VERSION "HNNBNNNYNNNNNNNNNNNNNNNNNNNNNNNNNNNNNNNNNN/4/%%%/4/'%**4NNN///"

NS_ :

BS_:

BU_: Airbag Allrad_Haldex BAP_Tester DCC_Gen3 EBKV_MQBW ESC_MQBW Gateway_Max Lenkhilfe_REPS

BO_ 2463978866 Gateway_81: 32 Gateway_Max
 SG_ LDW_02_alt : 0|1@1+ (1.0,0.0) [0.0|1] ""  Airbag
 SG_ TA_01_alt : 1|1@1+ (1.0,0.0) [0.0|1] ""  Airbag
 SG_ RDK_11_alt : 2|1@1+ (1.0,0.0) [0.0|1] ""  Airbag
 SG_ PLA_04_alt : 3|1@1+ (1.0,0.0) [0.0|1] ""  Airbag
 SG_ TPA_02_alt : 4|1@1+ (1.0,0.0) [0.0|1] ""  Airbag
 SG_ ARA_Status_01_alt : 5|1@1+ (1.0,0.0) [0.0|1] ""  Airbag
 SG_ WBA_05_alt : 6|1@1+ (1.0,0.0) [0.0|1] ""  Airbag
 SG_ KLR_01_alt : 7|1@1+ (1.0,0.0) [0.0|1] ""  Airbag
 SG_ Kamera_Status_alt : 8|1@1+ (1.0,0.0) [0.0|1] ""  Airbag
 SG_ RDK_02_alt : 10|1@1+ (1.0,0.0) [0.0|1] ""  Airbag
 SG_ PLA_06_alt : 11|1@1+ (1.0,0.0) [0.0|1] ""  Airbag
 SG_ LDW_Texte : 32|4@1+ (1.0,0.0) [0.0|15] ""  Airbag
 SG_ LDW_Lernmodus_seitenabhaengig : 36|4@1+ (1.0,0.0) [0.0|15] ""  Airbag
 SG_ LDW_Status_LED_gelb : 40|1@1+ (1.0,0.0) [0.0|1] ""  Airbag
 SG_ LDW_Status_LED_gruen : 41|1@1+ (1.0,0.0) [0.0|1] ""  Airbag
 SG_ TA_Status : 42|2@1+ (1.0,0.0) [0.0|3] ""  Airbag
 SG_ WBA_Status_AWU : 44|4@1+ (1.0,0.0) [0.0|15] ""  Airbag
 SG_ PLAIPA_PaCo_FunctionState : 48|5@1+ (1.0,0.0) [0.0|31] ""  Airbag
 SG_ PLAIPA_PaCo_MainState : 53|3@1+ (1.0,0.0) [0.0|7] ""  Airbag
 SG_ KLR_Touchauswertung : 56|4@1+ (1.0,0.0) [0.0|15] ""  Airbag
 SG_ TPA_Status : 60|4@1+ (1.0,0.0) [0.0|15] ""  Airbag
 SG_ ARA_Status : 64|4@1+ (1.0,0.0) [0.0|15] ""  Airbag
 SG_ TA_Texte_02 : 68|4@1+ (1.0,0.0) [0.0|15] ""  Airbag
 SG_ TA_Texte : 72|3@1+ (1.0,0.0) [0.0|7] ""  Airbag
 SG_ TA_Handsoff_LED : 75|2@1+ (1.0,0.0) [0.0|3] ""  Airbag
 SG_ TA_Fehler : 77|3@1+ (1.0,0.0) [0.0|7] ""  Airbag
 SG_ TA_aktiv_HMI : 80|2@1+ (1.0,0.0) [0.0|3] ""  Airbag
 SG_ TA_Spurwechsel : 82|3@1+ (1.0,0.0) [0.0|7] ""  Airbag
 SG_ VZE_Status_EDR : 85|3@1+ (1.0,0.0) [0.0|7] ""  Airbag
 SG_ TPMS_WarnLmpStP : 88|1@1+ (1.0,0.0) [0.0|1] ""  Airbag
 SG_ RDK_FMVSS138_Lampe : 101|1@1+ (1.0,0.0) [0.0|1] ""  Airbag
 SG_ LDW_Status_Anzeige : 102|3@1+ (1.0,0.0) [0.0|7] ""  Airbag
 SG_ TPMS_WarnLmpStMil : 105|1@1+ (1.0,0.0) [0.0|1] ""  Airbag
 SG_ RDK_FMVSS138_MIL : 106|1@1+ (1.0,0.0) [0.0|1] ""  Airbag
 SG_ RA_Status : 107|4@1+ (1.0,0.0) [0.0|15] ""  Airbag

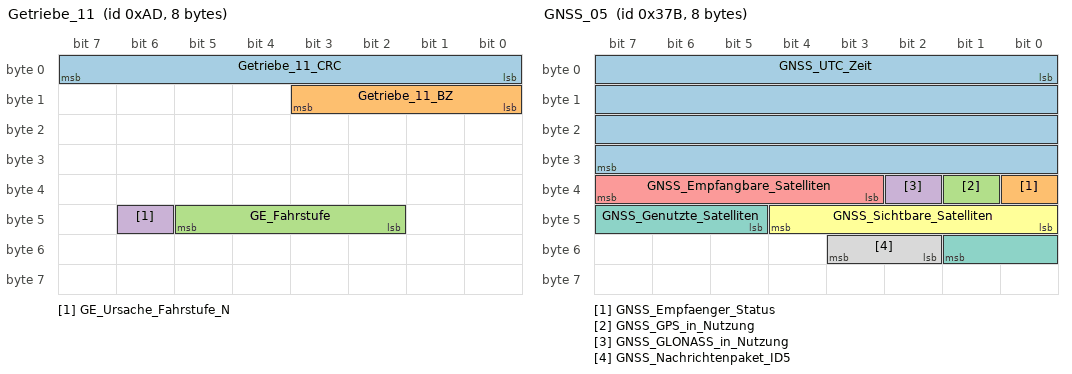
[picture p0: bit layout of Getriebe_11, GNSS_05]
BO_ 173 Getriebe_11: 8 Gateway_Max
 SG_ Getriebe_11_CRC : 0|8@1+ (1,0) [0|255] ""  Vector__XXX
 SG_ Getriebe_11_BZ : 8|4@1+ (1,0) [0|15] ""  Vector__XXX
 SG_ GE_Fahrstufe : 42|4@1+ (1.0,0.0) [0.0|15] ""  Airbag,EBKV_MQBW
 SG_ GE_Ursache_Fahrstufe_N : 46|1@1+ (1.0,0.0) [0.0|1] ""  Vector__XXX

BO_ 270 Getriebe_50: 48 Gateway_Max
 SG_ Getriebe_50_CRC : 0|8@1+ (1,0) [0|255] ""  ESC_MQBW
 SG_ Getriebe_50_BZ : 8|4@1+ (1,0) [0|15] ""  ESC_MQBW
 SG_ GE_MMom_Soll_02 : 12|10@1+ (1,-509) [-509|509] ""  Vector__XXX
 SG_ GE_MMom_Vorhalt_02 : 22|10@1+ (1,-509) [-509|509] ""  Vector__XXX
 SG_ GE_Uefkt : 32|10@1+ (0.1,0) [0.0|102.2] ""  EBKV_MQBW,ESC_MQBW
 SG_ GE2_Fahrstufe : 42|4@1+ (1.0,0.0) [0.0|15] ""  EBKV_MQBW,ESC_MQBW
 SG_ GE2_Ursache_Fahrstufe_N : 46|1@1+ (1.0,0.0) [0.0|1] ""  ESC_MQBW
 SG_ GE_Schaltablauf : 47|2@1+ (1.0,0.0) [0.0|3] ""  Allrad_Haldex,EBKV_MQBW,ESC_MQBW
 SG_ GE_Uefkt_unplausibel : 49|1@1+ (1.0,0.0) [0.0|1] ""  Vector__XXX
 SG_ GE_MMom_Status_02 : 50|3@1+ (1.0,0.0) [0.0|7] ""  Vector__XXX
 SG_ GE_Status_Kraftschluss : 53|3@1+ (1.0,0.0) [0.0|7] ""  ESC_MQBW
 SG_ GE_MMom_Status : 56|2@1+ (1.0,0.0) [0.0|3] ""  Vector__XXX
 SG_ GE_Freig_MMom_Vorhalt : 58|1@1+ (1.0,0.0) [0.0|1] ""  Vector__XXX
 SG_ GE_Verbot_Ausblendung : 59|1@1+ (1.0,0.0) [0.0|1] ""  Vector__XXX
 SG_ GE_Zielgang : 60|4@1+ (1.0,0.0) [0.0|15] ""  Allrad_Haldex,ESC_MQBW
 SG_ GE_Fahrstufenwunsch : 72|4@1+ (1.0,0.0) [0.0|15] ""  Vector__XXX
 SG_ GE_Drehzahlmesser_Daempfung : 76|1@1+ (1.0,0.0) [0.0|1] ""  Vector__XXX
 SG_ GE_Schubabschalt_Unt : 77|1@1+ (1.0,0.0) [0.0|1] ""  Vector__XXX
 SG_ GE_Freigabe_Synchro : 78|1@1+ (1.0,0.0) [0.0|1] ""  Vector__XXX
 SG_ GE_Synchro_Wunschdrehz : 79|9@1+ (25,0) [25|12750] "Unit_MinutInver"  Vector__XXX
 SG_ GE_Synchro_Zeit : 88|8@1+ (20,0) [0|5080] "Unit_MilliSecon"  Vector__XXX
 SG_ GE_Mom_Begr_Gradient : 96|8@1+ (10,0) [0|2540] "Unit_NewtoMeterPerSecon"  Vector__XXX
 SG_ GE_Anheb_Solldrehz_Leerlauf : 104|8@1+ (10,0) [0|2540] "Unit_MinutInver"  Vector__XXX
 SG_ GE_Aufnahmemoment : 112|10@1+ (1,-509) [-509|509] ""  Vector__XXX
 SG_ GE_Synchro_Status_02 : 122|4@1+ (1.0,0.0) [0.0|15] ""  Vector__XXX
 SG_ GE_StartStopp_Info : 140|2@1+ (1.0,0.0) [0.0|3] ""  Vector__XXX
 SG_ GE_Langfr_Schutzmom_02 : 142|9@1+ (1,0) [0|509] ""  Vector__XXX
 SG_ GE_Entkopplung_Status : 151|2@1+ (1.0,0.0) [0.0|3] ""  Vector__XXX
 SG_ GE_Verlustmoment : 160|8@1+ (1,0) [0|254] ""  ESC_MQBW
 SG_ GE_Anf_Zylabsch : 168|2@1+ (1.0,0.0) [0.0|3] ""  Vector__XXX
 SG_ GE_Grenzkriechmoment : 170|6@1+ (2,0) [0|122] ""  Vector__XXX
 SG_ GE_Eingangsdrehz : 176|14@1+ (1,0) [0|16381] "Unit_MinutInver"  Vector__XXX
 SG_ GE_Notlauf : 190|1@1+ (1.0,0.0) [0.0|1] ""  Vector__XXX
 SG_ GE_Freig_Langfr_Schutzmom : 191|1@1+ (1.0,0.0) [0.0|1] ""  Vector__XXX
 SG_ GE_HYB_Fehlerstatus : 204|2@1+ (1.0,0.0) [0.0|3] ""  Vector__XXX
 SG_ GE_HYB_DZ_Eingriff : 206|2@1+ (1.0,0.0) [0.0|3] ""  Vector__XXX
 SG_ GE_HYB_Freigabe_K0 : 208|1@1+ (1.0,0.0) [0.0|1] ""  Vector__XXX
 SG_ GE_HYB_MaxMomK0 : 209|2@1+ (1.0,0.0) [0.0|3] ""  Vector__XXX
 SG_ GE_HYB_Freig_VM_EM_Stop : 211|1@1+ (1.0,0.0) [0.0|1] ""  Vector__XXX
 SG_ GE_HYB_Wiederstart : 212|1@1+ (1.0,0.0) [0.0|1] ""  Vector__XXX
 SG_ GE_HYB_Filt_MomAufbau : 213|3@1+ (1.0,0.0) [0.0|7] ""  Vector__XXX
 SG_ GE_HYB_nK0 : 216|8@1+ (25,0) [0|6350] "Unit_MinutInver"  Vector__XXX
 SG_ GE_HYB_EM_KompMom : 224|7@1+ (2,0) [0|254] "Unit_NewtoMeter"  Vector__XXX
 SG_ GE_HYB_IstStatus_K0 : 231|2@1+ (1.0,0.0) [0.0|3] ""  ESC_MQBW
 SG_ GE_HYB_Wiederstartreserve : 233|7@1+ (2,0) [0|254] "Unit_NewtoMeter"  Vector__XXX
 SG_ GE_HYB_VM_Soll_Moment : 240|8@1+ (1.186,-50) [-50.000|250.058] "Unit_NewtoMeter"  Vector__XXX
 SG_ GE_HYB_Sportfaktor : 248|4@1+ (1.0,0.0) [0.0|15] ""  Vector__XXX
 SG_ GE_HYB_Freigabe_LL_Reg : 252|1@1+ (1.0,0.0) [0.0|1] ""  Vector__XXX
 SG_ GE_HYB_VM_akt_halten : 253|1@1+ (1.0,0.0) [0.0|1] ""  Vector__XXX
 SG_ GE_HYB_StartAnf : 254|1@1+ (1.0,0.0) [0.0|1] ""  Vector__XXX
 SG_ GE_HYB_VM_Startkontr : 255|1@1+ (1.0,0.0) [0.0|1] ""  Vector__XXX
 SG_ GE_Radmoment : 256|16@1+ (0.5,-16383) [-16383.0|16383.5] "Unit_NewtoMeter"  Vector__XXX
 SG_ GE_Abtriebsdrehzahl : 272|16@1+ (0.1,-3276.65) [-3276.65|3276.65] "Unit_MinutInver"  Vector__XXX
 SG_ GE_Eingangswellengradient : 288|16@1+ (0.25,-8191.5) [-8191.50|8191.75] "Unit_MeterInver"  Vector__XXX

BO_ 509 Getriebe_51: 32 Gateway_Max
 SG_ Getriebe_51_CRC : 0|8@1+ (1,0) [0|255] ""  ESC_MQBW
 SG_ Getriebe_51_BZ : 8|4@1+ (1,0) [0|15] ""  ESC_MQBW
 SG_ GE_OBD_AbsperrVent : 12|4@1+ (1.0,0.0) [0.0|15] ""  Vector__XXX
 SG_ GE_amax_moeglich : 16|9@1+ (0.024,-2.016) [-2.016|10.224] "Unit_MeterPerSeconSquar"  Vector__XXX
 SG_ GE_Charisma_FahrPr : 25|4@1+ (1.0,0.0) [0.0|15] ""  Vector__XXX
 SG_ GE_Charisma_Status : 29|2@1+ (1.0,0.0) [0.0|3] ""  Vector__XXX
 SG_ GE_Freigabe_Verfallsinfo_WFS : 31|1@1+ (1.0,0.0) [0.0|1] ""  Vector__XXX
 SG_ Freilauf_Charisma_FahrPr : 40|4@1+ (1.0,0.0) [0.0|15] ""  Vector__XXX
 SG_ Freilauf_Charisma_Status : 44|2@1+ (1.0,0.0) [0.0|3] ""  Vector__XXX
 SG_ GE_Freigabe_Info_WFS : 46|1@1+ (1.0,0.0) [0.0|1] ""  Vector__XXX
 SG_ GE_Sperr_Info_WFS : 47|1@1+ (1.0,0.0) [0.0|1] ""  Vector__XXX
 SG_ GE_Zustand_Kuppltemp : 48|2@1+ (1.0,0.0) [0.0|3] ""  Vector__XXX
 SG_ GE_Codierung_MSG : 50|1@1+ (1.0,0.0) [0.0|1] ""  Vector__XXX
 SG_ GE_LaunchControl : 51|1@1+ (1.0,0.0) [0.0|1] ""  Allrad_Haldex
 SG_ GE_Heizwunsch : 52|2@1+ (1.0,0.0) [0.0|3] ""  Vector__XXX
 SG_ GE_OBD_Status : 54|1@1+ (1.0,0.0) [0.0|1] ""  ESC_MQBW
 SG_ GE_LFR_Adaption : 55|1@1+ (1.0,0.0) [0.0|1] ""  Vector__XXX
 SG_ GE_Sumpftemperatur : 56|8@1+ (1,-58) [-58|196] "Unit_DegreCelsi"  Vector__XXX
 SG_ GE_Schleuderoeltemperatur : 64|8@1+ (1,-58) [-58|195] "Unit_DegreCelsi"  Vector__XXX
 SG_ GE_Weckleitung_aktiv : 72|1@1+ (1.0,0.0) [0.0|1] ""  Vector__XXX
 SG_ GE_Fahrprogramm : 76|4@1+ (1.0,0.0) [0.0|15] ""  Vector__XXX
 SG_ GE_TippZustand : 80|2@1+ (1.0,0.0) [0.0|3] ""  Vector__XXX
 SG_ GE_Freilauf_Status : 82|3@1+ (1.0,0.0) [0.0|7] ""  Allrad_Haldex,ESC_MQBW
 SG_ GE_Grundeinstellung : 85|1@1+ (1.0,0.0) [0.0|1] ""  Vector__XXX
 SG_ GE_Anschleppstart_Freigabe : 86|1@1+ (1.0,0.0) [0.0|1] ""  Vector__XXX
 SG_ GE_Strombedarf_erh : 87|1@1+ (1.0,0.0) [0.0|1] ""  Vector__XXX
 SG_ GE_Parken_WFS_Status : 88|2@1+ (1.0,0.0) [0.0|3] ""  Vector__XXX
 SG_ FSA_Fehlerstatus_Parksperre : 90|2@1+ (1.0,0.0) [0.0|3] ""  EBKV_MQBW
 SG_ GE_SpannungsAnf : 97|2@1+ (1.0,0.0) [0.0|3] ""  Vector__XXX
 SG_ GE_QBit_Sumpftemperatur : 99|1@1+ (1.0,0.0) [0.0|1] ""  Vector__XXX
 SG_ GE_Grundeinstell_Drehrichtung_EM : 100|1@1+ (1.0,0.0) [0.0|1] ""  Vector__XXX
 SG_ GE_Veto_Rollfaehigkeit : 101|1@1+ (1.0,0.0) [0.0|1] ""  Vector__XXX
 SG_ GE_Parken_beibehalten_HMS : 102|2@1+ (1.0,0.0) [0.0|3] ""  ESC_MQBW
 SG_ GE_Anforderung_HMS : 104|3@1+ (1.0,0.0) [0.0|7] ""  ESC_MQBW
 SG_ GE_Betaetigung_Hold : 107|1@1+ (1.0,0.0) [0.0|1] ""  Vector__XXX

BO_ 891 GNSS_05: 8 Gateway_Max
 SG_ GNSS_UTC_Zeit : 0|32@1+ (1,0) [1|4294967295] "Unit_Secon"  Airbag
 SG_ GNSS_Empfaenger_Status : 32|1@1+ (1.0,0.0) [0.0|1] ""  Vector__XXX
 SG_ GNSS_GPS_in_Nutzung : 33|1@1+ (1.0,0.0) [0.0|1] ""  Vector__XXX
 SG_ GNSS_GLONASS_in_Nutzung : 34|1@1+ (1.0,0.0) [0.0|1] ""  Vector__XXX
 SG_ GNSS_Empfangbare_Satelliten : 35|5@1+ (1,0) [1|30] "Unit_None"  Vector__XXX
 SG_ GNSS_Sichtbare_Satelliten : 40|5@1+ (1,0) [1|30] "Unit_None"  Vector__XXX
 SG_ GNSS_Genutzte_Satelliten : 45|5@1+ (1,0) [1|30] "Unit_None"  Vector__XXX
 SG_ GNSS_Nachrichtenpaket_ID5 : 50|2@1+ (1,0) [0|3] "Unit_Bit"  Vector__XXX

BO_ 771 HCA_03: 24 Gateway_Max
 SG_ HCA_QFK_AnfStat : 12|4@1+ (1.0,0.0) [0.0|15] ""  Lenkhilfe_REPS
 SG_ HCA_QFK_Spuerb : 16|8@1+ (0.4,0) [0.0|100.0] "Unit_PerCent"  Lenkhilfe_REPS
 SG_ HCA_QFK_KruemmSoll : 24|15@1+ (0.0000067,0) [0E-7|0.2195389] "Unit_MeterInver"  Lenkhilfe_REPS
 SG_ HCA_QFK_KruemmSoll_VZ : 39|1@1+ (1.0,0.0) [0.0|1] ""  Lenkhilfe_REPS
 SG_ HCA_QFK_Signal1 : 40|10@1+ (1,0) [0|1023] ""  Lenkhilfe_REPS
 SG_ HCA_QFK_Art1 : 50|3@1+ (1,0) [0|7] ""  Lenkhilfe_REPS
 SG_ HCA_QFK_Art2 : 53|3@1+ (1,0) [0|7] ""  Lenkhilfe_REPS
 SG_ HCA_QFK_Signal2 : 56|10@1+ (1,0) [0|1023] ""  Lenkhilfe_REPS
 SG_ HCA_03_Sendestatus : 66|1@1+ (1.0,0.0) [0.0|1] ""  Lenkhilfe_REPS
 SG_ HCA_QFK_KrSoll_VZ : 67|1@1+ (1.0,0.0) [0.0|1] ""  Lenkhilfe_REPS
 SG_ HCA_QFK_KrSoll : 128|16@1+ (0.0000067,0) [0E-7|0.4390778] "Unit_MeterInver"  Lenkhilfe_REPS
 SG_ SOK_HCA_03_Signatur : 144|48@1+ (1,0) [0|281474976710655] "Unit_None"  Vector__XXX

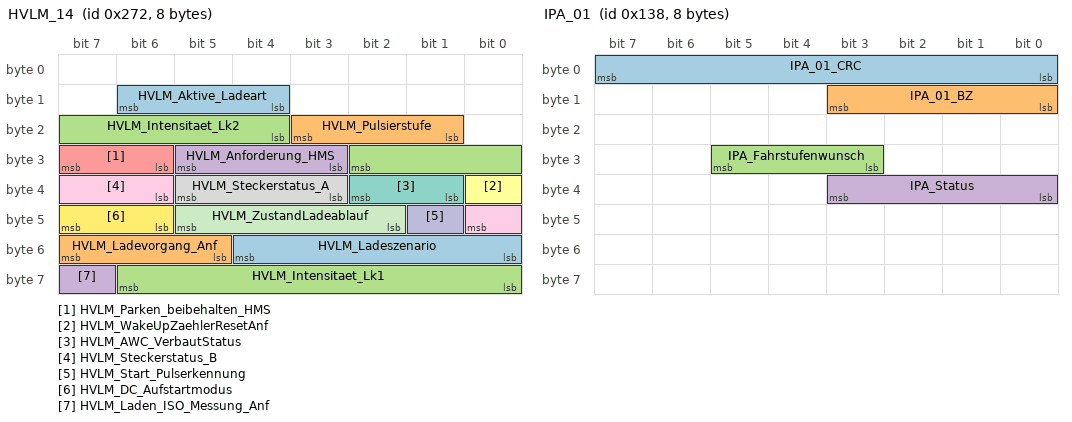
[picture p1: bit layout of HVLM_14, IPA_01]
BO_ 626 HVLM_14: 8 Gateway_Max
 SG_ HVLM_Aktive_Ladeart : 12|3@1+ (1.0,0.0) [0.0|7] ""  Vector__XXX
 SG_ HVLM_Pulsierstufe : 17|3@1+ (1.0,0.0) [0.0|7] ""  Vector__XXX
 SG_ HVLM_Intensitaet_Lk2 : 20|7@1+ (1,0) [0|100] "Unit_PerCent"  Vector__XXX
 SG_ HVLM_Anforderung_HMS : 27|3@1+ (1.0,0.0) [0.0|7] ""  ESC_MQBW
 SG_ HVLM_Parken_beibehalten_HMS : 30|2@1+ (1.0,0.0) [0.0|3] ""  ESC_MQBW
 SG_ HVLM_WakeUpZaehlerResetAnf : 32|1@1+ (1.0,0.0) [0.0|1] ""  Vector__XXX
 SG_ HVLM_AWC_VerbautStatus : 33|2@1+ (1.0,0.0) [0.0|3] ""  Vector__XXX
 SG_ HVLM_Steckerstatus_A : 35|3@1+ (1.0,0.0) [0.0|7] ""  Vector__XXX
 SG_ HVLM_Steckerstatus_B : 38|3@1+ (1.0,0.0) [0.0|7] ""  Vector__XXX
 SG_ HVLM_Start_Pulserkennung : 41|1@1+ (1.0,0.0) [0.0|1] ""  Vector__XXX
 SG_ HVLM_ZustandLadeablauf : 42|4@1+ (1.0,0.0) [0.0|15] ""  Vector__XXX
 SG_ HVLM_DC_Aufstartmodus : 46|2@1+ (1.0,0.0) [0.0|3] ""  Vector__XXX
 SG_ HVLM_Ladeszenario : 48|5@1+ (1.0,0.0) [0.0|31] ""  Vector__XXX
 SG_ HVLM_Ladevorgang_Anf : 53|3@1+ (1.0,0.0) [0.0|7] ""  Vector__XXX
 SG_ HVLM_Intensitaet_Lk1 : 56|7@1+ (1,0) [0|100] "Unit_PerCent"  Vector__XXX
 SG_ HVLM_Laden_ISO_Messung_Anf : 63|1@1+ (1.0,0.0) [0.0|1] ""  Vector__XXX

BO_ 2589283966 IMU_03: 8 Airbag
 SG_ IMU_StObd_StFail1 : 12|1@1+ (1.0,0.0) [0.0|1] ""  ESC_MQBW
 SG_ IMU_StObd_StFail2 : 13|1@1+ (1.0,0.0) [0.0|1] ""  ESC_MQBW
 SG_ IMU_StObd_StFail3 : 14|1@1+ (1.0,0.0) [0.0|1] ""  ESC_MQBW
 SG_ IMU_StObd_StFail4 : 15|1@1+ (1.0,0.0) [0.0|1] ""  ESC_MQBW
 SG_ IMU_StObd_StFail5 : 16|1@1+ (1.0,0.0) [0.0|1] ""  ESC_MQBW
 SG_ IMU_StObd_StFail6 : 17|1@1+ (1.0,0.0) [0.0|1] ""  ESC_MQBW
 SG_ IMU_StObd_StFail7 : 18|1@1+ (1.0,0.0) [0.0|1] ""  ESC_MQBW
 SG_ IMU_StObd_StFail8 : 19|1@1+ (1.0,0.0) [0.0|1] ""  ESC_MQBW
 SG_ IMU_StObd_StFail9 : 20|1@1+ (1.0,0.0) [0.0|1] ""  ESC_MQBW
 SG_ IMU_StObd_StFail10 : 21|1@1+ (1.0,0.0) [0.0|1] ""  ESC_MQBW
 SG_ IMU_StObd_StFail11 : 22|1@1+ (1.0,0.0) [0.0|1] ""  ESC_MQBW
 SG_ IMU_StObd_StChk1 : 23|1@1+ (1.0,0.0) [0.0|1] ""  ESC_MQBW
 SG_ IMU_StObd_StChk2 : 24|1@1+ (1.0,0.0) [0.0|1] ""  ESC_MQBW
 SG_ IMU_StObd_StChk3 : 25|1@1+ (1.0,0.0) [0.0|1] ""  ESC_MQBW
 SG_ IMU_StObd_StChk4 : 26|1@1+ (1.0,0.0) [0.0|1] ""  ESC_MQBW
 SG_ IMU_StObd_StChk5 : 27|1@1+ (1.0,0.0) [0.0|1] ""  ESC_MQBW
 SG_ IMU_StObd_StChk6 : 28|1@1+ (1.0,0.0) [0.0|1] ""  ESC_MQBW
 SG_ IMU_StObd_StChk7 : 29|1@1+ (1.0,0.0) [0.0|1] ""  ESC_MQBW
 SG_ IMU_StObd_StChk8 : 30|1@1+ (1.0,0.0) [0.0|1] ""  ESC_MQBW
 SG_ IMU_StObd_StChk9 : 31|1@1+ (1.0,0.0) [0.0|1] ""  ESC_MQBW
 SG_ IMU_StObd_StChk10 : 32|1@1+ (1.0,0.0) [0.0|1] ""  ESC_MQBW
 SG_ IMU_StObd_StChk11 : 33|1@1+ (1.0,0.0) [0.0|1] ""  ESC_MQBW

BO_ 182 IMU_05: 32 Airbag
 SG_ IMU_05_CRC : 0|8@1+ (1,0) [0|255] ""  ESC_MQBW,Gateway_Max
 SG_ IMU_05_BZ : 8|4@1+ (1,0) [0|15] ""  ESC_MQBW,Gateway_Max
 SG_ IMU_ALat_Qlfr : 12|4@1+ (1.0,0.0) [0.0|15] ""  ESC_MQBW,Gateway_Max
 SG_ IMU_ALat : 16|16@1+ (0.005,-163.84) [-163.835|163.825] "Unit_MeterPerSeconSquar"  ESC_MQBW,Gateway_Max
 SG_ IMU_ALgt : 32|16@1+ (0.005,-163.84) [-163.835|163.825] "Unit_MeterPerSeconSquar"  EBKV_MQBW,ESC_MQBW,Gateway_Max
 SG_ IMU_ALgt_Qlfr : 48|4@1+ (1.0,0.0) [0.0|15] ""  EBKV_MQBW,ESC_MQBW,Gateway_Max
 SG_ IMU_PitchRate_Qlfr : 52|4@1+ (1.0,0.0) [0.0|15] ""  Gateway_Max
 SG_ IMU_PitchRate : 56|16@1+ (0.01,-327.68) [-327.67|327.65] "Unit_DegreOfArcPerSecon"  DCC_Gen3,Gateway_Max
 SG_ IMU_AVert : 72|16@1+ (0.005,-163.84) [-163.835|163.825] "Unit_MeterPerSeconSquar"  DCC_Gen3,Gateway_Max
 SG_ IMU_AVert_Qlfr : 88|4@1+ (1.0,0.0) [0.0|15] ""  Gateway_Max
 SG_ IMU_YawRate_Qlfr : 92|4@1+ (1.0,0.0) [0.0|15] ""  ESC_MQBW,Gateway_Max
 SG_ IMU_YawRate : 96|16@1+ (0.01,-327.68) [-327.67|327.65] "Unit_DegreOfArcPerSecon"  ESC_MQBW,Gateway_Max
 SG_ IMU_RollRate : 112|16@1+ (0.01,-327.68) [-327.67|327.65] "Unit_DegreOfArcPerSecon"  DCC_Gen3,ESC_MQBW,Gateway_Max
 SG_ IMU_RollRate_Qlfr : 128|4@1+ (1.0,0.0) [0.0|15] ""  ESC_MQBW,Gateway_Max
 SG_ IMU_MeasurementTimeLow : 150|10@1+ (1,0) [0|999] "Unit_MilliSecon"  Gateway_Max
 SG_ IMU_MeasurementTimeHigh : 160|32@1+ (1,0) [0|4294967294] "Unit_Secon"  Gateway_Max
 SG_ SOK_IMU_05_Signatur : 192|64@1+ (1,0) [0|18446744073709551615] "Unit_None"  Gateway_Max

BO_ 312 IPA_01: 8 Gateway_Max
 SG_ IPA_01_CRC : 0|8@1+ (1,0) [0|255] ""  ESC_MQBW
 SG_ IPA_01_BZ : 8|4@1+ (1,0) [0|15] ""  ESC_MQBW
 SG_ IPA_Fahrstufenwunsch : 27|3@1+ (1.0,0.0) [0.0|7] ""  Vector__XXX
 SG_ IPA_Status : 32|4@1+ (1.0,0.0) [0.0|15] ""  ESC_MQBW

BO_ 2527679583 IPA_02: 8 Gateway_Max
 SG_ IPA_02_CRC : 0|8@1+ (1,0) [0|255] ""  Vector__XXX
 SG_ IPA_02_BZ : 8|4@1+ (1,0) [0|15] ""  Vector__XXX
 SG_ IPA_PL_Anzeige_links : 12|2@1+ (1.0,0.0) [0.0|3] ""  Vector__XXX
 SG_ IPA_PL_Anzeige_rechts : 14|2@1+ (1.0,0.0) [0.0|3] ""  Vector__XXX
 SG_ Parken_Seitenspiegel_Anf : 20|2@1+ (1.0,0.0) [0.0|3] ""  Vector__XXX
 SG_ Parken_ZV_Schliessen : 22|2@1+ (1.0,0.0) [0.0|3] ""  Vector__XXX
 SG_ Parken_aktives_System_02 : 24|5@1+ (1.0,0.0) [0.0|31] ""  ESC_MQBW
 SG_ Parken_ZR_Sondermodus_Anf : 29|2@1+ (1.0,0.0) [0.0|3] ""  Vector__XXX
 SG_ Parken_Schluesselsuche_Anf : 31|1@1+ (1.0,0.0) [0.0|1] ""  Vector__XXX
 SG_ Parken_FFB_LED_Anf : 32|2@1+ (1.0,0.0) [0.0|3] ""  Vector__XXX
 SG_ Parken_Wegfahrsperren_Anf : 34|2@1+ (1.0,0.0) [0.0|3] ""  Vector__XXX
 SG_ Parken_Aktivierungslicht_Anf : 36|1@1+ (1.0,0.0) [0.0|1] ""  Vector__XXX
 SG_ Parken_Fahrtrichtungslicht_Anf : 37|2@1+ (1.0,0.0) [0.0|3] ""  Vector__XXX
 SG_ Parken_Lichtnachlauf_Anf : 39|1@1+ (1.0,0.0) [0.0|1] ""  Vector__XXX
 SG_ IPA_Akustik_PL_gefunden : 45|1@1+ (1.0,0.0) [0.0|1] ""  Vector__XXX
 SG_ Parken_Blinker_li_Anf : 46|1@1+ (1.0,0.0) [0.0|1] ""  Vector__XXX
 SG_ Parken_Blinker_re_Anf : 47|1@1+ (1.0,0.0) [0.0|1] ""  Vector__XXX
 SG_ Parken_Fahrerhinweise_Anf : 51|1@1+ (1.0,0.0) [0.0|1] ""  Vector__XXX
 SG_ Parken_Bestaetigungsblinken_Anf : 52|2@1+ (1.0,0.0) [0.0|3] ""  Vector__XXX
 SG_ Parken_Fahrbereitschaftlicht_Anf : 54|1@1+ (1.0,0.0) [0.0|1] ""  Vector__XXX
 SG_ Parken_Lichtsteuerung_Anf : 55|1@1+ (1.0,0.0) [0.0|1] ""  Vector__XXX
 SG_ IPA_Anf_Meldungen : 56|8@1+ (1.0,0.0) [0.0|255] ""  Vector__XXX

BO_ 1811 ISO_ABS_Req: 8 Gateway_Max
 SG_ ISO_ABS_Req_Data : 0|64@1+ (1.0,0.0) [0.0|18446744073709551615] ""  ESC_MQBW

BO_ 1917 ISO_ABS_Resp: 8 ESC_MQBW
 SG_ ISO_ABS_Resp_Data : 0|64@1+ (1.0,0.0) [0.0|18446744073709551615] ""  Gateway_Max

BO_ 1813 ISO_Airbag_01_Req: 8 Gateway_Max
 SG_ ISO_Airbag_01_Req_Data : 0|64@1+ (1.0,0.0) [0.0|18446744073709551615] ""  Airbag

BO_ 1919 ISO_Airbag_01_Resp: 8 Airbag
 SG_ ISO_Airbag_01_Resp_Data : 0|64@1+ (1.0,0.0) [0.0|18446744073709551615] ""  Gateway_Max

BO_ 1807 ISO_Allrad_Req: 8 Gateway_Max
 SG_ ISO_Allrad_Req_Data : 0|64@1+ (1.0,0.0) [0.0|18446744073709551615] ""  Allrad_Haldex

BO_ 1913 ISO_Allrad_Resp: 8 Allrad_Haldex
 SG_ ISO_Allrad_Resp_Data : 0|64@1+ (1.0,0.0) [0.0|18446744073709551615] ""  Gateway_Max

BO_ 1906 ISO_Daempfer_Req: 8 Gateway_Max
 SG_ ISO_Daempfer_Req_Data : 0|64@1+ (1.0,0.0) [0.0|18446744073709551615] ""  DCC_Gen3

BO_ 2012 ISO_Daempfer_Resp: 8 DCC_Gen3
 SG_ ISO_Daempfer_Resp_Data : 0|64@1+ (1.0,0.0) [0.0|18446744073709551615] ""  Gateway_Max

BO_ 1851 ISO_EBKV_Req: 8 Gateway_Max
 SG_ ISO_EBKV_Req_Data : 0|64@1+ (1.0,0.0) [0.0|18446744073709551615] ""  EBKV_MQBW

BO_ 1957 ISO_EBKV_Resp: 8 EBKV_MQBW
 SG_ ISO_EBKV_Resp_Data : 0|64@1+ (1.0,0.0) [0.0|18446744073709551615] ""  Gateway_Max

BO_ 1792 ISO_Funktionaler_Req_All: 8 Gateway_Max
 SG_ ISO_ALL_01_Req_Data : 0|64@1+ (1.0,0.0) [0.0|18446744073709551615] ""  Airbag,Allrad_Haldex,DCC_Gen3,EBKV_MQBW,ESC_MQBW,Lenkhilfe_REPS

BO_ 1810 ISO_Lenkhilfe_Req: 8 Gateway_Max
 SG_ ISO_Lenkhilfe_Req_Data : 0|64@1+ (1.0,0.0) [0.0|18446744073709551615] ""  Lenkhilfe_REPS

BO_ 1916 ISO_Lenkhilfe_Resp: 8 Lenkhilfe_REPS
 SG_ ISO_Lenkhilfe_Resp_Data : 0|64@1+ (1.0,0.0) [0.0|18446744073709551615] ""  Gateway_Max

BO_ 1822 ISO_Quersperre_Req: 8 Gateway_Max
 SG_ ISO_Quersperre_Req_Data : 0|64@1+ (1.0,0.0) [0.0|18446744073709551615] ""  Vector__XXX

BO_ 1928 ISO_Quersperre_Resp: 8 Vector__XXX
 SG_ ISO_Quersperre_Resp_Data : 0|64@1+ (1.0,0.0) [0.0|18446744073709551615] ""  Gateway_Max

BO_ 2621440019 ISOx_ABS_Req_FD: 64 Gateway_Max
 SG_ ISOx_ABS_Req_FD_Data : 0|512@1+ (1.0,0.0) [0.0|13407807929942597099574024998205846127479365820592393377723561443721764030073546976801874298166903427690031858186486050853753882811946569946433649006084095] ""  ESC_MQBW

BO_ 2621571091 ISOx_ABS_Resp_FD: 64 ESC_MQBW
 SG_ ISOx_ABS_Resp_FD_Data : 0|512@1+ (1.0,0.0) [0.0|13407807929942597099574024998205846127479365820592393377723561443721764030073546976801874298166903427690031858186486050853753882811946569946433649006084095] ""  Gateway_Max

BO_ 2621440021 ISOx_Airbag_01_Req_FD: 64 Gateway_Max
 SG_ ISOx_Airbag_01_Req_FD_Data : 0|512@1+ (1.0,0.0) [0.0|13407807929942597099574024998205846127479365820592393377723561443721764030073546976801874298166903427690031858186486050853753882811946569946433649006084095] ""  Airbag

BO_ 2621571093 ISOx_Airbag_01_Resp_FD: 64 Airbag
 SG_ ISOx_Airbag_01_Resp_FD_Data : 0|512@1+ (1.0,0.0) [0.0|13407807929942597099574024998205846127479365820592393377723561443721764030073546976801874298166903427690031858186486050853753882811946569946433649006084095] ""  Gateway_Max

BO_ 2621440015 ISOx_Allrad_Req_FD: 64 Gateway_Max
 SG_ ISOx_Allrad_Req_FD_Data : 0|512@1+ (1.0,0.0) [0.0|13407807929942597099574024998205846127479365820592393377723561443721764030073546976801874298166903427690031858186486050853753882811946569946433649006084095] ""  Allrad_Haldex

BO_ 2621571087 ISOx_Allrad_Resp_FD: 64 Allrad_Haldex
 SG_ ISOx_Allrad_Resp_FD_Data : 0|512@1+ (1.0,0.0) [0.0|13407807929942597099574024998205846127479365820592393377723561443721764030073546976801874298166903427690031858186486050853753882811946569946433649006084095] ""  Gateway_Max

BO_ 2621440114 ISOx_Daempfer_Req_FD: 64 Gateway_Max
 SG_ ISOx_Daempfer_Req_FD_Data : 0|512@1+ (1.0,0.0) [0.0|13407807929942597099574024998205846127479365820592393377723561443721764030073546976801874298166903427690031858186486050853753882811946569946433649006084095] ""  DCC_Gen3

BO_ 2621571186 ISOx_Daempfer_Resp_FD: 64 DCC_Gen3
 SG_ ISOx_Daempfer_Resp_FD_Data : 0|512@1+ (1.0,0.0) [0.0|13407807929942597099574024998205846127479365820592393377723561443721764030073546976801874298166903427690031858186486050853753882811946569946433649006084095] ""  Gateway_Max

BO_ 2621440059 ISOx_EBKV_Req_FD: 64 Gateway_Max
 SG_ ISOx_EBKV_Req_FD_Data : 0|512@1+ (1.0,0.0) [0.0|13407807929942597099574024998205846127479365820592393377723561443721764030073546976801874298166903427690031858186486050853753882811946569946433649006084095] ""  EBKV_MQBW

BO_ 2621571131 ISOx_EBKV_Resp_FD: 64 EBKV_MQBW
 SG_ ISOx_EBKV_Resp_FD_Data : 0|512@1+ (1.0,0.0) [0.0|13407807929942597099574024998205846127479365820592393377723561443721764030073546976801874298166903427690031858186486050853753882811946569946433649006084095] ""  Gateway_Max

BO_ 2621505536 ISOx_Funkt_Req_All_FD: 64 Gateway_Max
 SG_ ISOx_Funkt_Req_All_FD_Data : 0|512@1+ (1.0,0.0) [0.0|13407807929942597099574024998205846127479365820592393377723561443721764030073546976801874298166903427690031858186486050853753882811946569946433649006084095] ""  Airbag,Allrad_Haldex,DCC_Gen3,EBKV_MQBW,ESC_MQBW,Lenkhilfe_REPS

BO_ 2621440018 ISOx_Lenkhilfe_Req_FD: 64 Gateway_Max
 SG_ ISOx_Lenkhilfe_Req_FD_Data : 0|512@1+ (1.0,0.0) [0.0|13407807929942597099574024998205846127479365820592393377723561443721764030073546976801874298166903427690031858186486050853753882811946569946433649006084095] ""  Lenkhilfe_REPS

BO_ 2621571090 ISOx_Lenkhilfe_Resp_FD: 64 Lenkhilfe_REPS
 SG_ ISOx_Lenkhilfe_Resp_FD_Data : 0|512@1+ (1.0,0.0) [0.0|13407807929942597099574024998205846127479365820592393377723561443721764030073546976801874298166903427690031858186486050853753882811946569946433649006084095] ""  Gateway_Max

BO_ 2621440030 ISOx_Quersperre_Req_FD: 64 Gateway_Max
 SG_ ISOx_Quersperre_Req_FD_Data : 0|512@1+ (1.0,0.0) [0.0|13407807929942597099574024998205846127479365820592393377723561443721764030073546976801874298166903427690031858186486050853753882811946569946433649006084095] ""  Vector__XXX

BO_ 2621571102 ISOx_Quersperre_Resp_FD: 64 Vector__XXX
 SG_ ISOx_Quersperre_Resp_FD_Data : 0|512@1+ (1.0,0.0) [0.0|13407807929942597099574024998205846127479365820592393377723561443721764030073546976801874298166903427690031858186486050853753882811946569946433649006084095] ""  Gateway_Max

BO_ 2549874892 ISOx_TSplit_L_Req: 8 Gateway_Max
 SG_ ISOx_TSplit_L_Req_Data : 0|64@1+ (1.0,0.0) [0.0|18446744073709551615] ""  Vector__XXX

BO_ 2621440204 ISOx_TSplit_L_Req_FD: 64 Gateway_Max
 SG_ ISOx_TSplit_L_Req_FD_Data : 0|512@1+ (1.0,0.0) [0.0|13407807929942597099574024998205846127479365820592393377723561443721764030073546976801874298166903427690031858186486050853753882811946569946433649006084095] ""  Vector__XXX

BO_ 2550005964 ISOx_TSplit_L_Resp: 8 Vector__XXX
 SG_ ISOx_TSplit_L_Resp_Data : 0|64@1+ (1.0,0.0) [0.0|18446744073709551615] ""  Gateway_Max

BO_ 2621571276 ISOx_TSplit_L_Resp_FD: 64 Vector__XXX
 SG_ ISOx_TSplit_L_Resp_FD_Data : 0|512@1+ (1.0,0.0) [0.0|13407807929942597099574024998205846127479365820592393377723561443721764030073546976801874298166903427690031858186486050853753882811946569946433649006084095] ""  Gateway_Max

BO_ 2549874893 ISOx_TSplit_R_Req: 8 Gateway_Max
 SG_ ISOx_TSplit_R_Req_Data : 0|64@1+ (1.0,0.0) [0.0|18446744073709551615] ""  Vector__XXX

BO_ 2621440205 ISOx_TSplit_R_Req_FD: 64 Gateway_Max
 SG_ ISOx_TSplit_R_Req_FD_Data : 0|512@1+ (1.0,0.0) [0.0|13407807929942597099574024998205846127479365820592393377723561443721764030073546976801874298166903427690031858186486050853753882811946569946433649006084095] ""  Vector__XXX

BO_ 2550005965 ISOx_TSplit_R_Resp: 8 Vector__XXX
 SG_ ISOx_TSplit_R_Resp_Data : 0|64@1+ (1.0,0.0) [0.0|18446744073709551615] ""  Gateway_Max

BO_ 2621571277 ISOx_TSplit_R_Resp_FD: 64 Vector__XXX
 SG_ ISOx_TSplit_R_Resp_FD_Data : 0|512@1+ (1.0,0.0) [0.0|13407807929942597099574024998205846127479365820592393377723561443721764030073546976801874298166903427690031858186486050853753882811946569946433649006084095] ""  Gateway_Max

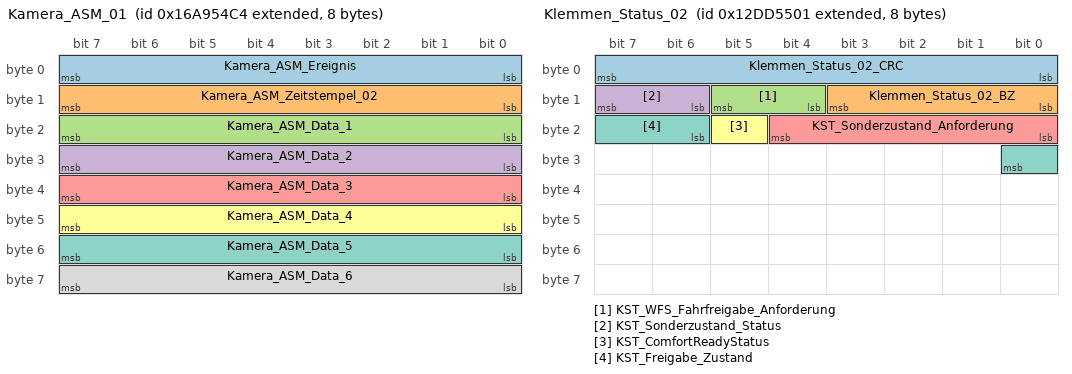
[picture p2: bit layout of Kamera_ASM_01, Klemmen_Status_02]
BO_ 2527679684 Kamera_ASM_01: 8 Gateway_Max
 SG_ Kamera_ASM_Ereignis : 0|8@1+ (1,0) [1|254] ""  Airbag
 SG_ Kamera_ASM_Zeitstempel_02 : 8|8@1+ (0.04,0) [0.00|10.16] "Unit_Secon"  Airbag
 SG_ Kamera_ASM_Data_1 : 16|8@1+ (1,0) [0|255] ""  Airbag
 SG_ Kamera_ASM_Data_2 : 24|8@1+ (1,0) [0|255] ""  Airbag
 SG_ Kamera_ASM_Data_3 : 32|8@1+ (1,0) [0|255] ""  Airbag
 SG_ Kamera_ASM_Data_4 : 40|8@1+ (1,0) [0|255] ""  Airbag
 SG_ Kamera_ASM_Data_5 : 48|8@1+ (1,0) [0|255] ""  Airbag
 SG_ Kamera_ASM_Data_6 : 56|8@1+ (1,0) [0|255] ""  Airbag

BO_ 960 Klemmen_Status_01: 4 Gateway_Max
 SG_ Klemmen_Status_01_CRC : 0|8@1+ (1,0) [0|255] ""  Airbag,EBKV_MQBW,ESC_MQBW
 SG_ Klemmen_Status_01_BZ : 8|4@1+ (1,0) [0|15] ""  Airbag,EBKV_MQBW,ESC_MQBW
 SG_ RSt_Fahrerhinweise : 12|4@1+ (1.0,0.0) [0.0|15] ""  Vector__XXX
 SG_ ZAS_Kl_S : 16|1@1+ (1.0,0.0) [0.0|1] ""  Airbag
 SG_ ZAS_Kl_15 : 17|1@1+ (1.0,0.0) [0.0|1] ""  Airbag,DCC_Gen3,EBKV_MQBW,ESC_MQBW,Lenkhilfe_REPS
 SG_ ZAS_Kl_X : 18|1@1+ (1.0,0.0) [0.0|1] ""  Vector__XXX
 SG_ ZAS_Kl_50_Startanforderung : 19|1@1+ (1.0,0.0) [0.0|1] ""  Vector__XXX
 SG_ BCM_Remotestart_Betrieb : 20|1@1+ (1.0,0.0) [0.0|1] ""  Vector__XXX
 SG_ ZAS_Kl_Infotainment : 21|1@1+ (1.0,0.0) [0.0|1] ""  Vector__XXX
 SG_ BCM_Remotestart_KL15_Anf : 22|1@1+ (1.0,0.0) [0.0|1] ""  Vector__XXX
 SG_ BCM_Remotestart_MO_Start : 23|1@1+ (1.0,0.0) [0.0|1] ""  Vector__XXX
 SG_ KST_Warn_P1_ZST_def : 24|1@1+ (1.0,0.0) [0.0|1] ""  Vector__XXX
 SG_ KST_Warn_P2_ZST_def : 25|1@1+ (1.0,0.0) [0.0|1] ""  Vector__XXX
 SG_ KST_Fahrerhinweis_1 : 26|1@1+ (1.0,0.0) [0.0|1] ""  Vector__XXX
 SG_ KST_Fahrerhinweis_2 : 27|1@1+ (1.0,0.0) [0.0|1] ""  Vector__XXX
 SG_ BCM_Ausparken_Betrieb : 28|1@1+ (1.0,0.0) [0.0|1] ""  Vector__XXX
 SG_ KST_Fahrerhinweis_4 : 29|1@1+ (1.0,0.0) [0.0|1] ""  Vector__XXX
 SG_ KST_Fahrerhinweis_5 : 30|1@1+ (1.0,0.0) [0.0|1] ""  Vector__XXX
 SG_ KST_Fahrerhinweis_6 : 31|1@1+ (1.0,0.0) [0.0|1] ""  Vector__XXX

BO_ 2463978753 Klemmen_Status_02: 8 Gateway_Max
 SG_ Klemmen_Status_02_CRC : 0|8@1+ (1,0) [0|255] ""  Vector__XXX
 SG_ Klemmen_Status_02_BZ : 8|4@1+ (1,0) [0|15] ""  Vector__XXX
 SG_ KST_WFS_Fahrfreigabe_Anforderung : 12|2@1+ (1.0,0.0) [0.0|3] ""  Vector__XXX
 SG_ KST_Sonderzustand_Status : 14|2@1+ (1.0,0.0) [0.0|3] ""  Airbag,EBKV_MQBW,ESC_MQBW
 SG_ KST_Sonderzustand_Anforderung : 16|5@1+ (1.0,0.0) [0.0|31] ""  Airbag,EBKV_MQBW,ESC_MQBW
 SG_ KST_ComfortReadyStatus : 21|1@1+ (1.0,0.0) [0.0|1] ""  Vector__XXX
 SG_ KST_Freigabe_Zustand : 22|3@1+ (1.0,0.0) [0.0|7] ""  Vector__XXX

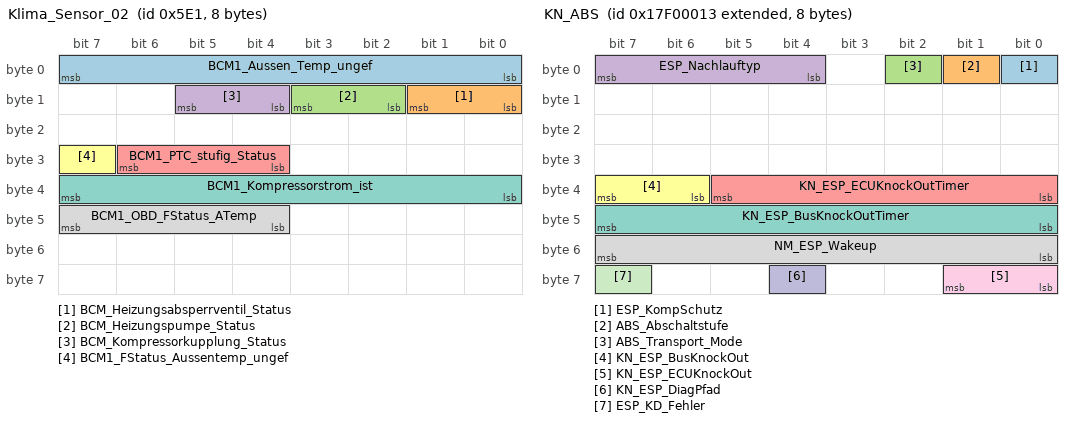
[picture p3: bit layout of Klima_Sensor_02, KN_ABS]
BO_ 1505 Klima_Sensor_02: 8 Gateway_Max
 SG_ BCM1_Aussen_Temp_ungef : 0|8@1+ (0.5,-50) [-50.0|76.0] "Unit_DegreCelsi"  Airbag,ESC_MQBW
 SG_ BCM_Heizungsabsperrventil_Status : 8|2@1+ (1.0,0.0) [0.0|3] ""  Vector__XXX
 SG_ BCM_Heizungspumpe_Status : 10|2@1+ (1.0,0.0) [0.0|3] ""  Vector__XXX
 SG_ BCM_Kompressorkupplung_Status : 12|2@1+ (1.0,0.0) [0.0|3] ""  Vector__XXX
 SG_ BCM1_PTC_stufig_Status : 28|3@1+ (1.0,0.0) [0.0|7] ""  Vector__XXX
 SG_ BCM1_FStatus_Aussentemp_ungef : 31|1@1+ (1.0,0.0) [0.0|1] ""  Airbag
 SG_ BCM1_Kompressorstrom_ist : 32|8@1+ (4,0) [0|1000] "Unit_MilliAmper"  Vector__XXX
 SG_ BCM1_OBD_FStatus_ATemp : 44|4@1+ (1.0,0.0) [0.0|15] ""  ESC_MQBW

BO_ 2549088275 KN_ABS: 8 ESC_MQBW
 SG_ ESP_KompSchutz : 0|1@1+ (1.0,0.0) [0.0|1] ""  Vector__XXX
 SG_ ABS_Abschaltstufe : 1|1@1+ (1.0,0.0) [0.0|1] ""  Vector__XXX
 SG_ ABS_Transport_Mode : 2|1@1+ (1.0,0.0) [0.0|1] ""  Vector__XXX
 SG_ ESP_Nachlauftyp : 4|4@1+ (1.0,0.0) [0.0|15] ""  Gateway_Max
 SG_ KN_ESP_ECUKnockOutTimer : 32|6@1+ (1,0) [0|62] "Unit_Minut"  Vector__XXX
 SG_ KN_ESP_BusKnockOut : 38|2@1+ (1.0,0.0) [0.0|3] ""  Vector__XXX
 SG_ KN_ESP_BusKnockOutTimer : 40|8@1+ (1,0) [0|254] ""  Vector__XXX
 SG_ NM_ESP_Wakeup : 48|8@1+ (1.0,0.0) [0.0|255] ""  Vector__XXX
 SG_ KN_ESP_ECUKnockOut : 56|2@1+ (1.0,0.0) [0.0|3] ""  Vector__XXX
 SG_ KN_ESP_DiagPfad : 60|1@1+ (1.0,0.0) [0.0|1] ""  Gateway_Max
 SG_ ESP_KD_Fehler : 63|1@1+ (1.0,0.0) [0.0|1] ""  Gateway_Max

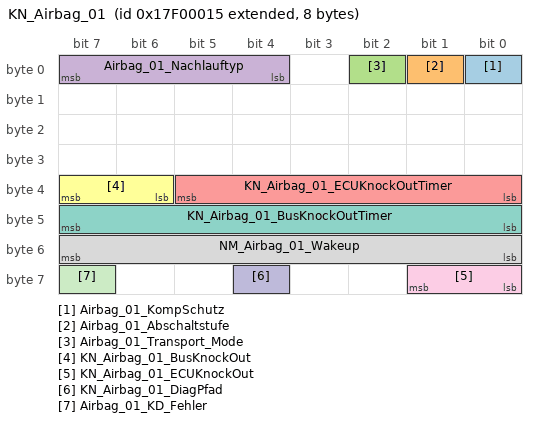
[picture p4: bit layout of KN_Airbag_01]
BO_ 2549088277 KN_Airbag_01: 8 Airbag
 SG_ Airbag_01_KompSchutz : 0|1@1+ (1.0,0.0) [0.0|1] ""  Vector__XXX
 SG_ Airbag_01_Abschaltstufe : 1|1@1+ (1.0,0.0) [0.0|1] ""  Vector__XXX
 SG_ Airbag_01_Transport_Mode : 2|1@1+ (1.0,0.0) [0.0|1] ""  Vector__XXX
 SG_ Airbag_01_Nachlauftyp : 4|4@1+ (1.0,0.0) [0.0|15] ""  Gateway_Max
 SG_ KN_Airbag_01_ECUKnockOutTimer : 32|6@1+ (1,0) [0|62] ""  Vector__XXX
 SG_ KN_Airbag_01_BusKnockOut : 38|2@1+ (1.0,0.0) [0.0|3] ""  Vector__XXX
 SG_ KN_Airbag_01_BusKnockOutTimer : 40|8@1+ (1,0) [0|254] ""  Vector__XXX
 SG_ NM_Airbag_01_Wakeup : 48|8@1+ (1.0,0.0) [0.0|255] ""  Vector__XXX
 SG_ KN_Airbag_01_ECUKnockOut : 56|2@1+ (1.0,0.0) [0.0|3] ""  Vector__XXX
 SG_ KN_Airbag_01_DiagPfad : 60|1@1+ (1.0,0.0) [0.0|1] ""  Gateway_Max
 SG_ Airbag_01_KD_Fehler : 63|1@1+ (1.0,0.0) [0.0|1] ""  Gateway_Max

CM_ BO_ 891 "Nachricht 5:
Empfängerstatus und UTC.";
CM_ BO_ 2527679583 "ehemals ZFAS_01";
CM_ BO_ 2621505536 "VWAG Diagnose funktionaler Request auf CANFD";
CM_ BO_ 960 "MQB";
CM_ BO_ 1505 "ab MQB 7.3";

CM_ SG_ 2463978866 ARA_Status "Status of ARA Controller";
CM_ SG_ 2463978866 ARA_Status_01_alt "Veraltet-Bit für ARA_Status_01";
CM_ SG_ 2463978866 KLR_01_alt "Veraltet-Bit für KLR_01";
CM_ SG_ 2463978866 KLR_Touchauswertung "Touchauswertung der KLR-Elektronik";
CM_ SG_ 2463978866 LDW_Lernmodus_seitenabhaengig "Signal dient zur Ansteuerung von Funktionsanzeigen im Mitteldisplay des Kombiinstruments für die Seitenabhänige Liniendetektion (neue Funktion ab D4)";
CM_ SG_ 2463978866 LDW_Status_Anzeige "Signal dient zur Ansteuerung von Funktionsanzeigen im Mitteldisplay des Kombiinstruments.";
CM_ SG_ 2463978866 LDW_Status_LED_gruen " ";
CM_ SG_ 2463978866 LDW_Texte "Bei Anzeige eines Fehlertextes im Kombi ertönt ein akustisches Signal";
CM_ SG_ 2463978866 PLA_04_alt "Veraltet-Bit für PLA_04";
CM_ SG_ 2463978866 PLA_06_alt "Veraltet-Bit für PLA_06";
CM_ SG_ 2463978866 PLAIPA_PaCo_FunctionState "Signalisierung des Funktionszustandes von PLA/IPA

0 ResumePossible: Wiederaufnahme des aktiven Parkvorgangs ist seitens PLA/IPA möglich
1 Park_In_SearchMode: PLA/IPA befindet sich in der Lückensuchfahrt
2 Park_In_SlotFound: PLA/IPA hat mindestens ein";
CM_ SG_ 2463978866 PLAIPA_PaCo_MainState "Hauptzustand der Kundenfunktion PLA/IPA.

0 Init: PLAIPA befindet sich in der Initialisierung
1 InOperation_NoError: PLAIPA befindet sich im Betrieb ohne Fehler
7 Fehler: PLAIPA befindet sich im Fehlerzustand";
CM_ SG_ 2463978866 RA_Status "Signalwerte:
0: Nicht_freigeschaltet - Reversing Assist signalisiert, dass die Funktion nicht freigeschaltet ist.
1: Init - Dient der initialisierung der Funktion.
2: Nicht_verfuegbar - Reversing Assist signalisiert, dass die Funktion nicht verfügbar i";
CM_ SG_ 2463978866 RDK_02_alt "Veraltet-Bit für RDK_02";
CM_ SG_ 2463978866 RDK_11_alt "Veraltet-Bit für RDK_11";
CM_ SG_ 2463978866 RDK_FMVSS138_Lampe "Ansteuerung der RDK-Lampe im Kombi bei Druckwarnung";
CM_ SG_ 2463978866 RDK_FMVSS138_MIL "Ansteuerung der RDK-Lampe im Kombi bei Systemstörung.
RDK-Lampe muss für 65 Sekunden blinken und anschliessend dauerhaft leuchten bis RDK dieses Bit wieder auf '0' setzt (Wiedergutprüfung).
Hinweis:  Im AU48x blinken für 60 Sekunden";
CM_ SG_ 2463978866 TA_01_alt "Veraltet-Bit für TA_01";
CM_ SG_ 2463978866 TA_aktiv_HMI "Signalwert an Anzeigegerät welche Funktion aktiv";
CM_ SG_ 2463978866 TA_Fehler "Fehler im Modus Travel Assist";
CM_ SG_ 2463978866 TA_Handsoff_LED "Anfordern der Anzeige des LAHO-Icon in weiß und rot unabhängig von der Textmeldung";
CM_ SG_ 2463978866 TA_Spurwechsel "Anzeige für die Durchführung eines Spurwechsels im Kombi";
CM_ SG_ 2463978866 TA_Status "Anzeige TravelAssist-Statusleuchte im Kombi";
CM_ SG_ 2463978866 TA_Texte "Anzeige TravelAssist-Texte im Kombi";
CM_ SG_ 2463978866 TA_Texte_02 "Anzeige TravelAssist-Texte im Kombi";
CM_ SG_ 2463978866 TPA_02_alt "Veraltet-Bit für TPA_02";
CM_ SG_ 2463978866 TPA_Status "signalisiert den Funktionsstatus von TPA";
CM_ SG_ 2463978866 TPMS_WarnLmpStMil "Control of the TPMS lamp in the instrument cluster for system fault";
CM_ SG_ 2463978866 TPMS_WarnLmpStP "Control of the TPMS warning lamp  in the instrument cluster for pressure warning";
CM_ SG_ 2463978866 VZE_Status_EDR "Das Signal zeigt den Status der VZE für den EventDataRecorder an.";
CM_ SG_ 2463978866 WBA_05_alt "Veraltet-Bit für WBA_05";
CM_ SG_ 2463978866 WBA_Status_AWU "Status Teilfunktion Ausweichunterstützung";

CM_ SG_ 173 GE_Fahrstufe "Fahrprogramm des Getriebes

Hinweis: Zwischenstellung '0x0' darf nur für Zustandswechsel P/R, R/N, N/D ausgegeben werden, nicht für D/S oder D/Tippgasse wegen Abschaltkriterium GRA/ACC";
CM_ SG_ 173 GE_Ursache_Fahrstufe_N "Zeigt an, warum Fahrstufe N angenommen wurde. So kann z.B. die Rollsicherung im Verlassenskonzept aktiv bleiben, wenn das Schalten nach N ohne Fahrerwunsch erfolgte (z.B. Fehlerreaktion).

ACHTUNG: Das Signal darf nur ausgewertet werden, wenn GE_Fahrstu";
CM_ SG_ 173 Getriebe_11_BZ "Botschaftszähler";
CM_ SG_ 173 Getriebe_11_CRC "Für MLB:
'Berechnung siehe Lastenheft 'Kommunikationsabsicherung für FlexRay und CAN''

Ab MQB und MLBevo:
'Berechnung siehe Lastenheft 'End-to-End Kommunikationsabsicherung''

Endwerte siehe Begleitdokument 'S-PDU Kennungsfolgen'";

CM_ SG_ 270 GE2_Fahrstufe "Fahrprogramm des Getriebes (redundantes Signal zu Getriebe_11.GE_Fahrstufe wg. Autosar-Modellierung notwendig)

Hinweis: Zwischenstellung '0x0' darf nur für Zustandswechsel P/R, R/N, N/D ausgegeben werden, nicht für D/S oder D/Tippgasse wegen Abschaltkr";
CM_ SG_ 270 GE2_Ursache_Fahrstufe_N "Zeigt an, warum Fahrstufe N angenommen wurde. So kann z.B. die Rollsicherung im Verlassenskonzept aktiv bleiben, wenn das Schalten nach N ohne Fahrerwunsch erfolgte (z.B. Fehlerreaktion).

ACHTUNG: Das Signal darf nur ausgewertet werden, wenn GE_Fahrstu";
CM_ SG_ 270 GE_Abtriebsdrehzahl "Mittlere abtriebsseitige Getriebedrehzahl";
CM_ SG_ 270 GE_Anf_Zylabsch "GE_Anforderung_Zylinderabschaltung
Getriebe-Koordination Zylinderumschaltung TMB / VMB (Teilmotorbetrieb / Vollmotorbetrieb)";
CM_ SG_ 270 GE_Anheb_Solldrehz_Leerlauf "Anforderung einer absoluten Leerlaufdrehzahl";
CM_ SG_ 270 GE_Aufnahmemoment "Zeigt das Drehmoment, mit dem das Getriebe den Motor an der Kurbelwelle belastet = Ölpumpenmoment + Kupplung-/Wandler-Moment.

Signal soll grundsätzlich im kompletten Fahrbetrieb bedient werden; in bestimmten Situationen kann vom GSG der Wert 1022 = 'We";
CM_ SG_ 270 GE_Drehzahlmesser_Daempfung "Beim DQ-Getriebe kann die Anzeigedämpfung des Drehzahlmessers beim Schalten geändert werden.";
CM_ SG_ 270 GE_Eingangsdrehz "Wird gesendet, um das Lastschlagverhalten bei Schaltvorgängen zu verbessern.";
CM_ SG_ 270 GE_Eingangswellengradient "Gradient der Eingangswellendrehzahl, wird in der Schaltung mit Fortschritt der Drehzahlüberführung auf den Drehzahlgradienten der kommenden Eingangswelle überführt.";
CM_ SG_ 270 GE_Entkopplung_Status "Rückmeldung zu MO_Entkopplung_Sollschlupf (das MSG kann damit anfordern, den Schlupf in der Fahr-/Wandlerkupplung zu erhöhen bzw. die Reglerparameter umzuschalten, um eine stärkere Entkopplung zu erreichen, damit Rucke aus dem Antrieb nicht im Fahrzeug sp";
CM_ SG_ 270 GE_Fahrstufenwunsch "Hiermit wird ein Fahrstufenwunsch, hervorgerufen durch eine Wählhebelbetätigung des Fahrers bei gleichzeitig getretenem Bremspedal, signalisiert.";
CM_ SG_ 270 GE_Freig_Langfr_Schutzmom "Freigabeflag für das langfristige Schutzmoment für
MLB: GE_Langfr_Schutzmom
MQB: GE_Langfr_Schutzmom_02
MLBevo: GE_Langfr_Schutzmom_02 und GE_Langfr_Schutzmom_Schub
";
CM_ SG_ 270 GE_Freig_MMom_Vorhalt "Freigabe für die Anforderung einer Momentenreserve durch das Getriebe über das Signal
MLB: GE_MMom_Vorhalt
MQB/MLBevo: GE_MMom_Vorhalt_02";
CM_ SG_ 270 GE_Freigabe_Synchro "Freigabe der Signale
'GE_Synchro_Wunschdrehz' und 'GE_Synchro_Zeit'";
CM_ SG_ 270 GE_Grenzkriechmoment "Das Grenzkriechmoment ist das max. Motormoment was von der Kupplung im Fahrzeugstillstand aufgenommen werden kann um z.B. das Fgz. am Berg zu halten oder das Ankriechen zu gewährleisten.

Achtung:
Einheitenloser CAN-Wert.
Faktor in MO_Faktor_Momente i";
CM_ SG_ 270 GE_HYB_DZ_Eingriff "Freigabebedingung für Drehzahleingriff-Hybrid";
CM_ SG_ 270 GE_HYB_EM_KompMom "K0 Kompensationsmoment, vom MSG immer einzukoordinieren ohne Filterung, VZ immer positiv";
CM_ SG_ 270 GE_HYB_Fehlerstatus "Hybrid-spezifische Fehlerstati
PQ3x: Fehlerstatus x1b signalisiert, dass der Druck zum Öffnen der K0 nicht ausreicht (nach Kl15 ein)
PL71: Fehlerstatus x1b signalisiert eine unzureichende Druckversorgung durch die EOP.
Fehlerstatus 1xb : Verhinderung u";
CM_ SG_ 270 GE_HYB_Filt_MomAufbau "Faktor, der im MSG zur Berechnung der Filterkonstanten für den Fahrerwunschmomentenaufbau im Impulsstart verwendet wird.";
CM_ SG_ 270 GE_HYB_Freig_VM_EM_Stop "Signalisiert Bereitschaft GSG, dass VM gestoppt werden darf (Soft Stop) oder dass EM gestoppt werden darf (Übergang EM-Fahren => EMFahrbereitschaft)";
CM_ SG_ 270 GE_HYB_Freigabe_K0 "PQ3x: Bit ist Zwangsanforderung für Status der K0
0 = K0 auf
1 = K0 zu
PL72: Übergang von 0 nach 1 (bzw von 1 nach 0) ist Teil des Wiederstart- (Stop-) Handshakes
0 = Freigabe K0 öffnen
1 = Freigabe K0 schließen";
CM_ SG_ 270 GE_HYB_Freigabe_LL_Reg "GSG gibt hier die Aktivierung einer DZ-Regelung von VM und/oder EM frei. (Verhinderung Selbstbeschleuniger)";
CM_ SG_ 270 GE_HYB_IstStatus_K0 "Status 'offen' muss eine voll geöffnete Kupplung sicherstellen. Der Zustand 'Übergang' zeigt eine unter Kupplungsmoment stehende schlupfende K0 an.";
CM_ SG_ 270 GE_HYB_MaxMomK0 "Reduktionsstufen abh. vom Projekt zur Reduktion des VM-Momentes als K0 Schutz.";
CM_ SG_ 270 GE_HYB_nK0 "Nur PQ3x Hybrid:
GSG teilt MSG mit, auf welcher DZ die EM nach schnellem Schließen der K0 und nach DZAngleichung durch das GSG landen wird.
Wenn Signal 'Wiederstart' nicht aktiv: EM-Drehzahl wird gespiegelt.
Wenn Signal 'Wiederstart' aktiv: DZ, auf der";
CM_ SG_ 270 GE_HYB_Sportfaktor "Sportlichkeitsfaktor Getriebe, zur Verwendung in der Hybrid-Fahrstrategie
0 = nicht sportlich
1..15 = sportlich";
CM_ SG_ 270 GE_HYB_StartAnf "Auslösen des VM_Wiederstart bei EM-Betrieb";
CM_ SG_ 270 GE_HYB_VM_akt_halten "Im elektrischen Fahren/Tipp: Übergang von 0 auf 1 zeigt VM-Startanforderung des GSG an.
Empfehlung GSG an MSG, dass VM aktiv gehalten werden soll. Verwendbar z.B. bei den Funktionen 'fast off (Gang halten)' oder bei 'Rückschaltung bei Bremsen'.";
CM_ SG_ 270 GE_HYB_VM_Soll_Moment "Verbrenner-Sollmoment, auf VM-Kurbelwelle bezogen, ohne Status-Bit (Rohwert 254 = kein_Eingriff), nur gültig wenn GE_HYB_Wiederstart == 1 && GE_HYB_IstStatus_K0 == 2";
CM_ SG_ 270 GE_HYB_VM_Startkontr "Freigabe der Wiederstartkontrolle";
CM_ SG_ 270 GE_HYB_Wiederstart "Getriebe zeigt an, ob Wiederstart aktiv ist.";
CM_ SG_ 270 GE_HYB_Wiederstartreserve "Reserve an EM_Moment im MSG bereitzustellen, die für eine EM_KompMom Anforderung immer gewährleistet sein muss.";
CM_ SG_ 270 GE_Langfr_Schutzmom_02 "Konventionelle Projekte: Begrenzung des Motormoments in positiver Richtung
Hybrid-Projekte: Begrenzung des Summenmoments der Antriebsmaschinen; in MQB Begrenzung betragsmäßig sowohl in positiver als auch in negativer Richtung; in MLBevo Begrenzung nur in";
CM_ SG_ 270 GE_MMom_Soll_02 "Momenteneingriff an den Motor.
Fordert vom MSG eine kurzfristige Reduzierung oder Anhebung des Moments.
Das Signal ist nur gültig in Kombination mit GE_MMom_Status (bei MQB) bzw. GE_MMom_Status_02 (bei MLBevo).

Achtung:
Einheitenloser Wert! Faktor i";
CM_ SG_ 270 GE_MMom_Status "Qualifiziert 
MLB: GE_MMom_Soll
MQB: GE_MMom_Soll_02";
CM_ SG_ 270 GE_MMom_Status_02 "Das Signal qualifiziert GE_MMom_Soll_02 und gibt an, wie der Wert aus GE_MMom_soll – vorbehaltlich der Umsetzbarkeit aufgrund motorinterner Restriktionen – umgesetzt werden soll.
Werte:
0= kein Eingriff
1=   absoluter reduzierender Eingriff auf Gesamt ";
CM_ SG_ 270 GE_MMom_Vorhalt_02 "Anforderung einer Momentenreserve durch das Getriebe, gilt nur mit Freigabe durch 
GE_Freig_MMom_Vorhalt

Anforderung wird als Absolut-Wert umgesetzt, nicht als Relativ-Wert/Delta zum aktuellen Ist-Moment (d. h. eine Momentenreserve wird eingestellt, w";
CM_ SG_ 270 GE_Mom_Begr_Gradient "255 =  keine Begrenzung (Initwert)

Mit diesem Signal fordert das GSG vom MSG  im positiven Momentenbereich (Getriebeeingangs- / Motorausgangsmoment > 0 Nm) Momenten-Erhöhungen aufgrund Fahrerwunsch-Änderungen im Gradient zu begrenzen.
(Änderungen aufg";
CM_ SG_ 270 GE_Notlauf "AL/DL: Signalisiert wenn sich das Getriebe (bei DL ein Teilgetriebe) im Notlauf befindet.
VL: Wird gesetzt wenn kein Kraftschluss möglich ist.";
CM_ SG_ 270 GE_Radmoment "Radmoment vom Getriebe";
CM_ SG_ 270 GE_Schaltablauf "Das Signal zeigt den aktuellen Status eines Schaltvorgangs.

Bei Signal = 0 liegt kein Schaltvorgang vor.
Bei Signal =2 liegt die Befüllphase der zuschaltenden Kupplung bzw. 
                      die Vorbereitungsphase dazu vor.

Mit den unterschie";
CM_ SG_ 270 GE_Schubabschalt_Unt "Signalisiert wenn aus der Sicht des Getriebes eine Schubabschaltung des Motors möglich ist. Bei aktiver Schubabschalt-Unterstützung wird sicher gestellt, dass die Kupplung nicht schlagartig geöffnet wird";
CM_ SG_ 270 GE_StartStopp_Info "Stopp-Freigabe und Start-Anforderung an den Start-Stopp-Koordinator";
CM_ SG_ 270 GE_Status_Kraftschluss "Zeigt den Ist-Status des Kraftschlusses im Getriebe.
(Anmerkung: meist wird damit der Zustand des Anfahrelements beschrieben, d.h. bei DL/DQ die Kupplung;  bei AQ/AL der Wandler incl. Überbrückungskupplung)
0 = offen, kein Kraftschluss
1 = offen mit Kr";
CM_ SG_ 270 GE_Synchro_Status_02 "Das Signal qualifiziert GE_Synchro_Wunschdrehz_02 und gibt an, wie GE_Synchro_Wunschdrehz_02 umgesetzt werden soll.

Werte:
0 - Kein Eingriff
1...4 - Drehzahleingriff wirkt auf Gesamtantrieb (MSG: Verwendung Param.Satz 1...4)
5 - Drehzahleingriff wir";
CM_ SG_ 270 GE_Synchro_Wunschdrehz "Wunschdrehzahl für Verbrennungsmotor bzw. E-Motor; Freigabe durch GE_Freigabe_Synchro (bei MLB und MQB), Freigabe und Steuerung durch GE_Synchro_Status (bei MLBevo).
Wenn kein Eingriff angefordert wird, soll Init = 0 = 0x0 gesendet werden.";
CM_ SG_ 270 GE_Synchro_Zeit "Signalisiert wie schnell die Wunschdrehzahl bei einem Synchronisations-Wunschdrehzahl-Eingriff aufgebaut werden soll. Die Zeitvorgabe 0x0 bedeutet so schnell wie möglich. Die geforderte Synchronisationszeit bleibt bis zum Abbruch oder erreichen der Zeit k";
CM_ SG_ 270 GE_Uefkt "Übertragungsfunktion des Getriebes
Drehzahlverhältnis = Eingangsdrehzahl / Ausgangsdrehzahl

AL: Wandlerverstärkung x Drehzahlverhältnis
VL: Drehzahlverhältnis
DL: Drehzahlverhältnis der aktiven und kraftschluß führenden Welle zum Abtrieb, bei Schalt";
CM_ SG_ 270 GE_Uefkt_unplausibel "Das Signal darf nur im Reku-Manager in Hybrid-Varianten verwendet werden.
Zeigt an, ob die Plausibilisierung Momenten-Verhältnis zu Drehzahl-Verhältnis i.O. ist.
Ein gesetztes Signal meldet eine unplausible GE_Uefkt bzw. GE_Uefkt_02.";
CM_ SG_ 270 GE_Verbot_Ausblendung "Verbot Einspritzausblendung für komfortable Schaltungen";
CM_ SG_ 270 GE_Verlustmoment "Achtung einheitenloser Wert !!
	Faktor in MO_Faktor_Momente (MLB) bzw. MO_Faktor_Momente_02 (MQB/MLBevo) in Motor_Code_01 beachten!

ab MQB/MLBevo:
	Das Signal enthält die berechneten Momentenverluste, welche innerhalb des Getriebegehäuses entstehen (";
CM_ SG_ 270 GE_Zielgang "VL-Getriebe:
Signalisiert den Zielgang im manuellen Modus während eines Schaltvorgangs bzw. die momentane simulierte Gangstufe wenn kein Schaltvorgang aktiv ist. In den Fahrprogrammen 'D' und 'S' ist die Übersetzung variabel und somit wird dauerhaft 'Ist";
CM_ SG_ 270 Getriebe_50_BZ "4bit Botschaftszähler, wird mit jeder Sendebotschaft inkrementiert";
CM_ SG_ 270 Getriebe_50_CRC "Für MLB:
Berechnung siehe Lastenheft 'Kommunikationsabsicherung für FlexRay und CAN'
Ab MQB und MLBevo:
Berechnung siehe Lastenheft 'End-to-End Kommunikationsabsicherung'

Endwerte siehe Begleitdokument 'S-PDU Kennungsfolgen'";

CM_ SG_ 509 Freilauf_Charisma_FahrPr "MLBevo: Aktuelles Fahrprogramm des Charisma-Teilnehmers (siehe Systemlastenheft Drive Select)
MQB: Istwert der Kennlinie (siehe Systemlastenheft MQB FPA)";
CM_ SG_ 509 Freilauf_Charisma_Status "Charisma Systemstatus des Charisma-Teilnehmers

Wert 0x3 ist nur für Fahrzeuge ab MQB relevant";
CM_ SG_ 509 FSA_Fehlerstatus_Parksperre "Fahrstufenauswahl: Signalisierung Funktionseinschränkung bzw. Defekt der Parksperre";
CM_ SG_ 509 GE_amax_moeglich "AL/DL: maximal mögliche Beschleunigung unter Berücksichtigung aller möglichen Gänge.

Eine Reduzierung des maximalen Motormoments durch Efficiency wird in dem Signal berücksichtigt.

VL: maximal mögliche Beschleunigung bei Nenndrehzahl (Efficency wird";
CM_ SG_ 509 GE_Anforderung_HMS "Anforderung an dem Haltemanager vom Automatikgetriebe";
CM_ SG_ 509 GE_Anschleppstart_Freigabe "Bilden einer Schleppstartfreigabe aus Fahrdynamiksicht. Schleppstartabbruch bei kritischer Fahrzeugstabilität";
CM_ SG_ 509 GE_Betaetigung_Hold "Anforderung des Getriebes zum Aktivieren der Holdfunktion 
";
CM_ SG_ 509 GE_Charisma_FahrPr "MLBevo: Aktuelles Fahrprogramm des Charisma-Teilnehmers (siehe Systemlastenheft Drive Select)
MQB: Istwert der Kennlinie (siehe Systemlastenheft MQB FPA)";
CM_ SG_ 509 GE_Charisma_Status "Charisma Systemstatus des Charisma-Teilnehmers

Wert 0x3 ist nur für Fahrzeuge ab MQB relevant";
CM_ SG_ 509 GE_Codierung_MSG "Statusausgabe der Diagnose für Falschverbau. Plausibilisierung der empfangenen Motor- und Getriebevariante mit der erwarteten Motor- und Getriebevarianten.";
CM_ SG_ 509 GE_Fahrprogramm "Signalisiert das Fahrprogramm  im Bezug auf
die Fahrstufe des Getriebes.

Audi/MQB:
Offroad

Bentley:
Snow
Gravel
Mud_Ruts
Sand_Dune

Touareg:
Offroad
Snow";
CM_ SG_ 509 GE_Freigabe_Info_WFS "WFS-Freigabeinformation";
CM_ SG_ 509 GE_Freigabe_Verfallsinfo_WFS "WFS";
CM_ SG_ 509 GE_Freilauf_Status "Freilauf-Status-Signal vom Frailauf-Master an aktive Freilauf-Teilnehmer. In diesem Signal zeigt der Freilauf-Master an, welchen aktuellen Status die Freilauf-Betriebsstrategie hat.";
CM_ SG_ 509 GE_Grundeinstell_Drehrichtung_EM "Anforderung des Getriebes, die E-Maschine während der Grundeinstellung rückwärts zu drehen.

ACHTUNG! Das Signal ist nur auszuwerten, wenn GE_Grundeinstellung == 1. Das Signal wird vom Getriebe nur in Fahrstufe P gesetzt.";
CM_ SG_ 509 GE_Grundeinstellung "Grundeinstellung des Getriebes ist aktiv

Hinweis:
Verwendung nur im MQB";
CM_ SG_ 509 GE_LaunchControl "Während einer LaunchControl-Anfahrt sendet das Getriebesteuergerät das Bit LaunchControl aktiv.
Die Bremse wertet dieses Bit aus, um während einer solchen Anfahrt die Regelgrenzen der Schlupfregelung zu erweitern.
Im Motor Nutzung zur Verbesserung des A";
CM_ SG_ 509 GE_LFR_Adaption "Qualifiziert das ausgegeben Motorbelastungsmoment (durch GE_Vorsteuermoment) für die Verwendung zur LFR (Leerlauffüllungsregelung) im Moto";
CM_ SG_ 509 GE_OBD_AbsperrVent "Das Getriebesteuergerät führt eine elektrische Diagnose des von ihm angesteuerten Absperrventils für den Öl-Wasser-Wärmetauscher durch und übermittelt das Ergebnis an das MSG (Standard-4Bit-OBD-Status, nicht alle Zustände müssen genutzt werden; so sind z.";
CM_ SG_ 509 GE_OBD_Status "Dieses Bit steuert die MIL-Lampe an (Motorsteuergerät reicht diese Info an Kombi weiter).";
CM_ SG_ 509 GE_Parken_beibehalten_HMS "Anforderung seitens Parksperrenmaster (GSG/ASG), das Lösen der Parkbremse zu verhindern.";
CM_ SG_ 509 GE_Parken_WFS_Status "Rückmeldung des Status der angeforderten erneuten Authentifikation durch ZFAS";
CM_ SG_ 509 GE_QBit_Sumpftemperatur "Qualifizierungs-Bit für GE_Sumpftemperatur, gesetzt bei Ersatzwert, Init oder Fehler.";
CM_ SG_ 509 GE_Schleuderoeltemperatur "Die Temperatur des Schleuderöls durch die K0 wird vom Getriebe modelliert. 
Das Schleuderöl aus der K0 trifft beim DQ400e von innen auf den Rotor der E-Maschine und sorgt für eine Erwärmung/Kühlung des Rotors.";
CM_ SG_ 509 GE_SpannungsAnf "Forderung des GSGs zur Spannungsanhebung.";
CM_ SG_ 509 GE_Sperr_Info_WFS "WFS-Sperrinformation";
CM_ SG_ 509 GE_Strombedarf_erh "Das GSG teilt dem MSG einen aufgrund der Kühlung erhöhten Strombedarf mit, damit gleichzeitig die Kühler-Lüfter-Ansteuerung kurzzeitig reduziert wird.

Signal wird bisher nur im MQB-PHEV verwendet.";
CM_ SG_ 509 GE_Sumpftemperatur "Getriebesumpftemperatur wird über den Temperatursensor auf der Getriebeplatine ermittelt. Die absolute Sumpftemperatur wird vom Motor empfangen, um entsprechende Kühlleistung für das Getriebe einzustellen.";
CM_ SG_ 509 GE_TippZustand "Zeigt den Tippzustand in eine Fahrstufe und ein Fahrprogramm via Paddles oder Schaltbetätigung an.
Das Signal ist gültig in Kombination mit GE_Fahrstufe und GE_Fahrprogramm.

MLBevo:
DL und AL: nur Tipp_in_permanent
PDK2: Tipp_in_temporaer und Tipp_i";
CM_ SG_ 509 GE_Veto_Rollfaehigkeit "Der Schaltbetätigungsmaster kann mit diesem Signal die Rollfähigkeit bei Zündung aus ('N-Haltephase'/'Waschstraßenfunktion') situationsabhängig verhindern, z.B. bei einem Defekt der P-Taste.";
CM_ SG_ 509 GE_Weckleitung_aktiv "Rückmeldung an Motor, dass Weckleitung aktiv";
CM_ SG_ 509 GE_Zustand_Kuppltemp "Dieses Signal gibt den Temperaturzustand der Kupplung im DQ-Getriebe (z. Zt. DQ2x0, DQ500) an das ACC-System.";
CM_ SG_ 509 Getriebe_51_BZ "4bit Botschaftszähler, wird mit jeder Sendebotschaft inkrementiert";
CM_ SG_ 509 Getriebe_51_CRC "Für MLB:
Berechnung siehe Lastenheft 'Kommunikationsabsicherung für FlexRay und CAN'
Ab MQB und MLBevo:
Berechnung siehe Lastenheft 'End-to-End Kommunikationsabsicherung'

Endwerte siehe Begleitdokument 'S-PDU Kennungsfolgen'";

CM_ SG_ 891 GNSS_Empfaenger_Status "Im 'Backup Mode' wird z.B. die UTC Zeit durch eine gepufferte 'Realtime Clock' bereitgestellt.
Im 'Live Mode' wird die UTC Zeit durch das GNSS Modul bereitgestellt. ";
CM_ SG_ 891 GNSS_Empfangbare_Satelliten "Anzahl der Satelliten, welche bei der aktuellen Satellitenkonfiguration ptentiell verfügbar sind";
CM_ SG_ 891 GNSS_Genutzte_Satelliten "Anzahl der Satelliten, welche für die aktuelle Ortung verwendet werden";
CM_ SG_ 891 GNSS_GLONASS_in_Nutzung "1: das genannte GNSS wurde für die Ortung verwendet";
CM_ SG_ 891 GNSS_GPS_in_Nutzung "1: das genannte GNSS wurde für die Ortung verwendet";
CM_ SG_ 891 GNSS_Nachrichtenpaket_ID5 "+1 für jedes neue Paket. Zyklische ID-Vergabe (Zähler). Zur Identifizierung zusammenhängender Nachrichten, die die Daten derselben GNSS-Ortung enthalten und somit zum selben Zyklus gehören. D.h. Daten in den Nachrichten wurden zur selben Zeit erzeugt. Der";
CM_ SG_ 891 GNSS_Sichtbare_Satelliten "Anzahl der Satelliten, welche aktuell empfangen werden";
CM_ SG_ 891 GNSS_UTC_Zeit "UTC-Zeit, Sekunden seit dem 01.01.1970 00:00";

CM_ SG_ 771 HCA_03_Sendestatus "Umschalten zwischen langsamem und schnellem Zyklus der HCA_03-Botschaft";
CM_ SG_ 771 HCA_QFK_AnfStat "Statusinformationen des Anforderers";
CM_ SG_ 771 HCA_QFK_Art1 "Auswahlsignal für HCA_QFK_Signal1";
CM_ SG_ 771 HCA_QFK_Art2 "Auswahlsignal für HCA_QFK_Signal2";
CM_ SG_ 771 HCA_QFK_KrSoll "Krümmungsanforderung";
CM_ SG_ 771 HCA_QFK_KrSoll_VZ "Vorzeichen für die Krümmungsanforderung";
CM_ SG_ 771 HCA_QFK_KruemmSoll "Krümmungsanforderung";
CM_ SG_ 771 HCA_QFK_KruemmSoll_VZ "Vorzeichen für die Krümmungsanforderung";
CM_ SG_ 771 HCA_QFK_Signal1 "Inhalt HCA_QFK_Signal1 wird durch das Signal HCA_QFK_Art1 gesteuert.
Nähere Informationen im LAH Querführungskoordinator.";
CM_ SG_ 771 HCA_QFK_Signal2 "Inhalt HCA_QFK_Signal2 wird durch das Signal HCA_QFK_Art2 gesteuert.
Nähere Informationen im LAH Querführungskoordinator.";
CM_ SG_ 771 HCA_QFK_Spuerb "Spürbarkeitsanforderung. Legt fest, mit welchem Handmoment die angeforderte Krümmung überlenkt werden muss.";
CM_ SG_ 771 SOK_HCA_03_Signatur "Signatur im Rahmen der durch SOK geschützen Broadcast-Kommunikation

Geschützte Funktion: LaneAssist/TravelAssist
Geschützte Botschaft: HCA_03";

CM_ SG_ 626 HVLM_Aktive_Ladeart "informs about the used charging infrastructure - AC - DC - AWC.";
CM_ SG_ 626 HVLM_Anforderung_HMS "Anforderung zur Verriegelung des Triebstrangs";
CM_ SG_ 626 HVLM_AWC_VerbautStatus "Verbausignalisierung vom HVLM der optionalen Komponente AWC";
CM_ SG_ 626 HVLM_DC_Aufstartmodus "Aufstartmodus zum Aktivieren des HV-Modus für DC-Laden";
CM_ SG_ 626 HVLM_Intensitaet_Lk1 "Über dieses Signal wird eine Information über die Beleuchtungsintensität an der LED der Ladeklappe 1 gesendet.";
CM_ SG_ 626 HVLM_Intensitaet_Lk2 "Über dieses Signal wird eine Information über die Beleuchtungsintensität an der LED der Ladeklappe 2 gesendet.";
CM_ SG_ 626 HVLM_Laden_ISO_Messung_Anf "Messung des Isolationswiderstandes des Ladesystems (Fzg und Ladesäule) während des Ladevorganges durch das Fahrzeug
0= Anforderung
1= keine_Anforderung";
CM_ SG_ 626 HVLM_Ladeszenario "Über dieses Signal wird das einzustellende Szenario für die Visualisierung gesendet.";
CM_ SG_ 626 HVLM_Ladevorgang_Anf "Art der angeforderten Ladeart 
0 = Laden_nicht_angefordert
1 = AC_Laden_Angefordert
2 = DC_Laden_Angefordert
3 = AC_und_DC_Angefordert
4 = Induktiv_Laden_Angef
5 = AC_und_Induktiv_Angef
6 = DC_und_Induktiv_Angef
7 = AC_DC_und_Induktiv_Angef";
CM_ SG_ 626 HVLM_Parken_beibehalten_HMS "Anforderung den Triebstrang verriegelt zu halten";
CM_ SG_ 626 HVLM_Pulsierstufe "Über dieses Signal wird eine Information über die Frequenz der Ladedosen LED bei verschiedenen Leuchtmustern gesendet.";
CM_ SG_ 626 HVLM_Start_Pulserkennung "Startanforderung für die Pulserkennung";
CM_ SG_ 626 HVLM_Steckerstatus_A "Gibt den Steckerstatus aus der Ladedose A an";
CM_ SG_ 626 HVLM_Steckerstatus_B "Gibt den Steckerstatus aus der Ladedose B an";
CM_ SG_ 626 HVLM_WakeUpZaehlerResetAnf "Dieses Signal kann den Wakeup-Verhinderungszähler zurücksetzen";
CM_ SG_ 626 HVLM_ZustandLadeablauf "Zustand im Ablauf des Ladevorganges
0 = Init
1 = Standby_Ladevorbedingungen erfuellt
2 = Standby_Ladevorbedingungen_nicht_erfuellt
3 = Fehler
4 = Laden_starten
5 = Laden_beenden
6 = HVBatterie_Laden
7 = HVBatterie_Entladen
8 = Erhaltungsladen";

CM_ SG_ 2589283966 IMU_StObd_StChk1 "'Test Not Completed This Operation Cycle'-Information IMU OBD error path 1";
CM_ SG_ 2589283966 IMU_StObd_StChk10 "'Test Not Completed This Operation Cycle'-Information IMU OBD error path 10";
CM_ SG_ 2589283966 IMU_StObd_StChk11 "'Test Not Completed This Operation Cycle'-Information IMU OBD error path 11";
CM_ SG_ 2589283966 IMU_StObd_StChk2 "'Test Not Completed This Operation Cycle'-Information IMU OBD error path 2";
CM_ SG_ 2589283966 IMU_StObd_StChk3 "'Test Not Completed This Operation Cycle'-Information IMU OBD error path 3";
CM_ SG_ 2589283966 IMU_StObd_StChk4 "'Test Not Completed This Operation Cycle'-Information IMU OBD error path 4";
CM_ SG_ 2589283966 IMU_StObd_StChk5 "'Test Not Completed This Operation Cycle'-Information IMU OBD error path 5";
CM_ SG_ 2589283966 IMU_StObd_StChk6 "'Test Not Completed This Operation Cycle'-Information IMU OBD error path 6";
CM_ SG_ 2589283966 IMU_StObd_StChk7 "'Test Not Completed This Operation Cycle'-Information IMU OBD error path 7";
CM_ SG_ 2589283966 IMU_StObd_StChk8 "'Test Not Completed This Operation Cycle'-Information IMU OBD error path 8";
CM_ SG_ 2589283966 IMU_StObd_StChk9 "'Test Not Completed This Operation Cycle'-Information IMU OBD error path 9";
CM_ SG_ 2589283966 IMU_StObd_StFail1 "'Test Failed'-Information  IMU OBD error path 1";
CM_ SG_ 2589283966 IMU_StObd_StFail10 "'Test Failed'-Information  IMU OBD error path 10";
CM_ SG_ 2589283966 IMU_StObd_StFail11 "'Test Failed'-Information  IMU OBD error path 11";
CM_ SG_ 2589283966 IMU_StObd_StFail2 "'Test Failed'-Information  IMU OBD error path 2";
CM_ SG_ 2589283966 IMU_StObd_StFail3 "'Test Failed'-Information  IMU OBD error path 3";
CM_ SG_ 2589283966 IMU_StObd_StFail4 "'Test Failed'-Information  IMU OBD error path 4";
CM_ SG_ 2589283966 IMU_StObd_StFail5 "'Test Failed'-Information  IMU OBD error path 5";
CM_ SG_ 2589283966 IMU_StObd_StFail6 "'Test Failed'-Information  IMU OBD error path 6";
CM_ SG_ 2589283966 IMU_StObd_StFail7 "'Test Failed'-Information  IMU OBD error path 7";
CM_ SG_ 2589283966 IMU_StObd_StFail8 "'Test Failed'-Information  IMU OBD error path 8";
CM_ SG_ 2589283966 IMU_StObd_StFail9 "'Test Failed'-Information  IMU OBD error path 9";

CM_ SG_ 182 IMU_05_BZ "4bit Botschaftszähler, wird mit jeder Sendebotschaft inkrementiert";
CM_ SG_ 182 IMU_05_CRC "Für MLB:
Berechnung siehe Lastenheft 'Kommunikationsabsicherung für FlexRay und CAN'
Ab MQB und MLBevo:
Berechnung siehe Lastenheft 'End-to-End Kommunikationsabsicherung'

Endwerte siehe Begleitdokument 'S-PDU Kennungsfolgen'";
CM_ SG_ 182 IMU_ALat "raw_value_lateral_acceleration_ay";
CM_ SG_ 182 IMU_ALat_Qlfr "confidence_factor_of_lateral_acceleration_ay";
CM_ SG_ 182 IMU_ALgt "raw_value_longitudinal_acceleration_ax";
CM_ SG_ 182 IMU_ALgt_Qlfr "confidence_factor_of_longitudinal_acceleration_ax";
CM_ SG_ 182 IMU_AVert "raw_value_vertical_acceleration_az";
CM_ SG_ 182 IMU_AVert_Qlfr "confidence_factor_of_vertical_acceleration_az";
CM_ SG_ 182 IMU_MeasurementTimeHigh "Messzeitpunkt der IMU, ganzzahlige Sekunden";
CM_ SG_ 182 IMU_MeasurementTimeLow "Messzeitpunkt der IMU, ganzzahlige Millisekunden";
CM_ SG_ 182 IMU_PitchRate "raw_value_pitch_rate_omega_y";
CM_ SG_ 182 IMU_PitchRate_Qlfr "conficence_factor_of_pitch_rate_omega_y";
CM_ SG_ 182 IMU_RollRate "raw_value_roll_rate_omega_x";
CM_ SG_ 182 IMU_RollRate_Qlfr "confidence_factor_of_roll_rate_omega_x";
CM_ SG_ 182 IMU_YawRate "raw_value_yaw_rate_omega_z";
CM_ SG_ 182 IMU_YawRate_Qlfr "confidence_factor_of_yaw_rate_omega_z";
CM_ SG_ 182 SOK_IMU_05_Signatur "Signatur im Rahmen der durch SOK geschützen Broadcast-Kommunikation

Geschützte Funktion: Inertialsensorik
Geschützte Botschaft: IMU_05";

CM_ SG_ 312 IPA_01_BZ "Fehlende Beschreibung (Import)";
CM_ SG_ 312 IPA_01_CRC "Für MLB:
'Berechnung siehe Lastenheft 'Kommunikationsabsicherung für FlexRay und CAN''

Ab MQB und MLBevo:
'Berechnung siehe Lastenheft 'End-to-End Kommunikationsabsicherung''

Endwerte siehe Begleitdokument 'S-PDU Kennungsfolgen'";
CM_ SG_ 312 IPA_Fahrstufenwunsch "Flankengesteuerter Fahrstufenwunsch von IPA/PiloPa an das Getriebe";
CM_ SG_ 312 IPA_Status "Zustand der IPA-Statusmaschine";

CM_ SG_ 2527679583 IPA_02_BZ "4bit Botschaftszähler, wird mit jeder Sendebotschaft inkrementiert";
CM_ SG_ 2527679583 IPA_02_CRC "Für MLB:
Berechnung siehe Lastenheft 'Kommunikationsabsicherung für FlexRay und CAN'
Ab MQB und MLBevo:
Berechnung siehe Lastenheft 'End-to-End Kommunikationsabsicherung'

Endwerte siehe Begleitdokument 'S-PDU Kennungsfolgen'";
CM_ SG_ 2527679583 IPA_Akustik_PL_gefunden "Signalisiert ein akustische Benachrichtigung, dass Parklücken gefunden wurden.";
CM_ SG_ 2527679583 IPA_Anf_Meldungen "Das Signal fordert die Anzeige einer Meldung an. Jedem Signalwert ist eine Meldung zugeordnet. Das Signal ist derzeit für die Funktionen IPA/RPA und TPA implementiert.";
CM_ SG_ 2527679583 IPA_PL_Anzeige_links "Zeigt an, ob auf der linken Seite eine Parklücke erkannt wurde.";
CM_ SG_ 2527679583 IPA_PL_Anzeige_rechts "Zeigt an, ob auf der rechten Seite eine Parklücke erkannt wurde.";
CM_ SG_ 2527679583 Parken_aktives_System_02 "zeigt an welches parkendes System aktiv ist";
CM_ SG_ 2527679583 Parken_Aktivierungslicht_Anf "Anforderung des Aktivierungslichts nach erfolgreicher Aktivierungshandlung seitens Pilotiertem Parken.";
CM_ SG_ 2527679583 Parken_Bestaetigungsblinken_Anf "Anforderung seitens Pilotiertem Parken für ein Erfolgsblinken nach dem Erreichen der Zielposition bzw. für ein Abbruchsblinken bei Eintreten einer Abbruchsbedingung.";
CM_ SG_ 2527679583 Parken_Blinker_li_Anf "Anforderung seitens Parkens für 'Links blinken'";
CM_ SG_ 2527679583 Parken_Blinker_re_Anf "Anforderung seitens Parken für 'Rechts blinken'";
CM_ SG_ 2527679583 Parken_Fahrbereitschaftlicht_Anf "Anforderung des Fahrbereitschaftslichts";
CM_ SG_ 2527679583 Parken_Fahrerhinweise_Anf "Anforderung zur erneuten Lampenaufprüfung und Anzeige von Warnhinweisen nach einem pilotierten Ausparkvorgang.";
CM_ SG_ 2527679583 Parken_Fahrtrichtungslicht_Anf "Anforderung seitens Pilotiertem Parken für die Anzeige der initialen Fahrtrichtung nach Systemaktivierung.";
CM_ SG_ 2527679583 Parken_FFB_LED_Anf "Statusinformation des Pilotierten Parkens für die Ansteuerung der LED auf der Funkfernbedienung.";
CM_ SG_ 2527679583 Parken_Lichtnachlauf_Anf "Anforderung des Lichtnachlaufs beim BCM1 (analog Verlassenskonzept) für das Pilotierte Parken. ";
CM_ SG_ 2527679583 Parken_Lichtsteuerung_Anf "Anforderung zum Setzen des Lichtmodus des Fahrzeuges von der Parkfunktion";
CM_ SG_ 2527679583 Parken_Schluesselsuche_Anf "Ansteuerung der Schlüsselsuche für das pilotierte Parken.";
CM_ SG_ 2527679583 Parken_Seitenspiegel_Anf "Anforderung für Seitenspiegel an- oder abklappen beim PiloPa";
CM_ SG_ 2527679583 Parken_Wegfahrsperren_Anf "Ansteuerung der Wegfahrsperren Komponenten für das pilotierte Parken.  ";
CM_ SG_ 2527679583 Parken_ZR_Sondermodus_Anf "Anforderung Sondermodus, um beim „pilotierten Parken“ spezielle Funktionsanpassungen im Infotainment-Bereich zu ermöglichen (u.a. schnellerer Startup, Abschaltung BT)";
CM_ SG_ 2527679583 Parken_ZV_Schliessen "Anforderung für Zentralverriegelung verriegeln oder safen beim PiloPa";

CM_ SG_ 1811 ISO_ABS_Req_Data "OffBoard Tester Diagnose Request ABS";

CM_ SG_ 1917 ISO_ABS_Resp_Data "Diagnose Response Bremsen-SG/Elektronisches Stabilitätsprogramm";

CM_ SG_ 1813 ISO_Airbag_01_Req_Data "OffBoard Tester Diagnose Request Airbag_01";

CM_ SG_ 1919 ISO_Airbag_01_Resp_Data "OffBoard Tester Diagnose Response Airbag_01";

CM_ SG_ 1807 ISO_Allrad_Req_Data "OffBoard Tester Diagnose Request Allrad";

CM_ SG_ 1913 ISO_Allrad_Resp_Data "OffBoard Tester Diagnose Response Allrad";

CM_ SG_ 1906 ISO_Daempfer_Req_Data "Diagnose Request CAN HS";

CM_ SG_ 2012 ISO_Daempfer_Resp_Data "Diagnose Response CAN HS";

CM_ SG_ 1851 ISO_EBKV_Req_Data "Diagnose Request Elektronischer Bremskraftverstaerker";

CM_ SG_ 1957 ISO_EBKV_Resp_Data "Diagnose Response Elektronischer Bremskraftverstaerker";

CM_ SG_ 1792 ISO_ALL_01_Req_Data "Funktionaler Request ALL";

CM_ SG_ 1810 ISO_Lenkhilfe_Req_Data "OffBoard Tester Diagnose Request Lenkhilfe";

CM_ SG_ 1916 ISO_Lenkhilfe_Resp_Data "OffBoard Tester Diagnose Response Lenkhilfe";

CM_ SG_ 1822 ISO_Quersperre_Req_Data "OffBoard Tester Diagnose Request Quersperre";

CM_ SG_ 1928 ISO_Quersperre_Resp_Data "OffBoard Tester Diagnose Response Quersperre";

CM_ SG_ 2621440019 ISOx_ABS_Req_FD_Data "Diagnose Request CAN FD";

CM_ SG_ 2621571091 ISOx_ABS_Resp_FD_Data "Diagnose Response CAN FD";

CM_ SG_ 2621440021 ISOx_Airbag_01_Req_FD_Data "OffBoard Tester Diagnose Response Airbag_01";

CM_ SG_ 2621571093 ISOx_Airbag_01_Resp_FD_Data "OffBoard Tester Diagnose Response Airbag_01";

CM_ SG_ 2621440015 ISOx_Allrad_Req_FD_Data "Diagnose Request Allrad";

CM_ SG_ 2621571087 ISOx_Allrad_Resp_FD_Data "Diagnose Response Allrad";

CM_ SG_ 2621440114 ISOx_Daempfer_Req_FD_Data "Diagnose Request CAN FD";

CM_ SG_ 2621571186 ISOx_Daempfer_Resp_FD_Data "Diagnose Response CAN FD";

CM_ SG_ 2621440059 ISOx_EBKV_Req_FD_Data "Diagnose Request CAN FD";

CM_ SG_ 2621571131 ISOx_EBKV_Resp_FD_Data "Diagnose Response CAN FD";

CM_ SG_ 2621505536 ISOx_Funkt_Req_All_FD_Data "OffBoard Tester funktionaler Diagnose Request ALL CANFD";

CM_ SG_ 2621440018 ISOx_Lenkhilfe_Req_FD_Data "Diagnose Request CAN FD";

CM_ SG_ 2621571090 ISOx_Lenkhilfe_Resp_FD_Data "Diagnose Response Lenkhilfe";

CM_ SG_ 2621440030 ISOx_Quersperre_Req_FD_Data "Diagnose Request Quersperre";

CM_ SG_ 2621571102 ISOx_Quersperre_Resp_FD_Data "Diagnose Response Quersperre";

CM_ SG_ 2549874892 ISOx_TSplit_L_Req_Data "Diagnose Request";

CM_ SG_ 2621440204 ISOx_TSplit_L_Req_FD_Data "Diagnose Request CAN FD";

CM_ SG_ 2550005964 ISOx_TSplit_L_Resp_Data "Diagnose Response";

CM_ SG_ 2621571276 ISOx_TSplit_L_Resp_FD_Data "Diagnose Response CAN FD";

CM_ SG_ 2549874893 ISOx_TSplit_R_Req_Data "Diagnose Request";

CM_ SG_ 2621440205 ISOx_TSplit_R_Req_FD_Data "Diagnose Request CAN FD";

CM_ SG_ 2550005965 ISOx_TSplit_R_Resp_Data "Diagnose Response";

CM_ SG_ 2621571277 ISOx_TSplit_R_Resp_FD_Data "Diagnose Response CAN FD";

CM_ SG_ 2527679684 Kamera_ASM_Data_1 "Dieses Signal wird von der Frontkamera befüllt und an den Assistenzsystemmonitor ASM gesendet.";
CM_ SG_ 2527679684 Kamera_ASM_Data_2 "Dieses Signal wird von der Frontkamera befüllt und an den Assistenzsystemmonitor ASM gesendet.";
CM_ SG_ 2527679684 Kamera_ASM_Data_3 "Dieses Signal wird von der Frontkamera befüllt und an den Assistenzsystemmonitor ASM gesendet.";
CM_ SG_ 2527679684 Kamera_ASM_Data_4 "Dieses Signal wird von der Frontkamera befüllt und an den Assistenzsystemmonitor ASM gesendet.";
CM_ SG_ 2527679684 Kamera_ASM_Data_5 "Dieses Signal wird von der Frontkamera befüllt und an den Assistenzsystemmonitor ASM gesendet.";
CM_ SG_ 2527679684 Kamera_ASM_Data_6 "Dieses Signal wird von der Frontkamera befüllt und an den Assistenzsystemmonitor ASM gesendet.";
CM_ SG_ 2527679684 Kamera_ASM_Ereignis "Dieses Signal definiert, welche Funktion und welche Art von Aktivität das Senden der Botschaft an den Assistenzsystemmonitor ASM veranlasst hat.";
CM_ SG_ 2527679684 Kamera_ASM_Zeitstempel_02 "Dieses Signal ermöglicht die zeitliche Zuordnung der von der Kamera an den Assistenzsystemmonitor ASM gesendeten Statusbotschaften.";

CM_ SG_ 960 BCM_Ausparken_Betrieb "Anforderung zur erneuten Lampenaufprüfung und Anzeige von Warnhinweisen nach einem pilotierten Ausparkvorgang (Trigger: fallende Flanke)";
CM_ SG_ 960 BCM_Remotestart_Betrieb "Zeigt den Status des RemoteStarts an, d.h. KL15_RSt ist aktiviert und der Motorlauf ist im RSt-Betrieb aktiv.";
CM_ SG_ 960 BCM_Remotestart_KL15_Anf "Zeigt den Status der Aktivierung der KL15_RST durch das BCM an.";
CM_ SG_ 960 BCM_Remotestart_MO_Start "Nachdem das BCM die Remotestart MSG Freigabe sicher erkannt hat, fordert das BCM wiederum über dieses Signal vom MSG einen Motorstart durchzuführen.";
CM_ SG_ 960 Klemmen_Status_01_BZ "4bit Botschaftszaehler; wird in jeder Sendebotschaft inkrementiert";
CM_ SG_ 960 Klemmen_Status_01_CRC "Für MLB:
'Berechnung siehe Lastenheft 'Kommunikationsabsicherung für FlexRay und CAN''

Ab MQB und MLBevo:
'Berechnung siehe Lastenheft 'End-to-End Kommunikationsabsicherung''

Endwerte siehe Begleitdokument 'S-PDU Kennungsfolgen'";
CM_ SG_ 960 KST_Fahrerhinweis_1 "Signalisierung Fahrerhinweis 1 der Klemmensteuerung an das Kombi";
CM_ SG_ 960 KST_Fahrerhinweis_2 "Signalisierung Fahrerhinweis 2 der Klemmensteuerung an das Kombi";
CM_ SG_ 960 KST_Fahrerhinweis_4 "Signalisierung Fahrerhinweis 4 der Klemmensteuerung an das Kombi";
CM_ SG_ 960 KST_Fahrerhinweis_5 "Anzeigesignal für RemoteStart";
CM_ SG_ 960 KST_Fahrerhinweis_6 "Signal aktiviert die Kombi-Anzeigeinstrumente (Drehzahl, Tankinhalt, Kühlmitteltemperatur) während aktiviertem RemoteStart-Betrieb";
CM_ SG_ 960 KST_Warn_P1_ZST_def "Kombi Prio Warnung Klemmensteuerung 
Zündschloß defekt, Service aufsuchen!";
CM_ SG_ 960 KST_Warn_P2_ZST_def "Kombi Prio Warnung Klemmensteuerung
Zündschloß defekt!
";
CM_ SG_ 960 RSt_Fahrerhinweise "Über das Signal fordert das BCM Fahrerhinweise im Kombi für die Funktion RemoteStart an.";
CM_ SG_ 960 ZAS_Kl_15 "Klemme 15: Zuendung (SW-Kl.15)
";
CM_ SG_ 960 ZAS_Kl_50_Startanforderung "Klemme 50: Startwunsch Fahrer
";
CM_ SG_ 960 ZAS_Kl_Infotainment "Separate Klemmeninformation für das Infotainment. Signal entspricht im wesentlichen einer Klemme S Information, kann aber über einen Vor - bzw. Nachlauf zu Klemme S verfügen. 
Ein konkreter Anwendungsfall für einen Nachlauf ist die Abschaltung der Klemme";
CM_ SG_ 960 ZAS_Kl_S "Klemme S: S-Kontakt (Schluessel steckt)
";
CM_ SG_ 960 ZAS_Kl_X "Klemme 75
";

CM_ SG_ 2463978753 Klemmen_Status_02_BZ "4bit Botschaftszähler, wird mit jeder Sendebotschaft inkrementiert";
CM_ SG_ 2463978753 Klemmen_Status_02_CRC "Für MLB:
Berechnung siehe Lastenheft 'Kommunikationsabsicherung für FlexRay und CAN'
Ab MQB und MLBevo:
Berechnung siehe Lastenheft 'End-to-End Kommunikationsabsicherung'

Endwerte siehe Begleitdokument 'S-PDU Kennungsfolgen'";
CM_ SG_ 2463978753 KST_ComfortReadyStatus "Zustand des ComfortReadyStatus über den Komfortfunktionen aktiviert werden können.";
CM_ SG_ 2463978753 KST_Freigabe_Zustand "Gibt den Sperr- bzw. Freigabezustand der Klemmensteuerung während SW-Update (z. B. Infotainment) an";
CM_ SG_ 2463978753 KST_Sonderzustand_Anforderung "Hiermit wird die aktive bzw. aktuell angeforderte (s. KST_Sonderzustand_Status) Sonderfunktion identifiziert";
CM_ SG_ 2463978753 KST_Sonderzustand_Status "Hiermit wird signalisiert, dass eine Sonderfunktion aktiv ist und die Klemme 15 durch diese angefordert wurde bzw. ein Übergang von Sonderfunktionen stattfindet";
CM_ SG_ 2463978753 KST_WFS_Fahrfreigabe_Anforderung "Hiermit wird den Wegfahrsperren-Teilnehmern signalisiert welche Art der Fahrfreigabe von der anfordernden Sonderfunktion benötigt wird";

CM_ SG_ 1505 BCM1_Aussen_Temp_ungef "ungefilterter Wert des Aussentemperatursensors
";
CM_ SG_ 1505 BCM1_FStatus_Aussentemp_ungef "Fehlerstatus für Aussentemperatur (Kombianzeige)";
CM_ SG_ 1505 BCM1_Kompressorstrom_ist "IST-Strom vom Klima-Kompressor";
CM_ SG_ 1505 BCM1_OBD_FStatus_ATemp "Fehlerstatus Umgebungstemperatursensor (OBD relevanter Sensor)
";
CM_ SG_ 1505 BCM1_PTC_stufig_Status "Status des BCM1-Heizverbrauchers PTC (stufig)";
CM_ SG_ 1505 BCM_Heizungsabsperrventil_Status "Das Signal beschreibt den Zustand des Heizungsabsperrventils, welches als Portexpander vom BCM1 elektrisch angesteuert wird.";
CM_ SG_ 1505 BCM_Heizungspumpe_Status "Das Signal beschreibt den Zustand der Heizungspumpe, welche als Portexpander vom BCM1 elektrisch angesteuert wird.";
CM_ SG_ 1505 BCM_Kompressorkupplung_Status "Das Signal beschreibt den Zustand der Klimakompressorkupplung, welche als Portexpander vom BCM1 elektrisch angesteuert wird.";

CM_ SG_ 2549088275 ABS_Abschaltstufe "Funktionseinschränkung aufgrund aktiver Abschaltstufe";
CM_ SG_ 2549088275 ABS_Transport_Mode "Funktionseinschränkung aufgrund aktivem Transport Mode und/oder Transport Schutz";
CM_ SG_ 2549088275 ESP_KompSchutz "Funktionseinschränkung aufgrund Komponentenschutz aktiv";
CM_ SG_ 2549088275 ESP_Nachlauftyp "Abgebildet wird die von der Hardware vorgegebene Möglichkeit, die Kommunikation nach Klemme 15 = AUS aufrecht zu erhalten. Es wird ein Init-Wert gesendet.
0 = Kommunikation nur bei KL15=EIN (kein Nachlauf, nicht weckfähig)
1 = Kommunikation nach KL15=AU";
CM_ SG_ 2549088275 KN_ESP_BusKnockOut "Ausgabe des BusKnockout-Status in der Knotenbotschaft";
CM_ SG_ 2549088275 KN_ESP_BusKnockOutTimer "Ausgabe des BusKnockOut-Timer in der Knotenbotschaft";
CM_ SG_ 2549088275 KN_ESP_DiagPfad "Kennzeichnung der Diagnosefähigkeit des BusInterfaces eines Steuergerätes (Knoten)
Umfang LAH 80127

Bei Nutzung des Signal explizit pro angebundenem BusInterface zu setzen:
MQB AB auf A-CAN,F-CAN = 0 (aktiv)
MQB A0 auf A-CAN = 0 (aktiv)
MQB2020 auf";
CM_ SG_ 2549088275 KN_ESP_ECUKnockOut "Ausgabe des ECUKnockout-Status in der Knotenbotschaft";
CM_ SG_ 2549088275 KN_ESP_ECUKnockOutTimer "Ausgabe des ECUKnockOut-Timer in der Knotenbotschaft";
CM_ SG_ 2549088275 NM_ESP_Wakeup "enthält die Weckursache; stehen mehrere Weckursachen parallel an, dann muss der kleinste Wert übertragen werden";

CM_ SG_ 2549088277 Airbag_01_Abschaltstufe "Funktionseinschränkung aufgrund aktiver Abschaltstufe";
CM_ SG_ 2549088277 Airbag_01_KD_Fehler "Bei gesetztem Bit ist mindestens ein Kundendienstfehler eingetragen";
CM_ SG_ 2549088277 Airbag_01_KompSchutz "Funktionseinschränkung aufgrund Komponentenschutz aktiv";
CM_ SG_ 2549088277 Airbag_01_Nachlauftyp "Abgebildet wird die von der Hardware vorgegebene Möglichkeit, die Kommunikation nach Klemme 15 = AUS aufrecht zu erhalten. Es wird ein Init-Wert gesendet.";
CM_ SG_ 2549088277 Airbag_01_Transport_Mode "Funktionseinschränkung aufgrund aktivem Transport Mode und/oder Transport Schutz";
CM_ SG_ 2549088277 KN_Airbag_01_BusKnockOut "Ausgabe des BusKnockout-Status";
CM_ SG_ 2549088277 KN_Airbag_01_BusKnockOutTimer "Ausgabe des BusKnockOut-Timer";
CM_ SG_ 2549088277 KN_Airbag_01_DiagPfad "Kennzeichnung der Diagnosefähigkeit des BusInterfaces eines Steuergerätes (Knoten)
Umfang LAH 80127

Bei Nutzung des Signal explizit pro angebundenem BusInterface zu setzen:
MQBw_Baseline auf F-CANFD 1 = 0 (aktiv)";
CM_ SG_ 2549088277 KN_Airbag_01_ECUKnockOut "Ausgabe des ECUKnockout-Status";
CM_ SG_ 2549088277 KN_Airbag_01_ECUKnockOutTimer "Ausgabe des ECUKnockOut-Timer";
CM_ SG_ 2549088277 NM_Airbag_01_Wakeup "enthält die Weckursache; stehen mehrere Weckursachen parallel an, dann muss der kleinste Wert übertragen werden";
BA_DEF_REL_ BU_SG_REL_  "GenSigTimeoutTime" INT 0 65535;
BA_DEF_ BO_  "DiagRequest" ENUM "No", "Yes";
BA_DEF_ BO_  "DiagResponse" ENUM "No", "Yes";
BA_DEF_ BO_  "DiagState" ENUM "No", "Yes";
BA_DEF_ BO_  "GenMsgChkConstant" HEX 0 4095;
BA_DEF_ BO_  "GenMsgCycleTime" INT 0 65535;
BA_DEF_ BO_  "GenMsgCycleTimeFast" INT 0 65535;
BA_DEF_ BO_  "GenMsgDelayTime" INT 0 100000;
BA_DEF_ BO_  "GenMsgILSupport" ENUM "No", "Yes";
BA_DEF_ BO_  "GenMsgNrOfRepetition" INT 0 100;
BA_DEF_ BO_  "GenMsgPDUConstants" STRING;
BA_DEF_ BO_  "GenMsgSendType" ENUM "Cyclic", "not_used", "not_used", "not_used", "not_used", "not_used", "not_used", "IfActive", "NoMsgSendType";
BA_DEF_ BO_  "GenMsgStartDelayTime" INT 0 100000;
BA_DEF_ BO_  "NmMessage" ENUM "No", "Yes";
BA_DEF_ BO_  "NmhMessage" ENUM "No", "Yes";
BA_DEF_ BO_  "MsgType" ENUM "Application", "NM ", "NMH", "TP2.0", "ISO-TP ", "BAP", "EID", "KS", "XCP_PRE_CONFIGURED", "XCP_RUNTIME_CONFIGURED";
BA_DEF_ BO_  "VAGTP20_API" HEX 0 255;
BA_DEF_ BO_  "VAGTP20_DynConnection" ENUM "No", "Yes";
BA_DEF_ BO_  "VAGTP20_DynSetup" ENUM "No", "Yes";
BA_DEF_ BO_  "VAGTP20_StatConnection" ENUM "No", "Yes";
BA_DEF_ BO_  "CANFD_BRS" ENUM "0", "1";
BA_DEF_ BO_  "VFrameFormat" ENUM "StandardCAN", "ExtendedCAN", "reserved", "reserved", "reserved", "reserved", "reserved", "reserved", "reserved", "reserved", "reserved", "reserved", "reserved", "reserved", "StandardCAN_FD", "ExtendedCAN_FD";
BA_DEF_ SG_  "GenSigActiveRepetitions" INT -2147483648 2147483647;
BA_DEF_ SG_  "GenSigInactiveValue" INT -2147483648 2147483647;
BA_DEF_ SG_  "GenSigSendType" ENUM "Cyclic", "OnWrite", "OnWriteWithRepetition", "OnChange", "OnChangeWithRepetition", "IfActive", "IfActiveWithRepetition", "NoSigSendType", "OnChangeAndIfActive", "OnChangeAndIfActiveWithRepetition";
BA_DEF_ SG_  "GenSigStartValue" INT -2147483648 2147483647;
BA_DEF_ SG_  "NWM-WakeupAllowed" ENUM "No", "Yes";
BA_DEF_ SG_  "GenSigFuncType" ENUM "NoFunction", "MsgCounter", "CRC-8", "XOR", "XOR-2", "DatedBit", "SW-Kl15", "CHK", "Constant", "Protocol", "CRC-8-SAE_J1850", "CRC-32", "DataLength", "DataID", "MsgCounter16", "SOK-Signatur", "Cluster";
BA_DEF_ SG_  "GenSigSwitchedByIgnition" ENUM "No", "Yes";
BA_DEF_ SG_  "Fehlerwert" HEX 0 2147483647;
BA_DEF_ SG_  "GenSigMissingSourceValue" HEX 0 2147483647;
BA_DEF_DEF_REL_  "GenSigTimeoutTime" 0;
BA_DEF_DEF_  "DiagRequest" "No";
BA_DEF_DEF_  "DiagResponse" "No";
BA_DEF_DEF_  "DiagState" "No";
BA_DEF_DEF_  "GenMsgChkConstant" 0;
BA_DEF_DEF_  "GenMsgCycleTime" 0;
BA_DEF_DEF_  "GenMsgCycleTimeFast" 0;
BA_DEF_DEF_  "GenMsgDelayTime" 0;
BA_DEF_DEF_  "GenMsgILSupport" "No";
BA_DEF_DEF_  "GenMsgNrOfRepetition" 0;
BA_DEF_DEF_  "GenMsgPDUConstants" "";
BA_DEF_DEF_  "GenMsgSendType" "NoMsgSendType";
BA_DEF_DEF_  "GenMsgStartDelayTime" 0;
BA_DEF_DEF_  "NmMessage" "No";
BA_DEF_DEF_  "NmhMessage" "No";
BA_DEF_DEF_  "MsgType" "Application";
BA_DEF_DEF_  "VAGTP20_API" 0;
BA_DEF_DEF_  "VAGTP20_DynConnection" "No";
BA_DEF_DEF_  "VAGTP20_DynSetup" "No";
BA_DEF_DEF_  "VAGTP20_StatConnection" "No";
BA_DEF_DEF_  "CANFD_BRS" "1";
BA_DEF_DEF_  "VFrameFormat" "StandardCAN";
BA_DEF_DEF_  "GenSigActiveRepetitions" 0;
BA_DEF_DEF_  "GenSigInactiveValue" 0;
BA_DEF_DEF_  "GenSigSendType" "NoSigSendType";
BA_DEF_DEF_  "GenSigStartValue" 0;
BA_DEF_DEF_  "NWM-WakeupAllowed" "No";
BA_DEF_DEF_  "GenSigFuncType" "NoFunction";
BA_DEF_DEF_  "GenSigSwitchedByIgnition" "Yes";
BA_DEF_DEF_  "Fehlerwert" 0;
BA_DEF_DEF_  "GenSigMissingSourceValue" 0;
BA_ "GenMsgCycleTime" BO_ 2463978866 200;
BA_ "GenMsgDelayTime" BO_ 2463978866 50;
BA_ "GenMsgILSupport" BO_ 2463978866 1;
BA_ "GenMsgSendType" BO_ 2463978866 0;
BA_ "VFrameFormat" BO_ 2463978866 15;
BA_ "GenMsgCycleTime" BO_ 173 50;
BA_ "GenMsgILSupport" BO_ 173 1;
BA_ "GenMsgPDUConstants" BO_ 173 "0x3f,0x69,0x39,0xdc,0x94,0xf9,0x14,0x64,0xd8,0x6a,0x34,0xce,0xa2,0x55,0xb5,0x2c";
BA_ "GenMsgSendType" BO_ 173 0;
BA_ "VFrameFormat" BO_ 173 14;
BA_ "GenMsgCycleTime" BO_ 270 10;
BA_ "GenMsgILSupport" BO_ 270 1;
BA_ "GenMsgPDUConstants" BO_ 270 "0xd9,0xed,0xb6,0x03,0xa2,0x1c,0x8d,0x13,0xc1,0xc6,0xcd,0x23,0xfb,0x78,0x6d,0x7a";
BA_ "GenMsgSendType" BO_ 270 0;
BA_ "VFrameFormat" BO_ 270 14;
BA_ "GenMsgCycleTime" BO_ 509 100;
BA_ "GenMsgCycleTimeFast" BO_ 509 10;
BA_ "GenMsgDelayTime" BO_ 509 10;
BA_ "GenMsgILSupport" BO_ 509 1;
BA_ "GenMsgNrOfRepetition" BO_ 509 3;
BA_ "GenMsgPDUConstants" BO_ 509 "0xb3,0xeb,0xe1,0xf7,0xba,0x9e,0x5f,0xd9,0xc2,0xec,0xf6,0xe9,0x24,0x18,0x48,0xed";
BA_ "GenMsgSendType" BO_ 509 0;
BA_ "VFrameFormat" BO_ 509 14;
BA_ "GenMsgCycleTime" BO_ 891 1000;
BA_ "GenMsgILSupport" BO_ 891 1;
BA_ "GenMsgSendType" BO_ 891 0;
BA_ "VFrameFormat" BO_ 891 14;
BA_ "GenMsgCycleTime" BO_ 771 1000;
BA_ "GenMsgCycleTimeFast" BO_ 771 20;
BA_ "GenMsgILSupport" BO_ 771 1;
BA_ "GenMsgNrOfRepetition" BO_ 771 5;
BA_ "GenMsgSendType" BO_ 771 0;
BA_ "VFrameFormat" BO_ 771 14;
BA_ "GenMsgCycleTime" BO_ 626 100;
BA_ "GenMsgDelayTime" BO_ 626 10;
BA_ "GenMsgILSupport" BO_ 626 1;
BA_ "GenMsgSendType" BO_ 626 0;
BA_ "VFrameFormat" BO_ 626 14;
BA_ "GenMsgCycleTime" BO_ 2589283966 500;
BA_ "GenMsgILSupport" BO_ 2589283966 1;
BA_ "GenMsgSendType" BO_ 2589283966 0;
BA_ "VFrameFormat" BO_ 2589283966 15;
BA_ "GenMsgCycleTime" BO_ 182 10;
BA_ "GenMsgILSupport" BO_ 182 1;
BA_ "GenMsgPDUConstants" BO_ 182 "0x4e,0x56,0x99,0x3f,0x75,0xc5,0x70,0x69,0xa3,0x47,0xb7,0x39,0xec,0xcd,0x96,0xdc";
BA_ "GenMsgSendType" BO_ 182 0;
BA_ "VFrameFormat" BO_ 182 14;
BA_ "GenMsgCycleTime" BO_ 312 100;
BA_ "GenMsgILSupport" BO_ 312 1;
BA_ "GenMsgPDUConstants" BO_ 312 "0x77,0x4e,0x14,0x87,0xf2,0xf8,0xb2,0x61,0xf6,0xa4,0x52,0x94,0xd4,0x81,0x2a,0xb1";
BA_ "GenMsgSendType" BO_ 312 0;
BA_ "VFrameFormat" BO_ 312 14;
BA_ "GenMsgCycleTime" BO_ 2527679583 1000;
BA_ "GenMsgCycleTimeFast" BO_ 2527679583 100;
BA_ "GenMsgDelayTime" BO_ 2527679583 50;
BA_ "GenMsgILSupport" BO_ 2527679583 1;
BA_ "GenMsgNrOfRepetition" BO_ 2527679583 5;
BA_ "GenMsgPDUConstants" BO_ 2527679583 "0xc6,0x7f,0x85,0xb6,0xe6,0xae,0xf8,0x26,0xb0,0x8c,0x19,0x10,0x5b,0x33,0x64,0x6c";
BA_ "GenMsgSendType" BO_ 2527679583 0;
BA_ "VFrameFormat" BO_ 2527679583 15;
BA_ "DiagRequest" BO_ 1811 1;
BA_ "MsgType" BO_ 1811 4;
BA_ "VFrameFormat" BO_ 1811 14;
BA_ "DiagResponse" BO_ 1917 1;
BA_ "MsgType" BO_ 1917 4;
BA_ "VFrameFormat" BO_ 1917 14;
BA_ "DiagRequest" BO_ 1813 1;
BA_ "MsgType" BO_ 1813 4;
BA_ "VFrameFormat" BO_ 1813 14;
BA_ "DiagResponse" BO_ 1919 1;
BA_ "MsgType" BO_ 1919 4;
BA_ "VFrameFormat" BO_ 1919 14;
BA_ "DiagRequest" BO_ 1807 1;
BA_ "MsgType" BO_ 1807 4;
BA_ "VFrameFormat" BO_ 1807 14;
BA_ "DiagResponse" BO_ 1913 1;
BA_ "MsgType" BO_ 1913 4;
BA_ "VFrameFormat" BO_ 1913 14;
BA_ "DiagRequest" BO_ 1906 1;
BA_ "MsgType" BO_ 1906 4;
BA_ "VFrameFormat" BO_ 1906 14;
BA_ "DiagResponse" BO_ 2012 1;
BA_ "MsgType" BO_ 2012 4;
BA_ "VFrameFormat" BO_ 2012 14;
BA_ "DiagRequest" BO_ 1851 1;
BA_ "MsgType" BO_ 1851 4;
BA_ "VFrameFormat" BO_ 1851 14;
BA_ "DiagResponse" BO_ 1957 1;
BA_ "MsgType" BO_ 1957 4;
BA_ "VFrameFormat" BO_ 1957 14;
BA_ "DiagState" BO_ 1792 1;
BA_ "MsgType" BO_ 1792 4;
BA_ "VFrameFormat" BO_ 1792 14;
BA_ "DiagRequest" BO_ 1810 1;
BA_ "MsgType" BO_ 1810 4;
BA_ "VFrameFormat" BO_ 1810 14;
BA_ "DiagResponse" BO_ 1916 1;
BA_ "MsgType" BO_ 1916 4;
BA_ "VFrameFormat" BO_ 1916 14;
BA_ "DiagRequest" BO_ 1822 1;
BA_ "MsgType" BO_ 1822 4;
BA_ "VFrameFormat" BO_ 1822 14;
BA_ "DiagResponse" BO_ 1928 1;
BA_ "MsgType" BO_ 1928 4;
BA_ "VFrameFormat" BO_ 1928 14;
BA_ "DiagRequest" BO_ 2621440019 1;
BA_ "MsgType" BO_ 2621440019 4;
BA_ "VFrameFormat" BO_ 2621440019 15;
BA_ "DiagResponse" BO_ 2621571091 1;
BA_ "MsgType" BO_ 2621571091 4;
BA_ "VFrameFormat" BO_ 2621571091 15;
BA_ "DiagRequest" BO_ 2621440021 1;
BA_ "MsgType" BO_ 2621440021 4;
BA_ "VFrameFormat" BO_ 2621440021 15;
BA_ "DiagResponse" BO_ 2621571093 1;
BA_ "MsgType" BO_ 2621571093 4;
BA_ "VFrameFormat" BO_ 2621571093 15;
BA_ "DiagRequest" BO_ 2621440015 1;
BA_ "MsgType" BO_ 2621440015 4;
BA_ "VFrameFormat" BO_ 2621440015 15;
BA_ "DiagResponse" BO_ 2621571087 1;
BA_ "MsgType" BO_ 2621571087 4;
BA_ "VFrameFormat" BO_ 2621571087 15;
BA_ "DiagRequest" BO_ 2621440114 1;
BA_ "MsgType" BO_ 2621440114 4;
BA_ "VFrameFormat" BO_ 2621440114 15;
BA_ "DiagResponse" BO_ 2621571186 1;
BA_ "MsgType" BO_ 2621571186 4;
BA_ "VFrameFormat" BO_ 2621571186 15;
BA_ "DiagRequest" BO_ 2621440059 1;
BA_ "MsgType" BO_ 2621440059 4;
BA_ "VFrameFormat" BO_ 2621440059 15;
BA_ "DiagResponse" BO_ 2621571131 1;
BA_ "MsgType" BO_ 2621571131 4;
BA_ "VFrameFormat" BO_ 2621571131 15;
BA_ "DiagState" BO_ 2621505536 1;
BA_ "MsgType" BO_ 2621505536 4;
BA_ "VFrameFormat" BO_ 2621505536 15;
BA_ "DiagRequest" BO_ 2621440018 1;
BA_ "MsgType" BO_ 2621440018 4;
BA_ "VFrameFormat" BO_ 2621440018 15;
BA_ "DiagResponse" BO_ 2621571090 1;
BA_ "MsgType" BO_ 2621571090 4;
BA_ "VFrameFormat" BO_ 2621571090 15;
BA_ "DiagRequest" BO_ 2621440030 1;
BA_ "MsgType" BO_ 2621440030 4;
BA_ "VFrameFormat" BO_ 2621440030 15;
BA_ "DiagResponse" BO_ 2621571102 1;
BA_ "MsgType" BO_ 2621571102 4;
BA_ "VFrameFormat" BO_ 2621571102 15;
BA_ "DiagRequest" BO_ 2549874892 1;
BA_ "MsgType" BO_ 2549874892 4;
BA_ "VFrameFormat" BO_ 2549874892 15;
BA_ "DiagRequest" BO_ 2621440204 1;
BA_ "MsgType" BO_ 2621440204 4;
BA_ "VFrameFormat" BO_ 2621440204 15;
BA_ "DiagResponse" BO_ 2550005964 1;
BA_ "MsgType" BO_ 2550005964 4;
BA_ "VFrameFormat" BO_ 2550005964 15;
BA_ "DiagResponse" BO_ 2621571276 1;
BA_ "MsgType" BO_ 2621571276 4;
BA_ "VFrameFormat" BO_ 2621571276 15;
BA_ "DiagRequest" BO_ 2549874893 1;
BA_ "MsgType" BO_ 2549874893 4;
BA_ "VFrameFormat" BO_ 2549874893 15;
BA_ "DiagRequest" BO_ 2621440205 1;
BA_ "MsgType" BO_ 2621440205 4;
BA_ "VFrameFormat" BO_ 2621440205 15;
BA_ "DiagResponse" BO_ 2550005965 1;
BA_ "MsgType" BO_ 2550005965 4;
BA_ "VFrameFormat" BO_ 2550005965 15;
BA_ "DiagResponse" BO_ 2621571277 1;
BA_ "MsgType" BO_ 2621571277 4;
BA_ "VFrameFormat" BO_ 2621571277 15;
BA_ "GenMsgCycleTime" BO_ 2527679684 2000;
BA_ "GenMsgDelayTime" BO_ 2527679684 100;
BA_ "GenMsgILSupport" BO_ 2527679684 1;
BA_ "GenMsgSendType" BO_ 2527679684 0;
BA_ "VFrameFormat" BO_ 2527679684 15;
BA_ "GenMsgChkConstant" BO_ 960 195;
BA_ "GenMsgCycleTime" BO_ 960 100;
BA_ "GenMsgDelayTime" BO_ 960 10;
BA_ "GenMsgILSupport" BO_ 960 1;
BA_ "GenMsgPDUConstants" BO_ 960 "0xc3,0xc3,0xc3,0xc3,0xc3,0xc3,0xc3,0xc3,0xc3,0xc3,0xc3,0xc3,0xc3,0xc3,0xc3,0xc3";
BA_ "GenMsgSendType" BO_ 960 0;
BA_ "VFrameFormat" BO_ 960 14;
BA_ "GenMsgCycleTime" BO_ 2463978753 1000;
BA_ "GenMsgCycleTimeFast" BO_ 2463978753 100;
BA_ "GenMsgDelayTime" BO_ 2463978753 10;
BA_ "GenMsgILSupport" BO_ 2463978753 1;
BA_ "GenMsgNrOfRepetition" BO_ 2463978753 5;
BA_ "GenMsgPDUConstants" BO_ 2463978753 "0x80,0xf1,0xa5,0xaf,0x94,0x59,0xe8,0x8c,0x03,0xd4,0xf5,0x5e,0xec,0x73,0x81,0x50";
BA_ "GenMsgSendType" BO_ 2463978753 0;
BA_ "VFrameFormat" BO_ 2463978753 15;
BA_ "GenMsgCycleTime" BO_ 1505 200;
BA_ "GenMsgILSupport" BO_ 1505 1;
BA_ "GenMsgSendType" BO_ 1505 0;
BA_ "VFrameFormat" BO_ 1505 14;
BA_ "GenMsgCycleTime" BO_ 2549088275 500;
BA_ "GenMsgILSupport" BO_ 2549088275 1;
BA_ "GenMsgSendType" BO_ 2549088275 0;
BA_ "VFrameFormat" BO_ 2549088275 15;
BA_ "GenMsgCycleTime" BO_ 2549088277 500;
BA_ "GenMsgILSupport" BO_ 2549088277 1;
BA_ "GenMsgSendType" BO_ 2549088277 0;
BA_ "VFrameFormat" BO_ 2549088277 15;
BA_ "GenSigSendType" SG_ 2463978866 ARA_Status 3;
BA_ "GenSigStartValue" SG_ 2463978866 ARA_Status 1;
BA_ "Fehlerwert" SG_ 2463978866 ARA_Status 2;
BA_ "GenSigSendType" SG_ 2463978866 ARA_Status_01_alt 0;
BA_ "GenSigStartValue" SG_ 2463978866 ARA_Status_01_alt 1;
BA_ "GenSigFuncType" SG_ 2463978866 ARA_Status_01_alt 5;
BA_ "GenSigSwitchedByIgnition" SG_ 2463978866 ARA_Status_01_alt 0;
BA_ "GenSigSendType" SG_ 2463978866 Kamera_Status_alt 0;
BA_ "GenSigStartValue" SG_ 2463978866 Kamera_Status_alt 1;
BA_ "GenSigFuncType" SG_ 2463978866 Kamera_Status_alt 5;
BA_ "GenSigSwitchedByIgnition" SG_ 2463978866 Kamera_Status_alt 0;
BA_ "GenSigSendType" SG_ 2463978866 KLR_01_alt 0;
BA_ "GenSigStartValue" SG_ 2463978866 KLR_01_alt 1;
BA_ "GenSigFuncType" SG_ 2463978866 KLR_01_alt 5;
BA_ "GenSigSwitchedByIgnition" SG_ 2463978866 KLR_01_alt 0;
BA_ "GenSigSendType" SG_ 2463978866 KLR_Touchauswertung 3;
BA_ "GenSigStartValue" SG_ 2463978866 KLR_Touchauswertung 14;
BA_ "GenSigSwitchedByIgnition" SG_ 2463978866 KLR_Touchauswertung 0;
BA_ "GenSigSendType" SG_ 2463978866 LDW_02_alt 0;
BA_ "GenSigStartValue" SG_ 2463978866 LDW_02_alt 1;
BA_ "GenSigFuncType" SG_ 2463978866 LDW_02_alt 5;
BA_ "GenSigSwitchedByIgnition" SG_ 2463978866 LDW_02_alt 0;
BA_ "GenSigSendType" SG_ 2463978866 LDW_Lernmodus_seitenabhaengig 3;
BA_ "GenSigSendType" SG_ 2463978866 LDW_Status_Anzeige 3;
BA_ "GenSigSendType" SG_ 2463978866 LDW_Status_LED_gelb 3;
BA_ "GenSigSendType" SG_ 2463978866 LDW_Status_LED_gruen 3;
BA_ "GenSigSendType" SG_ 2463978866 LDW_Texte 3;
BA_ "GenSigSendType" SG_ 2463978866 PLA_04_alt 0;
BA_ "GenSigStartValue" SG_ 2463978866 PLA_04_alt 1;
BA_ "GenSigFuncType" SG_ 2463978866 PLA_04_alt 5;
BA_ "GenSigSwitchedByIgnition" SG_ 2463978866 PLA_04_alt 0;
BA_ "GenSigSendType" SG_ 2463978866 PLA_06_alt 0;
BA_ "GenSigFuncType" SG_ 2463978866 PLA_06_alt 5;
BA_ "GenSigSwitchedByIgnition" SG_ 2463978866 PLA_06_alt 0;
BA_ "GenSigSendType" SG_ 2463978866 PLAIPA_PaCo_FunctionState 3;
BA_ "GenSigStartValue" SG_ 2463978866 PLAIPA_PaCo_FunctionState 1;
BA_ "GenSigSwitchedByIgnition" SG_ 2463978866 PLAIPA_PaCo_FunctionState 0;
BA_ "GenSigSendType" SG_ 2463978866 PLAIPA_PaCo_MainState 3;
BA_ "GenSigSwitchedByIgnition" SG_ 2463978866 PLAIPA_PaCo_MainState 0;
BA_ "Fehlerwert" SG_ 2463978866 PLAIPA_PaCo_MainState 7;
BA_ "GenSigSendType" SG_ 2463978866 RA_Status 3;
BA_ "GenSigStartValue" SG_ 2463978866 RA_Status 1;
BA_ "GenSigSwitchedByIgnition" SG_ 2463978866 RA_Status 0;
BA_ "GenSigSendType" SG_ 2463978866 RDK_02_alt 0;
BA_ "GenSigStartValue" SG_ 2463978866 RDK_02_alt 1;
BA_ "GenSigFuncType" SG_ 2463978866 RDK_02_alt 5;
BA_ "GenSigSwitchedByIgnition" SG_ 2463978866 RDK_02_alt 0;
BA_ "GenSigSendType" SG_ 2463978866 RDK_11_alt 0;
BA_ "GenSigStartValue" SG_ 2463978866 RDK_11_alt 1;
BA_ "GenSigFuncType" SG_ 2463978866 RDK_11_alt 5;
BA_ "GenSigSwitchedByIgnition" SG_ 2463978866 RDK_11_alt 0;
BA_ "GenSigSendType" SG_ 2463978866 RDK_FMVSS138_Lampe 3;
BA_ "GenSigSwitchedByIgnition" SG_ 2463978866 RDK_FMVSS138_Lampe 0;
BA_ "GenSigSendType" SG_ 2463978866 RDK_FMVSS138_MIL 3;
BA_ "GenSigSwitchedByIgnition" SG_ 2463978866 RDK_FMVSS138_MIL 0;
BA_ "GenSigSendType" SG_ 2463978866 TA_01_alt 0;
BA_ "GenSigStartValue" SG_ 2463978866 TA_01_alt 1;
BA_ "GenSigFuncType" SG_ 2463978866 TA_01_alt 5;
BA_ "GenSigSwitchedByIgnition" SG_ 2463978866 TA_01_alt 0;
BA_ "GenSigSendType" SG_ 2463978866 TA_aktiv_HMI 3;
BA_ "GenSigSendType" SG_ 2463978866 TA_Fehler 3;
BA_ "GenSigSendType" SG_ 2463978866 TA_Handsoff_LED 3;
BA_ "GenSigSendType" SG_ 2463978866 TA_Spurwechsel 3;
BA_ "GenSigSendType" SG_ 2463978866 TA_Status 3;
BA_ "GenSigSendType" SG_ 2463978866 TA_Texte 3;
BA_ "GenSigSendType" SG_ 2463978866 TA_Texte_02 3;
BA_ "GenSigSendType" SG_ 2463978866 TPA_02_alt 0;
BA_ "GenSigStartValue" SG_ 2463978866 TPA_02_alt 1;
BA_ "GenSigFuncType" SG_ 2463978866 TPA_02_alt 5;
BA_ "GenSigSwitchedByIgnition" SG_ 2463978866 TPA_02_alt 0;
BA_ "GenSigSendType" SG_ 2463978866 TPA_Status 3;
BA_ "GenSigStartValue" SG_ 2463978866 TPA_Status 1;
BA_ "GenSigSwitchedByIgnition" SG_ 2463978866 TPA_Status 0;
BA_ "GenSigSendType" SG_ 2463978866 TPMS_WarnLmpStMil 3;
BA_ "GenSigSendType" SG_ 2463978866 TPMS_WarnLmpStP 3;
BA_ "GenSigSendType" SG_ 2463978866 VZE_Status_EDR 3;
BA_ "GenSigSendType" SG_ 2463978866 WBA_05_alt 0;
BA_ "GenSigStartValue" SG_ 2463978866 WBA_05_alt 1;
BA_ "GenSigFuncType" SG_ 2463978866 WBA_05_alt 5;
BA_ "GenSigSwitchedByIgnition" SG_ 2463978866 WBA_05_alt 0;
BA_ "GenSigSendType" SG_ 2463978866 WBA_Status_AWU 3;
BA_ "GenSigStartValue" SG_ 2463978866 WBA_Status_AWU 1;
BA_ "Fehlerwert" SG_ 2463978866 WBA_Status_AWU 15;
BA_ "GenSigSendType" SG_ 173 GE_Fahrstufe 0;
BA_ "GenSigStartValue" SG_ 173 GE_Fahrstufe 1;
BA_ "GenSigSwitchedByIgnition" SG_ 173 GE_Fahrstufe 0;
BA_ "Fehlerwert" SG_ 173 GE_Fahrstufe 15;
BA_ "GenSigSendType" SG_ 173 GE_Ursache_Fahrstufe_N 0;
BA_ "GenSigSwitchedByIgnition" SG_ 173 GE_Ursache_Fahrstufe_N 0;
BA_ "GenSigSendType" SG_ 173 Getriebe_11_BZ 0;
BA_ "GenSigFuncType" SG_ 173 Getriebe_11_BZ 1;
BA_ "GenSigSwitchedByIgnition" SG_ 173 Getriebe_11_BZ 0;
BA_ "GenSigSendType" SG_ 173 Getriebe_11_CRC 0;
BA_ "GenSigFuncType" SG_ 173 Getriebe_11_CRC 2;
BA_ "GenSigSwitchedByIgnition" SG_ 173 Getriebe_11_CRC 0;
BA_ "GenSigSendType" SG_ 270 GE2_Fahrstufe 0;
BA_ "GenSigStartValue" SG_ 270 GE2_Fahrstufe 1;
BA_ "GenSigSwitchedByIgnition" SG_ 270 GE2_Fahrstufe 0;
BA_ "Fehlerwert" SG_ 270 GE2_Fahrstufe 15;
BA_ "GenSigSendType" SG_ 270 GE2_Ursache_Fahrstufe_N 0;
BA_ "GenSigSwitchedByIgnition" SG_ 270 GE2_Ursache_Fahrstufe_N 0;
BA_ "GenSigSendType" SG_ 270 GE_Abtriebsdrehzahl 0;
BA_ "GenSigStartValue" SG_ 270 GE_Abtriebsdrehzahl 65534;
BA_ "GenSigSwitchedByIgnition" SG_ 270 GE_Abtriebsdrehzahl 0;
BA_ "Fehlerwert" SG_ 270 GE_Abtriebsdrehzahl 65535;
BA_ "GenSigSendType" SG_ 270 GE_Anf_Zylabsch 0;
BA_ "GenSigSwitchedByIgnition" SG_ 270 GE_Anf_Zylabsch 0;
BA_ "GenSigSendType" SG_ 270 GE_Anheb_Solldrehz_Leerlauf 0;
BA_ "GenSigSwitchedByIgnition" SG_ 270 GE_Anheb_Solldrehz_Leerlauf 0;
BA_ "Fehlerwert" SG_ 270 GE_Anheb_Solldrehz_Leerlauf 255;
BA_ "GenSigSendType" SG_ 270 GE_Aufnahmemoment 0;
BA_ "GenSigStartValue" SG_ 270 GE_Aufnahmemoment 1022;
BA_ "GenSigSwitchedByIgnition" SG_ 270 GE_Aufnahmemoment 0;
BA_ "Fehlerwert" SG_ 270 GE_Aufnahmemoment 1023;
BA_ "GenSigSendType" SG_ 270 GE_Drehzahlmesser_Daempfung 0;
BA_ "GenSigSwitchedByIgnition" SG_ 270 GE_Drehzahlmesser_Daempfung 0;
BA_ "GenSigSendType" SG_ 270 GE_Eingangsdrehz 0;
BA_ "GenSigStartValue" SG_ 270 GE_Eingangsdrehz 16382;
BA_ "GenSigSwitchedByIgnition" SG_ 270 GE_Eingangsdrehz 0;
BA_ "Fehlerwert" SG_ 270 GE_Eingangsdrehz 16383;
BA_ "GenSigSendType" SG_ 270 GE_Eingangswellengradient 0;
BA_ "GenSigStartValue" SG_ 270 GE_Eingangswellengradient 65534;
BA_ "GenSigSwitchedByIgnition" SG_ 270 GE_Eingangswellengradient 0;
BA_ "Fehlerwert" SG_ 270 GE_Eingangswellengradient 65535;
BA_ "GenSigSendType" SG_ 270 GE_Entkopplung_Status 0;
BA_ "GenSigSwitchedByIgnition" SG_ 270 GE_Entkopplung_Status 0;
BA_ "GenSigSendType" SG_ 270 GE_Fahrstufenwunsch 0;
BA_ "GenSigStartValue" SG_ 270 GE_Fahrstufenwunsch 1;
BA_ "GenSigSwitchedByIgnition" SG_ 270 GE_Fahrstufenwunsch 0;
BA_ "Fehlerwert" SG_ 270 GE_Fahrstufenwunsch 15;
BA_ "GenSigSendType" SG_ 270 GE_Freig_Langfr_Schutzmom 0;
BA_ "GenSigSwitchedByIgnition" SG_ 270 GE_Freig_Langfr_Schutzmom 0;
BA_ "GenSigSendType" SG_ 270 GE_Freig_MMom_Vorhalt 0;
BA_ "GenSigSwitchedByIgnition" SG_ 270 GE_Freig_MMom_Vorhalt 0;
BA_ "GenSigSendType" SG_ 270 GE_Freigabe_Synchro 0;
BA_ "GenSigSwitchedByIgnition" SG_ 270 GE_Freigabe_Synchro 0;
BA_ "GenSigSendType" SG_ 270 GE_Grenzkriechmoment 0;
BA_ "GenSigStartValue" SG_ 270 GE_Grenzkriechmoment 62;
BA_ "GenSigSwitchedByIgnition" SG_ 270 GE_Grenzkriechmoment 0;
BA_ "Fehlerwert" SG_ 270 GE_Grenzkriechmoment 63;
BA_ "GenSigSendType" SG_ 270 GE_HYB_DZ_Eingriff 0;
BA_ "GenSigSwitchedByIgnition" SG_ 270 GE_HYB_DZ_Eingriff 0;
BA_ "GenSigSendType" SG_ 270 GE_HYB_EM_KompMom 0;
BA_ "GenSigSwitchedByIgnition" SG_ 270 GE_HYB_EM_KompMom 0;
BA_ "GenSigSendType" SG_ 270 GE_HYB_Fehlerstatus 0;
BA_ "GenSigSwitchedByIgnition" SG_ 270 GE_HYB_Fehlerstatus 0;
BA_ "GenSigSendType" SG_ 270 GE_HYB_Filt_MomAufbau 0;
BA_ "GenSigSwitchedByIgnition" SG_ 270 GE_HYB_Filt_MomAufbau 0;
BA_ "GenSigSendType" SG_ 270 GE_HYB_Freig_VM_EM_Stop 0;
BA_ "GenSigSwitchedByIgnition" SG_ 270 GE_HYB_Freig_VM_EM_Stop 0;
BA_ "GenSigSendType" SG_ 270 GE_HYB_Freigabe_K0 0;
BA_ "GenSigSwitchedByIgnition" SG_ 270 GE_HYB_Freigabe_K0 0;
BA_ "GenSigSendType" SG_ 270 GE_HYB_Freigabe_LL_Reg 0;
BA_ "GenSigStartValue" SG_ 270 GE_HYB_Freigabe_LL_Reg 1;
BA_ "GenSigSwitchedByIgnition" SG_ 270 GE_HYB_Freigabe_LL_Reg 0;
BA_ "GenSigSendType" SG_ 270 GE_HYB_IstStatus_K0 0;
BA_ "GenSigSwitchedByIgnition" SG_ 270 GE_HYB_IstStatus_K0 0;
BA_ "Fehlerwert" SG_ 270 GE_HYB_IstStatus_K0 3;
BA_ "GenSigSendType" SG_ 270 GE_HYB_MaxMomK0 0;
BA_ "GenSigSwitchedByIgnition" SG_ 270 GE_HYB_MaxMomK0 0;
BA_ "GenSigSendType" SG_ 270 GE_HYB_nK0 0;
BA_ "GenSigSwitchedByIgnition" SG_ 270 GE_HYB_nK0 0;
BA_ "Fehlerwert" SG_ 270 GE_HYB_nK0 255;
BA_ "GenSigSendType" SG_ 270 GE_HYB_Sportfaktor 0;
BA_ "GenSigSwitchedByIgnition" SG_ 270 GE_HYB_Sportfaktor 0;
BA_ "GenSigSendType" SG_ 270 GE_HYB_StartAnf 0;
BA_ "GenSigSwitchedByIgnition" SG_ 270 GE_HYB_StartAnf 0;
BA_ "GenSigSendType" SG_ 270 GE_HYB_VM_akt_halten 0;
BA_ "GenSigSwitchedByIgnition" SG_ 270 GE_HYB_VM_akt_halten 0;
BA_ "GenSigSendType" SG_ 270 GE_HYB_VM_Soll_Moment 0;
BA_ "GenSigStartValue" SG_ 270 GE_HYB_VM_Soll_Moment 254;
BA_ "GenSigSwitchedByIgnition" SG_ 270 GE_HYB_VM_Soll_Moment 0;
BA_ "Fehlerwert" SG_ 270 GE_HYB_VM_Soll_Moment 255;
BA_ "GenSigSendType" SG_ 270 GE_HYB_VM_Startkontr 0;
BA_ "GenSigSwitchedByIgnition" SG_ 270 GE_HYB_VM_Startkontr 0;
BA_ "GenSigSendType" SG_ 270 GE_HYB_Wiederstart 0;
BA_ "GenSigSwitchedByIgnition" SG_ 270 GE_HYB_Wiederstart 0;
BA_ "GenSigSendType" SG_ 270 GE_HYB_Wiederstartreserve 0;
BA_ "GenSigSwitchedByIgnition" SG_ 270 GE_HYB_Wiederstartreserve 0;
BA_ "GenSigSendType" SG_ 270 GE_Langfr_Schutzmom_02 0;
BA_ "GenSigStartValue" SG_ 270 GE_Langfr_Schutzmom_02 510;
BA_ "GenSigSwitchedByIgnition" SG_ 270 GE_Langfr_Schutzmom_02 0;
BA_ "Fehlerwert" SG_ 270 GE_Langfr_Schutzmom_02 511;
BA_ "GenSigSendType" SG_ 270 GE_MMom_Soll_02 0;
BA_ "GenSigStartValue" SG_ 270 GE_MMom_Soll_02 1022;
BA_ "GenSigSwitchedByIgnition" SG_ 270 GE_MMom_Soll_02 0;
BA_ "Fehlerwert" SG_ 270 GE_MMom_Soll_02 1023;
BA_ "GenSigSendType" SG_ 270 GE_MMom_Status 0;
BA_ "GenSigSwitchedByIgnition" SG_ 270 GE_MMom_Status 0;
BA_ "GenSigSendType" SG_ 270 GE_MMom_Status_02 0;
BA_ "GenSigSwitchedByIgnition" SG_ 270 GE_MMom_Status_02 0;
BA_ "GenSigSendType" SG_ 270 GE_MMom_Vorhalt_02 0;
BA_ "GenSigStartValue" SG_ 270 GE_MMom_Vorhalt_02 1022;
BA_ "GenSigSwitchedByIgnition" SG_ 270 GE_MMom_Vorhalt_02 0;
BA_ "Fehlerwert" SG_ 270 GE_MMom_Vorhalt_02 1023;
BA_ "GenSigSendType" SG_ 270 GE_Mom_Begr_Gradient 0;
BA_ "GenSigStartValue" SG_ 270 GE_Mom_Begr_Gradient 255;
BA_ "GenSigSwitchedByIgnition" SG_ 270 GE_Mom_Begr_Gradient 0;
BA_ "GenSigSendType" SG_ 270 GE_Notlauf 0;
BA_ "GenSigSwitchedByIgnition" SG_ 270 GE_Notlauf 0;
BA_ "GenSigSendType" SG_ 270 GE_Radmoment 0;
BA_ "GenSigStartValue" SG_ 270 GE_Radmoment 65534;
BA_ "GenSigSwitchedByIgnition" SG_ 270 GE_Radmoment 0;
BA_ "Fehlerwert" SG_ 270 GE_Radmoment 65535;
BA_ "GenSigSendType" SG_ 270 GE_Schaltablauf 0;
BA_ "GenSigSwitchedByIgnition" SG_ 270 GE_Schaltablauf 0;
BA_ "GenSigSendType" SG_ 270 GE_Schubabschalt_Unt 0;
BA_ "GenSigSwitchedByIgnition" SG_ 270 GE_Schubabschalt_Unt 0;
BA_ "GenSigSendType" SG_ 270 GE_StartStopp_Info 0;
BA_ "GenSigSwitchedByIgnition" SG_ 270 GE_StartStopp_Info 0;
BA_ "GenSigSendType" SG_ 270 GE_Status_Kraftschluss 0;
BA_ "GenSigSwitchedByIgnition" SG_ 270 GE_Status_Kraftschluss 0;
BA_ "GenSigSendType" SG_ 270 GE_Synchro_Status_02 0;
BA_ "GenSigSwitchedByIgnition" SG_ 270 GE_Synchro_Status_02 0;
BA_ "GenSigSendType" SG_ 270 GE_Synchro_Wunschdrehz 0;
BA_ "GenSigSwitchedByIgnition" SG_ 270 GE_Synchro_Wunschdrehz 0;
BA_ "Fehlerwert" SG_ 270 GE_Synchro_Wunschdrehz 511;
BA_ "GenSigSendType" SG_ 270 GE_Synchro_Zeit 0;
BA_ "GenSigSwitchedByIgnition" SG_ 270 GE_Synchro_Zeit 0;
BA_ "Fehlerwert" SG_ 270 GE_Synchro_Zeit 255;
BA_ "GenSigSendType" SG_ 270 GE_Uefkt 0;
BA_ "GenSigSwitchedByIgnition" SG_ 270 GE_Uefkt 0;
BA_ "Fehlerwert" SG_ 270 GE_Uefkt 1023;
BA_ "GenSigSendType" SG_ 270 GE_Uefkt_unplausibel 0;
BA_ "GenSigSwitchedByIgnition" SG_ 270 GE_Uefkt_unplausibel 0;
BA_ "GenSigSendType" SG_ 270 GE_Verbot_Ausblendung 0;
BA_ "GenSigSwitchedByIgnition" SG_ 270 GE_Verbot_Ausblendung 0;
BA_ "GenSigSendType" SG_ 270 GE_Verlustmoment 0;
BA_ "GenSigSwitchedByIgnition" SG_ 270 GE_Verlustmoment 0;
BA_ "Fehlerwert" SG_ 270 GE_Verlustmoment 255;
BA_ "GenSigSendType" SG_ 270 GE_Zielgang 0;
BA_ "GenSigSwitchedByIgnition" SG_ 270 GE_Zielgang 0;
BA_ "Fehlerwert" SG_ 270 GE_Zielgang 15;
BA_ "GenSigSendType" SG_ 270 Getriebe_50_BZ 0;
BA_ "GenSigFuncType" SG_ 270 Getriebe_50_BZ 1;
BA_ "GenSigSwitchedByIgnition" SG_ 270 Getriebe_50_BZ 0;
BA_ "GenSigSendType" SG_ 270 Getriebe_50_CRC 0;
BA_ "GenSigFuncType" SG_ 270 Getriebe_50_CRC 2;
BA_ "GenSigSwitchedByIgnition" SG_ 270 Getriebe_50_CRC 0;
BA_ "GenSigSendType" SG_ 509 Freilauf_Charisma_FahrPr 0;
BA_ "GenSigSwitchedByIgnition" SG_ 509 Freilauf_Charisma_FahrPr 0;
BA_ "GenSigSendType" SG_ 509 Freilauf_Charisma_Status 0;
BA_ "GenSigSwitchedByIgnition" SG_ 509 Freilauf_Charisma_Status 0;
BA_ "GenSigSendType" SG_ 509 FSA_Fehlerstatus_Parksperre 0;
BA_ "GenSigSwitchedByIgnition" SG_ 509 FSA_Fehlerstatus_Parksperre 0;
BA_ "GenSigSendType" SG_ 509 GE_amax_moeglich 0;
BA_ "GenSigStartValue" SG_ 509 GE_amax_moeglich 84;
BA_ "GenSigSwitchedByIgnition" SG_ 509 GE_amax_moeglich 0;
BA_ "GenSigSendType" SG_ 509 GE_Anforderung_HMS 4;
BA_ "GenSigSendType" SG_ 509 GE_Anschleppstart_Freigabe 4;
BA_ "GenSigSwitchedByIgnition" SG_ 509 GE_Anschleppstart_Freigabe 0;
BA_ "GenSigSendType" SG_ 509 GE_Betaetigung_Hold 3;
BA_ "GenSigSwitchedByIgnition" SG_ 509 GE_Betaetigung_Hold 0;
BA_ "GenSigSendType" SG_ 509 GE_Charisma_FahrPr 0;
BA_ "GenSigSwitchedByIgnition" SG_ 509 GE_Charisma_FahrPr 0;
BA_ "GenSigSendType" SG_ 509 GE_Charisma_Status 0;
BA_ "GenSigSwitchedByIgnition" SG_ 509 GE_Charisma_Status 0;
BA_ "GenSigSendType" SG_ 509 GE_Codierung_MSG 0;
BA_ "GenSigSwitchedByIgnition" SG_ 509 GE_Codierung_MSG 0;
BA_ "GenSigSendType" SG_ 509 GE_Fahrprogramm 4;
BA_ "GenSigSwitchedByIgnition" SG_ 509 GE_Fahrprogramm 0;
BA_ "GenSigSendType" SG_ 509 GE_Freigabe_Info_WFS 3;
BA_ "GenSigSwitchedByIgnition" SG_ 509 GE_Freigabe_Info_WFS 0;
BA_ "GenSigSendType" SG_ 509 GE_Freigabe_Verfallsinfo_WFS 3;
BA_ "GenSigSwitchedByIgnition" SG_ 509 GE_Freigabe_Verfallsinfo_WFS 0;
BA_ "GenSigSendType" SG_ 509 GE_Freilauf_Status 4;
BA_ "GenSigSwitchedByIgnition" SG_ 509 GE_Freilauf_Status 0;
BA_ "Fehlerwert" SG_ 509 GE_Freilauf_Status 7;
BA_ "GenSigSendType" SG_ 509 GE_Grundeinstell_Drehrichtung_EM 4;
BA_ "GenSigSwitchedByIgnition" SG_ 509 GE_Grundeinstell_Drehrichtung_EM 0;
BA_ "GenSigSendType" SG_ 509 GE_Grundeinstellung 4;
BA_ "GenSigSwitchedByIgnition" SG_ 509 GE_Grundeinstellung 0;
BA_ "GenSigSendType" SG_ 509 GE_Heizwunsch 0;
BA_ "GenSigStartValue" SG_ 509 GE_Heizwunsch 1;
BA_ "GenSigSwitchedByIgnition" SG_ 509 GE_Heizwunsch 0;
BA_ "GenSigSendType" SG_ 509 GE_LaunchControl 0;
BA_ "GenSigSwitchedByIgnition" SG_ 509 GE_LaunchControl 0;
BA_ "GenSigSendType" SG_ 509 GE_LFR_Adaption 0;
BA_ "GenSigSwitchedByIgnition" SG_ 509 GE_LFR_Adaption 0;
BA_ "GenSigSendType" SG_ 509 GE_OBD_AbsperrVent 0;
BA_ "GenSigSwitchedByIgnition" SG_ 509 GE_OBD_AbsperrVent 0;
BA_ "GenSigSendType" SG_ 509 GE_OBD_Status 0;
BA_ "GenSigSwitchedByIgnition" SG_ 509 GE_OBD_Status 0;
BA_ "GenSigSendType" SG_ 509 GE_Parken_beibehalten_HMS 0;
BA_ "GenSigStartValue" SG_ 509 GE_Parken_beibehalten_HMS 2;
BA_ "GenSigSwitchedByIgnition" SG_ 509 GE_Parken_beibehalten_HMS 0;
BA_ "Fehlerwert" SG_ 509 GE_Parken_beibehalten_HMS 3;
BA_ "GenSigSendType" SG_ 509 GE_Parken_WFS_Status 3;
BA_ "GenSigSwitchedByIgnition" SG_ 509 GE_Parken_WFS_Status 0;
BA_ "GenSigSendType" SG_ 509 GE_QBit_Sumpftemperatur 0;
BA_ "GenSigStartValue" SG_ 509 GE_QBit_Sumpftemperatur 1;
BA_ "GenSigSwitchedByIgnition" SG_ 509 GE_QBit_Sumpftemperatur 0;
BA_ "GenSigSendType" SG_ 509 GE_Schleuderoeltemperatur 0;
BA_ "GenSigStartValue" SG_ 509 GE_Schleuderoeltemperatur 254;
BA_ "GenSigSwitchedByIgnition" SG_ 509 GE_Schleuderoeltemperatur 0;
BA_ "Fehlerwert" SG_ 509 GE_Schleuderoeltemperatur 255;
BA_ "GenSigSendType" SG_ 509 GE_SpannungsAnf 0;
BA_ "GenSigSwitchedByIgnition" SG_ 509 GE_SpannungsAnf 0;
BA_ "GenSigSendType" SG_ 509 GE_Sperr_Info_WFS 3;
BA_ "GenSigSwitchedByIgnition" SG_ 509 GE_Sperr_Info_WFS 0;
BA_ "GenSigSendType" SG_ 509 GE_Strombedarf_erh 3;
BA_ "GenSigSwitchedByIgnition" SG_ 509 GE_Strombedarf_erh 0;
BA_ "GenSigSendType" SG_ 509 GE_Sumpftemperatur 0;
BA_ "GenSigSwitchedByIgnition" SG_ 509 GE_Sumpftemperatur 0;
BA_ "Fehlerwert" SG_ 509 GE_Sumpftemperatur 255;
BA_ "GenSigSendType" SG_ 509 GE_TippZustand 4;
BA_ "GenSigSwitchedByIgnition" SG_ 509 GE_TippZustand 0;
BA_ "GenSigSendType" SG_ 509 GE_Veto_Rollfaehigkeit 0;
BA_ "GenSigSwitchedByIgnition" SG_ 509 GE_Veto_Rollfaehigkeit 0;
BA_ "GenSigSendType" SG_ 509 GE_Weckleitung_aktiv 0;
BA_ "GenSigSwitchedByIgnition" SG_ 509 GE_Weckleitung_aktiv 0;
BA_ "GenSigSendType" SG_ 509 GE_Zustand_Kuppltemp 0;
BA_ "GenSigSwitchedByIgnition" SG_ 509 GE_Zustand_Kuppltemp 0;
BA_ "GenSigSendType" SG_ 509 Getriebe_51_BZ 0;
BA_ "GenSigFuncType" SG_ 509 Getriebe_51_BZ 1;
BA_ "GenSigSwitchedByIgnition" SG_ 509 Getriebe_51_BZ 0;
BA_ "GenSigSendType" SG_ 509 Getriebe_51_CRC 0;
BA_ "GenSigFuncType" SG_ 509 Getriebe_51_CRC 2;
BA_ "GenSigSwitchedByIgnition" SG_ 509 Getriebe_51_CRC 0;
BA_ "GenSigSendType" SG_ 891 GNSS_Empfaenger_Status 0;
BA_ "GenSigSwitchedByIgnition" SG_ 891 GNSS_Empfaenger_Status 0;
BA_ "GenSigSendType" SG_ 891 GNSS_Empfangbare_Satelliten 0;
BA_ "GenSigSwitchedByIgnition" SG_ 891 GNSS_Empfangbare_Satelliten 0;
BA_ "GenSigSendType" SG_ 891 GNSS_Genutzte_Satelliten 0;
BA_ "GenSigSwitchedByIgnition" SG_ 891 GNSS_Genutzte_Satelliten 0;
BA_ "GenSigSendType" SG_ 891 GNSS_GLONASS_in_Nutzung 0;
BA_ "GenSigSwitchedByIgnition" SG_ 891 GNSS_GLONASS_in_Nutzung 0;
BA_ "GenSigSendType" SG_ 891 GNSS_GPS_in_Nutzung 0;
BA_ "GenSigSwitchedByIgnition" SG_ 891 GNSS_GPS_in_Nutzung 0;
BA_ "GenSigSendType" SG_ 891 GNSS_Nachrichtenpaket_ID5 0;
BA_ "GenSigSwitchedByIgnition" SG_ 891 GNSS_Nachrichtenpaket_ID5 0;
BA_ "GenSigSendType" SG_ 891 GNSS_Sichtbare_Satelliten 0;
BA_ "GenSigSwitchedByIgnition" SG_ 891 GNSS_Sichtbare_Satelliten 0;
BA_ "GenSigSendType" SG_ 891 GNSS_UTC_Zeit 0;
BA_ "GenSigSwitchedByIgnition" SG_ 891 GNSS_UTC_Zeit 0;
BA_ "GenSigSendType" SG_ 771 HCA_03_Sendestatus 6;
BA_ "GenSigSendType" SG_ 771 HCA_QFK_AnfStat 0;
BA_ "GenSigStartValue" SG_ 771 HCA_QFK_AnfStat 1;
BA_ "GenSigSendType" SG_ 771 HCA_QFK_Art1 0;
BA_ "GenSigSendType" SG_ 771 HCA_QFK_Art2 0;
BA_ "GenSigSendType" SG_ 771 HCA_QFK_KrSoll 0;
BA_ "GenSigSendType" SG_ 771 HCA_QFK_KrSoll_VZ 0;
BA_ "GenSigSendType" SG_ 771 HCA_QFK_KruemmSoll 0;
BA_ "GenSigSendType" SG_ 771 HCA_QFK_KruemmSoll_VZ 0;
BA_ "GenSigSendType" SG_ 771 HCA_QFK_Signal1 0;
BA_ "GenSigSendType" SG_ 771 HCA_QFK_Signal2 0;
BA_ "GenSigSendType" SG_ 771 HCA_QFK_Spuerb 0;
BA_ "GenSigSendType" SG_ 771 SOK_HCA_03_Signatur 0;
BA_ "GenSigFuncType" SG_ 771 SOK_HCA_03_Signatur 15;
BA_ "GenSigSendType" SG_ 626 HVLM_Aktive_Ladeart 3;
BA_ "GenSigSwitchedByIgnition" SG_ 626 HVLM_Aktive_Ladeart 0;
BA_ "Fehlerwert" SG_ 626 HVLM_Aktive_Ladeart 7;
BA_ "GenSigSendType" SG_ 626 HVLM_Anforderung_HMS 0;
BA_ "GenSigSwitchedByIgnition" SG_ 626 HVLM_Anforderung_HMS 0;
BA_ "GenSigSendType" SG_ 626 HVLM_AWC_VerbautStatus 0;
BA_ "GenSigSwitchedByIgnition" SG_ 626 HVLM_AWC_VerbautStatus 0;
BA_ "Fehlerwert" SG_ 626 HVLM_AWC_VerbautStatus 3;
BA_ "GenSigSendType" SG_ 626 HVLM_DC_Aufstartmodus 0;
BA_ "GenSigSwitchedByIgnition" SG_ 626 HVLM_DC_Aufstartmodus 0;
BA_ "GenSigSendType" SG_ 626 HVLM_Intensitaet_Lk1 3;
BA_ "GenSigStartValue" SG_ 626 HVLM_Intensitaet_Lk1 126;
BA_ "GenSigSwitchedByIgnition" SG_ 626 HVLM_Intensitaet_Lk1 0;
BA_ "Fehlerwert" SG_ 626 HVLM_Intensitaet_Lk1 127;
BA_ "GenSigSendType" SG_ 626 HVLM_Intensitaet_Lk2 3;
BA_ "GenSigStartValue" SG_ 626 HVLM_Intensitaet_Lk2 126;
BA_ "GenSigSwitchedByIgnition" SG_ 626 HVLM_Intensitaet_Lk2 0;
BA_ "Fehlerwert" SG_ 626 HVLM_Intensitaet_Lk2 127;
BA_ "GenSigSendType" SG_ 626 HVLM_Laden_ISO_Messung_Anf 0;
BA_ "GenSigStartValue" SG_ 626 HVLM_Laden_ISO_Messung_Anf 1;
BA_ "GenSigSwitchedByIgnition" SG_ 626 HVLM_Laden_ISO_Messung_Anf 0;
BA_ "GenSigSendType" SG_ 626 HVLM_Ladeszenario 3;
BA_ "GenSigStartValue" SG_ 626 HVLM_Ladeszenario 30;
BA_ "GenSigSwitchedByIgnition" SG_ 626 HVLM_Ladeszenario 0;
BA_ "Fehlerwert" SG_ 626 HVLM_Ladeszenario 31;
BA_ "GenSigSendType" SG_ 626 HVLM_Ladevorgang_Anf 0;
BA_ "GenSigSwitchedByIgnition" SG_ 626 HVLM_Ladevorgang_Anf 0;
BA_ "GenSigSendType" SG_ 626 HVLM_Parken_beibehalten_HMS 0;
BA_ "GenSigStartValue" SG_ 626 HVLM_Parken_beibehalten_HMS 2;
BA_ "GenSigSwitchedByIgnition" SG_ 626 HVLM_Parken_beibehalten_HMS 0;
BA_ "Fehlerwert" SG_ 626 HVLM_Parken_beibehalten_HMS 3;
BA_ "GenSigSendType" SG_ 626 HVLM_Pulsierstufe 3;
BA_ "GenSigSwitchedByIgnition" SG_ 626 HVLM_Pulsierstufe 0;
BA_ "GenSigSendType" SG_ 626 HVLM_Start_Pulserkennung 0;
BA_ "GenSigSwitchedByIgnition" SG_ 626 HVLM_Start_Pulserkennung 0;
BA_ "GenSigSendType" SG_ 626 HVLM_Steckerstatus_A 3;
BA_ "GenSigSwitchedByIgnition" SG_ 626 HVLM_Steckerstatus_A 0;
BA_ "Fehlerwert" SG_ 626 HVLM_Steckerstatus_A 7;
BA_ "GenSigSendType" SG_ 626 HVLM_Steckerstatus_B 3;
BA_ "GenSigSwitchedByIgnition" SG_ 626 HVLM_Steckerstatus_B 0;
BA_ "Fehlerwert" SG_ 626 HVLM_Steckerstatus_B 7;
BA_ "GenSigSendType" SG_ 626 HVLM_WakeUpZaehlerResetAnf 0;
BA_ "GenSigSwitchedByIgnition" SG_ 626 HVLM_WakeUpZaehlerResetAnf 0;
BA_ "GenSigSendType" SG_ 626 HVLM_ZustandLadeablauf 0;
BA_ "GenSigSwitchedByIgnition" SG_ 626 HVLM_ZustandLadeablauf 0;
BA_ "Fehlerwert" SG_ 626 HVLM_ZustandLadeablauf 3;
BA_ "GenSigSendType" SG_ 2589283966 IMU_StObd_StChk1 0;
BA_ "GenSigStartValue" SG_ 2589283966 IMU_StObd_StChk1 1;
BA_ "GenSigSwitchedByIgnition" SG_ 2589283966 IMU_StObd_StChk1 0;
BA_ "GenSigSendType" SG_ 2589283966 IMU_StObd_StChk10 0;
BA_ "GenSigStartValue" SG_ 2589283966 IMU_StObd_StChk10 1;
BA_ "GenSigSwitchedByIgnition" SG_ 2589283966 IMU_StObd_StChk10 0;
BA_ "GenSigSendType" SG_ 2589283966 IMU_StObd_StChk11 0;
BA_ "GenSigStartValue" SG_ 2589283966 IMU_StObd_StChk11 1;
BA_ "GenSigSwitchedByIgnition" SG_ 2589283966 IMU_StObd_StChk11 0;
BA_ "GenSigSendType" SG_ 2589283966 IMU_StObd_StChk2 0;
BA_ "GenSigStartValue" SG_ 2589283966 IMU_StObd_StChk2 1;
BA_ "GenSigSwitchedByIgnition" SG_ 2589283966 IMU_StObd_StChk2 0;
BA_ "GenSigSendType" SG_ 2589283966 IMU_StObd_StChk3 0;
BA_ "GenSigStartValue" SG_ 2589283966 IMU_StObd_StChk3 1;
BA_ "GenSigSwitchedByIgnition" SG_ 2589283966 IMU_StObd_StChk3 0;
BA_ "GenSigSendType" SG_ 2589283966 IMU_StObd_StChk4 0;
BA_ "GenSigStartValue" SG_ 2589283966 IMU_StObd_StChk4 1;
BA_ "GenSigSwitchedByIgnition" SG_ 2589283966 IMU_StObd_StChk4 0;
BA_ "GenSigSendType" SG_ 2589283966 IMU_StObd_StChk5 0;
BA_ "GenSigStartValue" SG_ 2589283966 IMU_StObd_StChk5 1;
BA_ "GenSigSwitchedByIgnition" SG_ 2589283966 IMU_StObd_StChk5 0;
BA_ "GenSigSendType" SG_ 2589283966 IMU_StObd_StChk6 0;
BA_ "GenSigStartValue" SG_ 2589283966 IMU_StObd_StChk6 1;
BA_ "GenSigSwitchedByIgnition" SG_ 2589283966 IMU_StObd_StChk6 0;
BA_ "GenSigSendType" SG_ 2589283966 IMU_StObd_StChk7 0;
BA_ "GenSigStartValue" SG_ 2589283966 IMU_StObd_StChk7 1;
BA_ "GenSigSwitchedByIgnition" SG_ 2589283966 IMU_StObd_StChk7 0;
BA_ "GenSigSendType" SG_ 2589283966 IMU_StObd_StChk8 0;
BA_ "GenSigStartValue" SG_ 2589283966 IMU_StObd_StChk8 1;
BA_ "GenSigSwitchedByIgnition" SG_ 2589283966 IMU_StObd_StChk8 0;
BA_ "GenSigSendType" SG_ 2589283966 IMU_StObd_StChk9 0;
BA_ "GenSigStartValue" SG_ 2589283966 IMU_StObd_StChk9 1;
BA_ "GenSigSwitchedByIgnition" SG_ 2589283966 IMU_StObd_StChk9 0;
BA_ "GenSigSendType" SG_ 2589283966 IMU_StObd_StFail1 0;
BA_ "GenSigSwitchedByIgnition" SG_ 2589283966 IMU_StObd_StFail1 0;
BA_ "GenSigSendType" SG_ 2589283966 IMU_StObd_StFail10 0;
BA_ "GenSigSwitchedByIgnition" SG_ 2589283966 IMU_StObd_StFail10 0;
BA_ "GenSigSendType" SG_ 2589283966 IMU_StObd_StFail11 0;
BA_ "GenSigSwitchedByIgnition" SG_ 2589283966 IMU_StObd_StFail11 0;
BA_ "GenSigSendType" SG_ 2589283966 IMU_StObd_StFail2 0;
BA_ "GenSigSwitchedByIgnition" SG_ 2589283966 IMU_StObd_StFail2 0;
BA_ "GenSigSendType" SG_ 2589283966 IMU_StObd_StFail3 0;
BA_ "GenSigSwitchedByIgnition" SG_ 2589283966 IMU_StObd_StFail3 0;
BA_ "GenSigSendType" SG_ 2589283966 IMU_StObd_StFail4 0;
BA_ "GenSigSwitchedByIgnition" SG_ 2589283966 IMU_StObd_StFail4 0;
BA_ "GenSigSendType" SG_ 2589283966 IMU_StObd_StFail5 0;
BA_ "GenSigSwitchedByIgnition" SG_ 2589283966 IMU_StObd_StFail5 0;
BA_ "GenSigSendType" SG_ 2589283966 IMU_StObd_StFail6 0;
BA_ "GenSigSwitchedByIgnition" SG_ 2589283966 IMU_StObd_StFail6 0;
BA_ "GenSigSendType" SG_ 2589283966 IMU_StObd_StFail7 0;
BA_ "GenSigSwitchedByIgnition" SG_ 2589283966 IMU_StObd_StFail7 0;
BA_ "GenSigSendType" SG_ 2589283966 IMU_StObd_StFail8 0;
BA_ "GenSigSwitchedByIgnition" SG_ 2589283966 IMU_StObd_StFail8 0;
BA_ "GenSigSendType" SG_ 2589283966 IMU_StObd_StFail9 0;
BA_ "GenSigSwitchedByIgnition" SG_ 2589283966 IMU_StObd_StFail9 0;
BA_ "GenSigSendType" SG_ 182 IMU_05_BZ 0;
BA_ "GenSigFuncType" SG_ 182 IMU_05_BZ 1;
BA_ "GenSigSwitchedByIgnition" SG_ 182 IMU_05_BZ 0;
BA_ "GenSigSendType" SG_ 182 IMU_05_CRC 0;
BA_ "GenSigFuncType" SG_ 182 IMU_05_CRC 2;
BA_ "GenSigSwitchedByIgnition" SG_ 182 IMU_05_CRC 0;
BA_ "GenSigSendType" SG_ 182 IMU_ALat 0;
BA_ "GenSigStartValue" SG_ 182 IMU_ALat 65534;
BA_ "GenSigSwitchedByIgnition" SG_ 182 IMU_ALat 0;
BA_ "Fehlerwert" SG_ 182 IMU_ALat 65535;
BA_ "GenSigSendType" SG_ 182 IMU_ALat_Qlfr 0;
BA_ "GenSigStartValue" SG_ 182 IMU_ALat_Qlfr 14;
BA_ "GenSigSwitchedByIgnition" SG_ 182 IMU_ALat_Qlfr 0;
BA_ "Fehlerwert" SG_ 182 IMU_ALat_Qlfr 15;
BA_ "GenSigSendType" SG_ 182 IMU_ALgt 0;
BA_ "GenSigStartValue" SG_ 182 IMU_ALgt 65534;
BA_ "GenSigSwitchedByIgnition" SG_ 182 IMU_ALgt 0;
BA_ "Fehlerwert" SG_ 182 IMU_ALgt 65535;
BA_ "GenSigSendType" SG_ 182 IMU_ALgt_Qlfr 0;
BA_ "GenSigStartValue" SG_ 182 IMU_ALgt_Qlfr 14;
BA_ "GenSigSwitchedByIgnition" SG_ 182 IMU_ALgt_Qlfr 0;
BA_ "Fehlerwert" SG_ 182 IMU_ALgt_Qlfr 15;
BA_ "GenSigSendType" SG_ 182 IMU_AVert 0;
BA_ "GenSigStartValue" SG_ 182 IMU_AVert 65534;
BA_ "GenSigSwitchedByIgnition" SG_ 182 IMU_AVert 0;
BA_ "Fehlerwert" SG_ 182 IMU_AVert 65535;
BA_ "GenSigSendType" SG_ 182 IMU_AVert_Qlfr 0;
BA_ "GenSigStartValue" SG_ 182 IMU_AVert_Qlfr 14;
BA_ "GenSigSwitchedByIgnition" SG_ 182 IMU_AVert_Qlfr 0;
BA_ "Fehlerwert" SG_ 182 IMU_AVert_Qlfr 15;
BA_ "GenSigSendType" SG_ 182 IMU_MeasurementTimeHigh 0;
BA_ "GenSigSwitchedByIgnition" SG_ 182 IMU_MeasurementTimeHigh 0;
BA_ "GenSigSendType" SG_ 182 IMU_MeasurementTimeLow 0;
BA_ "GenSigStartValue" SG_ 182 IMU_MeasurementTimeLow 1023;
BA_ "GenSigSwitchedByIgnition" SG_ 182 IMU_MeasurementTimeLow 0;
BA_ "GenSigSendType" SG_ 182 IMU_PitchRate 0;
BA_ "GenSigStartValue" SG_ 182 IMU_PitchRate 65534;
BA_ "GenSigSwitchedByIgnition" SG_ 182 IMU_PitchRate 0;
BA_ "Fehlerwert" SG_ 182 IMU_PitchRate 65535;
BA_ "GenSigSendType" SG_ 182 IMU_PitchRate_Qlfr 0;
BA_ "GenSigStartValue" SG_ 182 IMU_PitchRate_Qlfr 14;
BA_ "GenSigSwitchedByIgnition" SG_ 182 IMU_PitchRate_Qlfr 0;
BA_ "Fehlerwert" SG_ 182 IMU_PitchRate_Qlfr 15;
BA_ "GenSigSendType" SG_ 182 IMU_RollRate 0;
BA_ "GenSigStartValue" SG_ 182 IMU_RollRate 65534;
BA_ "GenSigSwitchedByIgnition" SG_ 182 IMU_RollRate 0;
BA_ "Fehlerwert" SG_ 182 IMU_RollRate 65535;
BA_ "GenSigSendType" SG_ 182 IMU_RollRate_Qlfr 0;
BA_ "GenSigStartValue" SG_ 182 IMU_RollRate_Qlfr 14;
BA_ "GenSigSwitchedByIgnition" SG_ 182 IMU_RollRate_Qlfr 0;
BA_ "Fehlerwert" SG_ 182 IMU_RollRate_Qlfr 15;
BA_ "GenSigSendType" SG_ 182 IMU_YawRate 0;
BA_ "GenSigStartValue" SG_ 182 IMU_YawRate 65534;
BA_ "GenSigSwitchedByIgnition" SG_ 182 IMU_YawRate 0;
BA_ "Fehlerwert" SG_ 182 IMU_YawRate 65535;
BA_ "GenSigSendType" SG_ 182 IMU_YawRate_Qlfr 0;
BA_ "GenSigStartValue" SG_ 182 IMU_YawRate_Qlfr 14;
BA_ "GenSigSwitchedByIgnition" SG_ 182 IMU_YawRate_Qlfr 0;
BA_ "Fehlerwert" SG_ 182 IMU_YawRate_Qlfr 15;
BA_ "GenSigSendType" SG_ 182 SOK_IMU_05_Signatur 0;
BA_ "GenSigFuncType" SG_ 182 SOK_IMU_05_Signatur 15;
BA_ "GenSigSwitchedByIgnition" SG_ 182 SOK_IMU_05_Signatur 0;
BA_ "GenSigSendType" SG_ 312 IPA_01_BZ 0;
BA_ "GenSigFuncType" SG_ 312 IPA_01_BZ 1;
BA_ "GenSigSwitchedByIgnition" SG_ 312 IPA_01_BZ 0;
BA_ "GenSigSendType" SG_ 312 IPA_01_CRC 0;
BA_ "GenSigFuncType" SG_ 312 IPA_01_CRC 2;
BA_ "GenSigSwitchedByIgnition" SG_ 312 IPA_01_CRC 0;
BA_ "GenSigSendType" SG_ 312 IPA_Fahrstufenwunsch 0;
BA_ "GenSigSwitchedByIgnition" SG_ 312 IPA_Fahrstufenwunsch 0;
BA_ "GenSigSendType" SG_ 312 IPA_Status 0;
BA_ "GenSigSwitchedByIgnition" SG_ 312 IPA_Status 0;
BA_ "GenSigSendType" SG_ 2527679583 IPA_02_BZ 0;
BA_ "GenSigFuncType" SG_ 2527679583 IPA_02_BZ 1;
BA_ "GenSigSwitchedByIgnition" SG_ 2527679583 IPA_02_BZ 0;
BA_ "GenSigSendType" SG_ 2527679583 IPA_02_CRC 0;
BA_ "GenSigFuncType" SG_ 2527679583 IPA_02_CRC 2;
BA_ "GenSigSwitchedByIgnition" SG_ 2527679583 IPA_02_CRC 0;
BA_ "GenSigActiveRepetitions" SG_ 2527679583 IPA_Akustik_PL_gefunden 5;
BA_ "GenSigSendType" SG_ 2527679583 IPA_Akustik_PL_gefunden 4;
BA_ "GenSigActiveRepetitions" SG_ 2527679583 IPA_Anf_Meldungen 5;
BA_ "GenSigSendType" SG_ 2527679583 IPA_Anf_Meldungen 4;
BA_ "GenSigSwitchedByIgnition" SG_ 2527679583 IPA_Anf_Meldungen 0;
BA_ "GenSigActiveRepetitions" SG_ 2527679583 IPA_PL_Anzeige_links 5;
BA_ "GenSigSendType" SG_ 2527679583 IPA_PL_Anzeige_links 4;
BA_ "GenSigActiveRepetitions" SG_ 2527679583 IPA_PL_Anzeige_rechts 5;
BA_ "GenSigSendType" SG_ 2527679583 IPA_PL_Anzeige_rechts 4;
BA_ "GenSigActiveRepetitions" SG_ 2527679583 Parken_aktives_System_02 5;
BA_ "GenSigSendType" SG_ 2527679583 Parken_aktives_System_02 4;
BA_ "GenSigSwitchedByIgnition" SG_ 2527679583 Parken_aktives_System_02 0;
BA_ "GenSigActiveRepetitions" SG_ 2527679583 Parken_Aktivierungslicht_Anf 5;
BA_ "GenSigSendType" SG_ 2527679583 Parken_Aktivierungslicht_Anf 4;
BA_ "GenSigSwitchedByIgnition" SG_ 2527679583 Parken_Aktivierungslicht_Anf 0;
BA_ "GenSigActiveRepetitions" SG_ 2527679583 Parken_Bestaetigungsblinken_Anf 5;
BA_ "GenSigSendType" SG_ 2527679583 Parken_Bestaetigungsblinken_Anf 4;
BA_ "GenSigSwitchedByIgnition" SG_ 2527679583 Parken_Bestaetigungsblinken_Anf 0;
BA_ "GenSigActiveRepetitions" SG_ 2527679583 Parken_Blinker_li_Anf 5;
BA_ "GenSigSendType" SG_ 2527679583 Parken_Blinker_li_Anf 4;
BA_ "GenSigSwitchedByIgnition" SG_ 2527679583 Parken_Blinker_li_Anf 0;
BA_ "GenSigActiveRepetitions" SG_ 2527679583 Parken_Blinker_re_Anf 5;
BA_ "GenSigSendType" SG_ 2527679583 Parken_Blinker_re_Anf 4;
BA_ "GenSigSwitchedByIgnition" SG_ 2527679583 Parken_Blinker_re_Anf 0;
BA_ "GenSigActiveRepetitions" SG_ 2527679583 Parken_Fahrbereitschaftlicht_Anf 5;
BA_ "GenSigSendType" SG_ 2527679583 Parken_Fahrbereitschaftlicht_Anf 4;
BA_ "GenSigActiveRepetitions" SG_ 2527679583 Parken_Fahrerhinweise_Anf 5;
BA_ "GenSigSendType" SG_ 2527679583 Parken_Fahrerhinweise_Anf 4;
BA_ "GenSigSwitchedByIgnition" SG_ 2527679583 Parken_Fahrerhinweise_Anf 0;
BA_ "GenSigActiveRepetitions" SG_ 2527679583 Parken_Fahrtrichtungslicht_Anf 5;
BA_ "GenSigSendType" SG_ 2527679583 Parken_Fahrtrichtungslicht_Anf 4;
BA_ "GenSigActiveRepetitions" SG_ 2527679583 Parken_FFB_LED_Anf 5;
BA_ "GenSigSendType" SG_ 2527679583 Parken_FFB_LED_Anf 4;
BA_ "GenSigActiveRepetitions" SG_ 2527679583 Parken_Lichtnachlauf_Anf 5;
BA_ "GenSigSendType" SG_ 2527679583 Parken_Lichtnachlauf_Anf 4;
BA_ "GenSigActiveRepetitions" SG_ 2527679583 Parken_Lichtsteuerung_Anf 5;
BA_ "GenSigSendType" SG_ 2527679583 Parken_Lichtsteuerung_Anf 4;
BA_ "GenSigSwitchedByIgnition" SG_ 2527679583 Parken_Lichtsteuerung_Anf 0;
BA_ "GenSigActiveRepetitions" SG_ 2527679583 Parken_Schluesselsuche_Anf 5;
BA_ "GenSigSendType" SG_ 2527679583 Parken_Schluesselsuche_Anf 4;
BA_ "GenSigActiveRepetitions" SG_ 2527679583 Parken_Seitenspiegel_Anf 5;
BA_ "GenSigSendType" SG_ 2527679583 Parken_Seitenspiegel_Anf 4;
BA_ "GenSigActiveRepetitions" SG_ 2527679583 Parken_Wegfahrsperren_Anf 5;
BA_ "GenSigSendType" SG_ 2527679583 Parken_Wegfahrsperren_Anf 4;
BA_ "GenSigActiveRepetitions" SG_ 2527679583 Parken_ZR_Sondermodus_Anf 5;
BA_ "GenSigSendType" SG_ 2527679583 Parken_ZR_Sondermodus_Anf 4;
BA_ "GenSigSwitchedByIgnition" SG_ 2527679583 Parken_ZR_Sondermodus_Anf 0;
BA_ "GenSigActiveRepetitions" SG_ 2527679583 Parken_ZV_Schliessen 5;
BA_ "GenSigSendType" SG_ 2527679583 Parken_ZV_Schliessen 4;
BA_ "GenSigSendType" SG_ 1811 ISO_ABS_Req_Data 3;
BA_ "GenSigFuncType" SG_ 1811 ISO_ABS_Req_Data 9;
BA_ "GenSigSwitchedByIgnition" SG_ 1811 ISO_ABS_Req_Data 0;
BA_ "GenSigSendType" SG_ 1917 ISO_ABS_Resp_Data 3;
BA_ "GenSigFuncType" SG_ 1917 ISO_ABS_Resp_Data 9;
BA_ "GenSigSwitchedByIgnition" SG_ 1917 ISO_ABS_Resp_Data 0;
BA_ "GenSigSendType" SG_ 1813 ISO_Airbag_01_Req_Data 3;
BA_ "GenSigFuncType" SG_ 1813 ISO_Airbag_01_Req_Data 9;
BA_ "GenSigSwitchedByIgnition" SG_ 1813 ISO_Airbag_01_Req_Data 0;
BA_ "GenSigSendType" SG_ 1919 ISO_Airbag_01_Resp_Data 3;
BA_ "GenSigFuncType" SG_ 1919 ISO_Airbag_01_Resp_Data 9;
BA_ "GenSigSwitchedByIgnition" SG_ 1919 ISO_Airbag_01_Resp_Data 0;
BA_ "GenSigSendType" SG_ 1807 ISO_Allrad_Req_Data 3;
BA_ "GenSigFuncType" SG_ 1807 ISO_Allrad_Req_Data 9;
BA_ "GenSigSendType" SG_ 1913 ISO_Allrad_Resp_Data 3;
BA_ "GenSigFuncType" SG_ 1913 ISO_Allrad_Resp_Data 9;
BA_ "GenSigSendType" SG_ 1906 ISO_Daempfer_Req_Data 3;
BA_ "GenSigFuncType" SG_ 1906 ISO_Daempfer_Req_Data 9;
BA_ "GenSigSwitchedByIgnition" SG_ 1906 ISO_Daempfer_Req_Data 0;
BA_ "GenSigSendType" SG_ 2012 ISO_Daempfer_Resp_Data 3;
BA_ "GenSigFuncType" SG_ 2012 ISO_Daempfer_Resp_Data 9;
BA_ "GenSigSwitchedByIgnition" SG_ 2012 ISO_Daempfer_Resp_Data 0;
BA_ "GenSigSendType" SG_ 1851 ISO_EBKV_Req_Data 3;
BA_ "GenSigFuncType" SG_ 1851 ISO_EBKV_Req_Data 9;
BA_ "GenSigSwitchedByIgnition" SG_ 1851 ISO_EBKV_Req_Data 0;
BA_ "GenSigSendType" SG_ 1957 ISO_EBKV_Resp_Data 3;
BA_ "GenSigFuncType" SG_ 1957 ISO_EBKV_Resp_Data 9;
BA_ "GenSigSwitchedByIgnition" SG_ 1957 ISO_EBKV_Resp_Data 0;
BA_ "GenSigSendType" SG_ 1792 ISO_ALL_01_Req_Data 3;
BA_ "GenSigFuncType" SG_ 1792 ISO_ALL_01_Req_Data 9;
BA_ "GenSigSwitchedByIgnition" SG_ 1792 ISO_ALL_01_Req_Data 0;
BA_ "GenSigSendType" SG_ 1810 ISO_Lenkhilfe_Req_Data 3;
BA_ "GenSigFuncType" SG_ 1810 ISO_Lenkhilfe_Req_Data 9;
BA_ "GenSigSwitchedByIgnition" SG_ 1810 ISO_Lenkhilfe_Req_Data 0;
BA_ "GenSigSendType" SG_ 1916 ISO_Lenkhilfe_Resp_Data 3;
BA_ "GenSigFuncType" SG_ 1916 ISO_Lenkhilfe_Resp_Data 9;
BA_ "GenSigSwitchedByIgnition" SG_ 1916 ISO_Lenkhilfe_Resp_Data 0;
BA_ "GenSigSendType" SG_ 1822 ISO_Quersperre_Req_Data 3;
BA_ "GenSigFuncType" SG_ 1822 ISO_Quersperre_Req_Data 9;
BA_ "GenSigSwitchedByIgnition" SG_ 1822 ISO_Quersperre_Req_Data 0;
BA_ "GenSigSendType" SG_ 1928 ISO_Quersperre_Resp_Data 3;
BA_ "GenSigFuncType" SG_ 1928 ISO_Quersperre_Resp_Data 9;
BA_ "GenSigSwitchedByIgnition" SG_ 1928 ISO_Quersperre_Resp_Data 0;
BA_ "GenSigSendType" SG_ 2621440019 ISOx_ABS_Req_FD_Data 3;
BA_ "GenSigFuncType" SG_ 2621440019 ISOx_ABS_Req_FD_Data 9;
BA_ "GenSigSwitchedByIgnition" SG_ 2621440019 ISOx_ABS_Req_FD_Data 0;
BA_ "GenSigSendType" SG_ 2621571091 ISOx_ABS_Resp_FD_Data 3;
BA_ "GenSigFuncType" SG_ 2621571091 ISOx_ABS_Resp_FD_Data 9;
BA_ "GenSigSwitchedByIgnition" SG_ 2621571091 ISOx_ABS_Resp_FD_Data 0;
BA_ "GenSigSendType" SG_ 2621440021 ISOx_Airbag_01_Req_FD_Data 3;
BA_ "GenSigFuncType" SG_ 2621440021 ISOx_Airbag_01_Req_FD_Data 9;
BA_ "GenSigSwitchedByIgnition" SG_ 2621440021 ISOx_Airbag_01_Req_FD_Data 0;
BA_ "GenSigSendType" SG_ 2621571093 ISOx_Airbag_01_Resp_FD_Data 3;
BA_ "GenSigFuncType" SG_ 2621571093 ISOx_Airbag_01_Resp_FD_Data 9;
BA_ "GenSigSwitchedByIgnition" SG_ 2621571093 ISOx_Airbag_01_Resp_FD_Data 0;
BA_ "GenSigSendType" SG_ 2621440015 ISOx_Allrad_Req_FD_Data 3;
BA_ "GenSigFuncType" SG_ 2621440015 ISOx_Allrad_Req_FD_Data 9;
BA_ "GenSigSwitchedByIgnition" SG_ 2621440015 ISOx_Allrad_Req_FD_Data 0;
BA_ "GenSigSendType" SG_ 2621571087 ISOx_Allrad_Resp_FD_Data 3;
BA_ "GenSigFuncType" SG_ 2621571087 ISOx_Allrad_Resp_FD_Data 9;
BA_ "GenSigSwitchedByIgnition" SG_ 2621571087 ISOx_Allrad_Resp_FD_Data 0;
BA_ "GenSigSendType" SG_ 2621440114 ISOx_Daempfer_Req_FD_Data 3;
BA_ "GenSigFuncType" SG_ 2621440114 ISOx_Daempfer_Req_FD_Data 9;
BA_ "GenSigSwitchedByIgnition" SG_ 2621440114 ISOx_Daempfer_Req_FD_Data 0;
BA_ "GenSigSendType" SG_ 2621571186 ISOx_Daempfer_Resp_FD_Data 3;
BA_ "GenSigFuncType" SG_ 2621571186 ISOx_Daempfer_Resp_FD_Data 9;
BA_ "GenSigSwitchedByIgnition" SG_ 2621571186 ISOx_Daempfer_Resp_FD_Data 0;
BA_ "GenSigSendType" SG_ 2621440059 ISOx_EBKV_Req_FD_Data 3;
BA_ "GenSigFuncType" SG_ 2621440059 ISOx_EBKV_Req_FD_Data 9;
BA_ "GenSigSwitchedByIgnition" SG_ 2621440059 ISOx_EBKV_Req_FD_Data 0;
BA_ "GenSigSendType" SG_ 2621571131 ISOx_EBKV_Resp_FD_Data 3;
BA_ "GenSigFuncType" SG_ 2621571131 ISOx_EBKV_Resp_FD_Data 9;
BA_ "GenSigSwitchedByIgnition" SG_ 2621571131 ISOx_EBKV_Resp_FD_Data 0;
BA_ "GenSigSendType" SG_ 2621505536 ISOx_Funkt_Req_All_FD_Data 3;
BA_ "GenSigFuncType" SG_ 2621505536 ISOx_Funkt_Req_All_FD_Data 9;
BA_ "GenSigSwitchedByIgnition" SG_ 2621505536 ISOx_Funkt_Req_All_FD_Data 0;
BA_ "GenSigSendType" SG_ 2621440018 ISOx_Lenkhilfe_Req_FD_Data 3;
BA_ "GenSigFuncType" SG_ 2621440018 ISOx_Lenkhilfe_Req_FD_Data 9;
BA_ "GenSigSwitchedByIgnition" SG_ 2621440018 ISOx_Lenkhilfe_Req_FD_Data 0;
BA_ "GenSigSendType" SG_ 2621571090 ISOx_Lenkhilfe_Resp_FD_Data 3;
BA_ "GenSigFuncType" SG_ 2621571090 ISOx_Lenkhilfe_Resp_FD_Data 9;
BA_ "GenSigSwitchedByIgnition" SG_ 2621571090 ISOx_Lenkhilfe_Resp_FD_Data 0;
BA_ "GenSigSendType" SG_ 2621440030 ISOx_Quersperre_Req_FD_Data 3;
BA_ "GenSigFuncType" SG_ 2621440030 ISOx_Quersperre_Req_FD_Data 9;
BA_ "GenSigSwitchedByIgnition" SG_ 2621440030 ISOx_Quersperre_Req_FD_Data 0;
BA_ "GenSigSendType" SG_ 2621571102 ISOx_Quersperre_Resp_FD_Data 3;
BA_ "GenSigFuncType" SG_ 2621571102 ISOx_Quersperre_Resp_FD_Data 9;
BA_ "GenSigSwitchedByIgnition" SG_ 2621571102 ISOx_Quersperre_Resp_FD_Data 0;
BA_ "GenSigSendType" SG_ 2549874892 ISOx_TSplit_L_Req_Data 3;
BA_ "GenSigFuncType" SG_ 2549874892 ISOx_TSplit_L_Req_Data 9;
BA_ "GenSigSwitchedByIgnition" SG_ 2549874892 ISOx_TSplit_L_Req_Data 0;
BA_ "GenSigSendType" SG_ 2621440204 ISOx_TSplit_L_Req_FD_Data 3;
BA_ "GenSigFuncType" SG_ 2621440204 ISOx_TSplit_L_Req_FD_Data 9;
BA_ "GenSigSwitchedByIgnition" SG_ 2621440204 ISOx_TSplit_L_Req_FD_Data 0;
BA_ "GenSigSendType" SG_ 2550005964 ISOx_TSplit_L_Resp_Data 3;
BA_ "GenSigFuncType" SG_ 2550005964 ISOx_TSplit_L_Resp_Data 9;
BA_ "GenSigSwitchedByIgnition" SG_ 2550005964 ISOx_TSplit_L_Resp_Data 0;
BA_ "GenSigSendType" SG_ 2621571276 ISOx_TSplit_L_Resp_FD_Data 3;
BA_ "GenSigFuncType" SG_ 2621571276 ISOx_TSplit_L_Resp_FD_Data 9;
BA_ "GenSigSwitchedByIgnition" SG_ 2621571276 ISOx_TSplit_L_Resp_FD_Data 0;
BA_ "GenSigSendType" SG_ 2549874893 ISOx_TSplit_R_Req_Data 3;
BA_ "GenSigFuncType" SG_ 2549874893 ISOx_TSplit_R_Req_Data 9;
BA_ "GenSigSwitchedByIgnition" SG_ 2549874893 ISOx_TSplit_R_Req_Data 0;
BA_ "GenSigSendType" SG_ 2621440205 ISOx_TSplit_R_Req_FD_Data 3;
BA_ "GenSigFuncType" SG_ 2621440205 ISOx_TSplit_R_Req_FD_Data 9;
BA_ "GenSigSwitchedByIgnition" SG_ 2621440205 ISOx_TSplit_R_Req_FD_Data 0;
BA_ "GenSigSendType" SG_ 2550005965 ISOx_TSplit_R_Resp_Data 3;
BA_ "GenSigFuncType" SG_ 2550005965 ISOx_TSplit_R_Resp_Data 9;
BA_ "GenSigSwitchedByIgnition" SG_ 2550005965 ISOx_TSplit_R_Resp_Data 0;
BA_ "GenSigSendType" SG_ 2621571277 ISOx_TSplit_R_Resp_FD_Data 3;
BA_ "GenSigFuncType" SG_ 2621571277 ISOx_TSplit_R_Resp_FD_Data 9;
BA_ "GenSigSwitchedByIgnition" SG_ 2621571277 ISOx_TSplit_R_Resp_FD_Data 0;
BA_ "GenSigSendType" SG_ 2527679684 Kamera_ASM_Data_1 0;
BA_ "GenSigSendType" SG_ 2527679684 Kamera_ASM_Data_2 0;
BA_ "GenSigSendType" SG_ 2527679684 Kamera_ASM_Data_3 0;
BA_ "GenSigSendType" SG_ 2527679684 Kamera_ASM_Data_4 0;
BA_ "GenSigSendType" SG_ 2527679684 Kamera_ASM_Data_5 0;
BA_ "GenSigSendType" SG_ 2527679684 Kamera_ASM_Data_6 0;
BA_ "GenSigSendType" SG_ 2527679684 Kamera_ASM_Ereignis 3;
BA_ "GenSigSendType" SG_ 2527679684 Kamera_ASM_Zeitstempel_02 3;
BA_ "GenSigStartValue" SG_ 2527679684 Kamera_ASM_Zeitstempel_02 255;
BA_ "GenSigSendType" SG_ 960 BCM_Ausparken_Betrieb 3;
BA_ "GenSigSwitchedByIgnition" SG_ 960 BCM_Ausparken_Betrieb 0;
BA_ "GenSigSendType" SG_ 960 BCM_Remotestart_Betrieb 3;
BA_ "GenSigSwitchedByIgnition" SG_ 960 BCM_Remotestart_Betrieb 0;
BA_ "GenSigSendType" SG_ 960 BCM_Remotestart_KL15_Anf 3;
BA_ "GenSigSwitchedByIgnition" SG_ 960 BCM_Remotestart_KL15_Anf 0;
BA_ "GenSigSendType" SG_ 960 BCM_Remotestart_MO_Start 3;
BA_ "GenSigSwitchedByIgnition" SG_ 960 BCM_Remotestart_MO_Start 0;
BA_ "GenSigSendType" SG_ 960 Klemmen_Status_01_BZ 0;
BA_ "GenSigFuncType" SG_ 960 Klemmen_Status_01_BZ 1;
BA_ "GenSigSwitchedByIgnition" SG_ 960 Klemmen_Status_01_BZ 0;
BA_ "GenSigSendType" SG_ 960 Klemmen_Status_01_CRC 0;
BA_ "GenSigFuncType" SG_ 960 Klemmen_Status_01_CRC 2;
BA_ "GenSigSwitchedByIgnition" SG_ 960 Klemmen_Status_01_CRC 0;
BA_ "GenSigSendType" SG_ 960 KST_Fahrerhinweis_1 3;
BA_ "GenSigSwitchedByIgnition" SG_ 960 KST_Fahrerhinweis_1 0;
BA_ "GenSigSendType" SG_ 960 KST_Fahrerhinweis_2 3;
BA_ "GenSigSwitchedByIgnition" SG_ 960 KST_Fahrerhinweis_2 0;
BA_ "GenSigSendType" SG_ 960 KST_Fahrerhinweis_4 3;
BA_ "GenSigSwitchedByIgnition" SG_ 960 KST_Fahrerhinweis_4 0;
BA_ "GenSigSendType" SG_ 960 KST_Fahrerhinweis_5 3;
BA_ "GenSigSwitchedByIgnition" SG_ 960 KST_Fahrerhinweis_5 0;
BA_ "GenSigSendType" SG_ 960 KST_Fahrerhinweis_6 3;
BA_ "GenSigSwitchedByIgnition" SG_ 960 KST_Fahrerhinweis_6 0;
BA_ "GenSigSendType" SG_ 960 KST_Warn_P1_ZST_def 3;
BA_ "GenSigSwitchedByIgnition" SG_ 960 KST_Warn_P1_ZST_def 0;
BA_ "GenSigSendType" SG_ 960 KST_Warn_P2_ZST_def 3;
BA_ "GenSigSwitchedByIgnition" SG_ 960 KST_Warn_P2_ZST_def 0;
BA_ "GenSigSendType" SG_ 960 RSt_Fahrerhinweise 3;
BA_ "GenSigSwitchedByIgnition" SG_ 960 RSt_Fahrerhinweise 0;
BA_ "GenSigSendType" SG_ 960 ZAS_Kl_15 3;
BA_ "NWM-WakeupAllowed" SG_ 960 ZAS_Kl_15 1;
BA_ "GenSigFuncType" SG_ 960 ZAS_Kl_15 6;
BA_ "GenSigSwitchedByIgnition" SG_ 960 ZAS_Kl_15 0;
BA_ "GenSigSendType" SG_ 960 ZAS_Kl_50_Startanforderung 3;
BA_ "GenSigSwitchedByIgnition" SG_ 960 ZAS_Kl_50_Startanforderung 0;
BA_ "GenSigSendType" SG_ 960 ZAS_Kl_Infotainment 3;
BA_ "GenSigSwitchedByIgnition" SG_ 960 ZAS_Kl_Infotainment 0;
BA_ "GenSigSendType" SG_ 960 ZAS_Kl_S 3;
BA_ "GenSigSwitchedByIgnition" SG_ 960 ZAS_Kl_S 0;
BA_ "GenSigSendType" SG_ 960 ZAS_Kl_X 3;
BA_ "GenSigSwitchedByIgnition" SG_ 960 ZAS_Kl_X 0;
BA_ "GenSigSendType" SG_ 2463978753 Klemmen_Status_02_BZ 0;
BA_ "GenSigFuncType" SG_ 2463978753 Klemmen_Status_02_BZ 1;
BA_ "GenSigSwitchedByIgnition" SG_ 2463978753 Klemmen_Status_02_BZ 0;
BA_ "GenSigSendType" SG_ 2463978753 Klemmen_Status_02_CRC 0;
BA_ "GenSigFuncType" SG_ 2463978753 Klemmen_Status_02_CRC 2;
BA_ "GenSigSwitchedByIgnition" SG_ 2463978753 Klemmen_Status_02_CRC 0;
BA_ "GenSigSendType" SG_ 2463978753 KST_ComfortReadyStatus 4;
BA_ "GenSigSwitchedByIgnition" SG_ 2463978753 KST_ComfortReadyStatus 0;
BA_ "GenSigSendType" SG_ 2463978753 KST_Freigabe_Zustand 4;
BA_ "GenSigSwitchedByIgnition" SG_ 2463978753 KST_Freigabe_Zustand 0;
BA_ "GenSigSendType" SG_ 2463978753 KST_Sonderzustand_Anforderung 4;
BA_ "GenSigSwitchedByIgnition" SG_ 2463978753 KST_Sonderzustand_Anforderung 0;
BA_ "Fehlerwert" SG_ 2463978753 KST_Sonderzustand_Anforderung 31;
BA_ "GenSigSendType" SG_ 2463978753 KST_Sonderzustand_Status 4;
BA_ "GenSigSwitchedByIgnition" SG_ 2463978753 KST_Sonderzustand_Status 0;
BA_ "Fehlerwert" SG_ 2463978753 KST_Sonderzustand_Status 3;
BA_ "GenSigSendType" SG_ 2463978753 KST_WFS_Fahrfreigabe_Anforderung 4;
BA_ "GenSigSwitchedByIgnition" SG_ 2463978753 KST_WFS_Fahrfreigabe_Anforderung 0;
BA_ "GenSigSendType" SG_ 1505 BCM1_Aussen_Temp_ungef 0;
BA_ "GenSigStartValue" SG_ 1505 BCM1_Aussen_Temp_ungef 254;
BA_ "GenSigSwitchedByIgnition" SG_ 1505 BCM1_Aussen_Temp_ungef 0;
BA_ "Fehlerwert" SG_ 1505 BCM1_Aussen_Temp_ungef 255;
BA_ "GenSigSendType" SG_ 1505 BCM1_FStatus_Aussentemp_ungef 0;
BA_ "GenSigStartValue" SG_ 1505 BCM1_FStatus_Aussentemp_ungef 1;
BA_ "GenSigSwitchedByIgnition" SG_ 1505 BCM1_FStatus_Aussentemp_ungef 0;
BA_ "GenSigSendType" SG_ 1505 BCM1_Kompressorstrom_ist 0;
BA_ "GenSigStartValue" SG_ 1505 BCM1_Kompressorstrom_ist 254;
BA_ "GenSigSwitchedByIgnition" SG_ 1505 BCM1_Kompressorstrom_ist 0;
BA_ "Fehlerwert" SG_ 1505 BCM1_Kompressorstrom_ist 255;
BA_ "GenSigSendType" SG_ 1505 BCM1_OBD_FStatus_ATemp 0;
BA_ "GenSigSwitchedByIgnition" SG_ 1505 BCM1_OBD_FStatus_ATemp 0;
BA_ "GenSigSendType" SG_ 1505 BCM1_PTC_stufig_Status 0;
BA_ "GenSigStartValue" SG_ 1505 BCM1_PTC_stufig_Status 6;
BA_ "GenSigSwitchedByIgnition" SG_ 1505 BCM1_PTC_stufig_Status 0;
BA_ "Fehlerwert" SG_ 1505 BCM1_PTC_stufig_Status 7;
BA_ "GenSigSendType" SG_ 1505 BCM_Heizungsabsperrventil_Status 0;
BA_ "GenSigStartValue" SG_ 1505 BCM_Heizungsabsperrventil_Status 2;
BA_ "GenSigSwitchedByIgnition" SG_ 1505 BCM_Heizungsabsperrventil_Status 0;
BA_ "Fehlerwert" SG_ 1505 BCM_Heizungsabsperrventil_Status 3;
BA_ "GenSigSendType" SG_ 1505 BCM_Heizungspumpe_Status 0;
BA_ "GenSigStartValue" SG_ 1505 BCM_Heizungspumpe_Status 2;
BA_ "GenSigSwitchedByIgnition" SG_ 1505 BCM_Heizungspumpe_Status 0;
BA_ "Fehlerwert" SG_ 1505 BCM_Heizungspumpe_Status 3;
BA_ "GenSigSendType" SG_ 1505 BCM_Kompressorkupplung_Status 0;
BA_ "GenSigStartValue" SG_ 1505 BCM_Kompressorkupplung_Status 2;
BA_ "GenSigSwitchedByIgnition" SG_ 1505 BCM_Kompressorkupplung_Status 0;
BA_ "Fehlerwert" SG_ 1505 BCM_Kompressorkupplung_Status 3;
BA_ "GenSigSendType" SG_ 2549088275 ABS_Abschaltstufe 0;
BA_ "GenSigSwitchedByIgnition" SG_ 2549088275 ABS_Abschaltstufe 0;
BA_ "GenSigSendType" SG_ 2549088275 ABS_Transport_Mode 0;
BA_ "GenSigSwitchedByIgnition" SG_ 2549088275 ABS_Transport_Mode 0;
BA_ "GenSigSendType" SG_ 2549088275 ESP_KD_Fehler 0;
BA_ "GenSigSwitchedByIgnition" SG_ 2549088275 ESP_KD_Fehler 0;
BA_ "GenSigSendType" SG_ 2549088275 ESP_KompSchutz 0;
BA_ "GenSigSwitchedByIgnition" SG_ 2549088275 ESP_KompSchutz 0;
BA_ "GenSigSendType" SG_ 2549088275 ESP_Nachlauftyp 0;
BA_ "GenSigStartValue" SG_ 2549088275 ESP_Nachlauftyp 2;
BA_ "GenSigSwitchedByIgnition" SG_ 2549088275 ESP_Nachlauftyp 0;
BA_ "GenSigSendType" SG_ 2549088275 KN_ESP_BusKnockOut 0;
BA_ "GenSigSwitchedByIgnition" SG_ 2549088275 KN_ESP_BusKnockOut 0;
BA_ "GenSigSendType" SG_ 2549088275 KN_ESP_BusKnockOutTimer 0;
BA_ "GenSigSwitchedByIgnition" SG_ 2549088275 KN_ESP_BusKnockOutTimer 0;
BA_ "GenSigSendType" SG_ 2549088275 KN_ESP_DiagPfad 0;
BA_ "GenSigSwitchedByIgnition" SG_ 2549088275 KN_ESP_DiagPfad 0;
BA_ "GenSigSendType" SG_ 2549088275 KN_ESP_ECUKnockOut 0;
BA_ "GenSigSwitchedByIgnition" SG_ 2549088275 KN_ESP_ECUKnockOut 0;
BA_ "GenSigSendType" SG_ 2549088275 KN_ESP_ECUKnockOutTimer 0;
BA_ "GenSigSwitchedByIgnition" SG_ 2549088275 KN_ESP_ECUKnockOutTimer 0;
BA_ "GenSigSendType" SG_ 2549088275 NM_ESP_Wakeup 0;
BA_ "NWM-WakeupAllowed" SG_ 2549088275 NM_ESP_Wakeup 1;
BA_ "GenSigSwitchedByIgnition" SG_ 2549088275 NM_ESP_Wakeup 0;
BA_ "GenSigSendType" SG_ 2549088277 Airbag_01_Abschaltstufe 0;
BA_ "GenSigSwitchedByIgnition" SG_ 2549088277 Airbag_01_Abschaltstufe 0;
BA_ "GenSigSendType" SG_ 2549088277 Airbag_01_KD_Fehler 0;
BA_ "GenSigSwitchedByIgnition" SG_ 2549088277 Airbag_01_KD_Fehler 0;
BA_ "GenSigSendType" SG_ 2549088277 Airbag_01_KompSchutz 0;
BA_ "GenSigSwitchedByIgnition" SG_ 2549088277 Airbag_01_KompSchutz 0;
BA_ "GenSigSendType" SG_ 2549088277 Airbag_01_Nachlauftyp 0;
BA_ "GenSigStartValue" SG_ 2549088277 Airbag_01_Nachlauftyp 2;
BA_ "GenSigSwitchedByIgnition" SG_ 2549088277 Airbag_01_Nachlauftyp 0;
BA_ "GenSigSendType" SG_ 2549088277 Airbag_01_Transport_Mode 0;
BA_ "GenSigSwitchedByIgnition" SG_ 2549088277 Airbag_01_Transport_Mode 0;
BA_ "GenSigSendType" SG_ 2549088277 KN_Airbag_01_BusKnockOut 0;
BA_ "GenSigSwitchedByIgnition" SG_ 2549088277 KN_Airbag_01_BusKnockOut 0;
BA_ "GenSigSendType" SG_ 2549088277 KN_Airbag_01_BusKnockOutTimer 0;
BA_ "GenSigSwitchedByIgnition" SG_ 2549088277 KN_Airbag_01_BusKnockOutTimer 0;
BA_ "GenSigSendType" SG_ 2549088277 KN_Airbag_01_DiagPfad 0;
BA_ "GenSigSwitchedByIgnition" SG_ 2549088277 KN_Airbag_01_DiagPfad 0;
BA_ "GenSigSendType" SG_ 2549088277 KN_Airbag_01_ECUKnockOut 0;
BA_ "GenSigSwitchedByIgnition" SG_ 2549088277 KN_Airbag_01_ECUKnockOut 0;
BA_ "GenSigSendType" SG_ 2549088277 KN_Airbag_01_ECUKnockOutTimer 0;
BA_ "GenSigSwitchedByIgnition" SG_ 2549088277 KN_Airbag_01_ECUKnockOutTimer 0;
BA_ "GenSigSendType" SG_ 2549088277 NM_Airbag_01_Wakeup 0;
BA_ "NWM-WakeupAllowed" SG_ 2549088277 NM_Airbag_01_Wakeup 1;
BA_ "GenSigSwitchedByIgnition" SG_ 2549088277 NM_Airbag_01_Wakeup 0;
BA_REL_ "GenSigTimeoutTime" BU_SG_REL_ Airbag SG_ 2463978866 LDW_02_alt 2000;
BA_REL_ "GenSigTimeoutTime" BU_SG_REL_ Airbag SG_ 2463978866 TA_01_alt 2000;
BA_REL_ "GenSigTimeoutTime" BU_SG_REL_ Airbag SG_ 2463978866 RDK_11_alt 2000;
BA_REL_ "GenSigTimeoutTime" BU_SG_REL_ Airbag SG_ 2463978866 PLA_04_alt 2000;
BA_REL_ "GenSigTimeoutTime" BU_SG_REL_ Airbag SG_ 2463978866 TPA_02_alt 2000;
BA_REL_ "GenSigTimeoutTime" BU_SG_REL_ Airbag SG_ 2463978866 ARA_Status_01_alt 2000;
BA_REL_ "GenSigTimeoutTime" BU_SG_REL_ Airbag SG_ 2463978866 WBA_05_alt 2000;
BA_REL_ "GenSigTimeoutTime" BU_SG_REL_ Airbag SG_ 2463978866 KLR_01_alt 2000;
BA_REL_ "GenSigTimeoutTime" BU_SG_REL_ Airbag SG_ 2463978866 Kamera_Status_alt 2000;
BA_REL_ "GenSigTimeoutTime" BU_SG_REL_ Airbag SG_ 2463978866 RDK_02_alt 2000;
BA_REL_ "GenSigTimeoutTime" BU_SG_REL_ Airbag SG_ 2463978866 PLA_06_alt 2000;
BA_REL_ "GenSigTimeoutTime" BU_SG_REL_ Airbag SG_ 2463978866 LDW_Texte 2000;
BA_REL_ "GenSigTimeoutTime" BU_SG_REL_ Airbag SG_ 2463978866 LDW_Lernmodus_seitenabhaengig 2000;
BA_REL_ "GenSigTimeoutTime" BU_SG_REL_ Airbag SG_ 2463978866 LDW_Status_LED_gelb 2000;
BA_REL_ "GenSigTimeoutTime" BU_SG_REL_ Airbag SG_ 2463978866 LDW_Status_LED_gruen 2000;
BA_REL_ "GenSigTimeoutTime" BU_SG_REL_ Airbag SG_ 2463978866 TA_Status 2000;
BA_REL_ "GenSigTimeoutTime" BU_SG_REL_ Airbag SG_ 2463978866 WBA_Status_AWU 2000;
BA_REL_ "GenSigTimeoutTime" BU_SG_REL_ Airbag SG_ 2463978866 PLAIPA_PaCo_FunctionState 2000;
BA_REL_ "GenSigTimeoutTime" BU_SG_REL_ Airbag SG_ 2463978866 PLAIPA_PaCo_MainState 2000;
BA_REL_ "GenSigTimeoutTime" BU_SG_REL_ Airbag SG_ 2463978866 KLR_Touchauswertung 2000;
BA_REL_ "GenSigTimeoutTime" BU_SG_REL_ Airbag SG_ 2463978866 TPA_Status 2000;
BA_REL_ "GenSigTimeoutTime" BU_SG_REL_ Airbag SG_ 2463978866 ARA_Status 2000;
BA_REL_ "GenSigTimeoutTime" BU_SG_REL_ Airbag SG_ 2463978866 TA_Texte_02 2000;
BA_REL_ "GenSigTimeoutTime" BU_SG_REL_ Airbag SG_ 2463978866 TA_Texte 2000;
BA_REL_ "GenSigTimeoutTime" BU_SG_REL_ Airbag SG_ 2463978866 TA_Handsoff_LED 2000;
BA_REL_ "GenSigTimeoutTime" BU_SG_REL_ Airbag SG_ 2463978866 TA_Fehler 2000;
BA_REL_ "GenSigTimeoutTime" BU_SG_REL_ Airbag SG_ 2463978866 TA_aktiv_HMI 2000;
BA_REL_ "GenSigTimeoutTime" BU_SG_REL_ Airbag SG_ 2463978866 TA_Spurwechsel 2000;
BA_REL_ "GenSigTimeoutTime" BU_SG_REL_ Airbag SG_ 2463978866 VZE_Status_EDR 2000;
BA_REL_ "GenSigTimeoutTime" BU_SG_REL_ Airbag SG_ 2463978866 TPMS_WarnLmpStP 2000;
BA_REL_ "GenSigTimeoutTime" BU_SG_REL_ Airbag SG_ 2463978866 RDK_FMVSS138_Lampe 2000;
BA_REL_ "GenSigTimeoutTime" BU_SG_REL_ Airbag SG_ 2463978866 LDW_Status_Anzeige 2000;
BA_REL_ "GenSigTimeoutTime" BU_SG_REL_ Airbag SG_ 2463978866 TPMS_WarnLmpStMil 2000;
BA_REL_ "GenSigTimeoutTime" BU_SG_REL_ Airbag SG_ 2463978866 RDK_FMVSS138_MIL 2000;
BA_REL_ "GenSigTimeoutTime" BU_SG_REL_ Airbag SG_ 2463978866 RA_Status 2000;
BA_REL_ "GenSigTimeoutTime" BU_SG_REL_ Airbag SG_ 173 GE_Fahrstufe 500;
BA_REL_ "GenSigTimeoutTime" BU_SG_REL_ Airbag SG_ 891 GNSS_UTC_Zeit 5000;
BA_REL_ "GenSigTimeoutTime" BU_SG_REL_ Airbag SG_ 2527679684 Kamera_ASM_Ereignis 5000;
BA_REL_ "GenSigTimeoutTime" BU_SG_REL_ Airbag SG_ 2527679684 Kamera_ASM_Zeitstempel_02 5000;
BA_REL_ "GenSigTimeoutTime" BU_SG_REL_ Airbag SG_ 2527679684 Kamera_ASM_Data_1 5000;
BA_REL_ "GenSigTimeoutTime" BU_SG_REL_ Airbag SG_ 2527679684 Kamera_ASM_Data_2 5000;
BA_REL_ "GenSigTimeoutTime" BU_SG_REL_ Airbag SG_ 2527679684 Kamera_ASM_Data_3 5000;
BA_REL_ "GenSigTimeoutTime" BU_SG_REL_ Airbag SG_ 2527679684 Kamera_ASM_Data_4 5000;
BA_REL_ "GenSigTimeoutTime" BU_SG_REL_ Airbag SG_ 2527679684 Kamera_ASM_Data_5 5000;
BA_REL_ "GenSigTimeoutTime" BU_SG_REL_ Airbag SG_ 2527679684 Kamera_ASM_Data_6 5000;
BA_REL_ "GenSigTimeoutTime" BU_SG_REL_ Airbag SG_ 2463978753 KST_Sonderzustand_Status 5000;
BA_REL_ "GenSigTimeoutTime" BU_SG_REL_ Airbag SG_ 2463978753 KST_Sonderzustand_Anforderung 5000;
BA_REL_ "GenSigTimeoutTime" BU_SG_REL_ Airbag SG_ 960 Klemmen_Status_01_CRC 1000;
BA_REL_ "GenSigTimeoutTime" BU_SG_REL_ Airbag SG_ 960 Klemmen_Status_01_BZ 1000;
BA_REL_ "GenSigTimeoutTime" BU_SG_REL_ Airbag SG_ 960 ZAS_Kl_S 1000;
BA_REL_ "GenSigTimeoutTime" BU_SG_REL_ Airbag SG_ 960 ZAS_Kl_15 1000;
BA_REL_ "GenSigTimeoutTime" BU_SG_REL_ Airbag SG_ 1505 BCM1_Aussen_Temp_ungef 2000;
BA_REL_ "GenSigTimeoutTime" BU_SG_REL_ Airbag SG_ 1505 BCM1_FStatus_Aussentemp_ungef 2000;
BA_REL_ "GenSigTimeoutTime" BU_SG_REL_ Allrad_Haldex SG_ 270 GE_Schaltablauf 500;
BA_REL_ "GenSigTimeoutTime" BU_SG_REL_ Allrad_Haldex SG_ 270 GE_Zielgang 500;
BA_REL_ "GenSigTimeoutTime" BU_SG_REL_ Allrad_Haldex SG_ 509 GE_LaunchControl 1000;
BA_REL_ "GenSigTimeoutTime" BU_SG_REL_ Allrad_Haldex SG_ 509 GE_Freilauf_Status 1000;
BA_REL_ "GenSigTimeoutTime" BU_SG_REL_ DCC_Gen3 SG_ 182 IMU_PitchRate 500;
BA_REL_ "GenSigTimeoutTime" BU_SG_REL_ DCC_Gen3 SG_ 182 IMU_AVert 500;
BA_REL_ "GenSigTimeoutTime" BU_SG_REL_ DCC_Gen3 SG_ 182 IMU_RollRate 500;
BA_REL_ "GenSigTimeoutTime" BU_SG_REL_ DCC_Gen3 SG_ 960 ZAS_Kl_15 1000;
BA_REL_ "GenSigTimeoutTime" BU_SG_REL_ ESC_MQBW SG_ 270 Getriebe_50_CRC 500;
BA_REL_ "GenSigTimeoutTime" BU_SG_REL_ ESC_MQBW SG_ 270 Getriebe_50_BZ 500;
BA_REL_ "GenSigTimeoutTime" BU_SG_REL_ ESC_MQBW SG_ 270 GE_Uefkt 500;
BA_REL_ "GenSigTimeoutTime" BU_SG_REL_ ESC_MQBW SG_ 270 GE2_Fahrstufe 500;
BA_REL_ "GenSigTimeoutTime" BU_SG_REL_ ESC_MQBW SG_ 270 GE2_Ursache_Fahrstufe_N 500;
BA_REL_ "GenSigTimeoutTime" BU_SG_REL_ ESC_MQBW SG_ 270 GE_Schaltablauf 500;
BA_REL_ "GenSigTimeoutTime" BU_SG_REL_ ESC_MQBW SG_ 270 GE_Status_Kraftschluss 500;
BA_REL_ "GenSigTimeoutTime" BU_SG_REL_ ESC_MQBW SG_ 270 GE_Zielgang 500;
BA_REL_ "GenSigTimeoutTime" BU_SG_REL_ ESC_MQBW SG_ 270 GE_Verlustmoment 500;
BA_REL_ "GenSigTimeoutTime" BU_SG_REL_ ESC_MQBW SG_ 270 GE_HYB_IstStatus_K0 500;
BA_REL_ "GenSigTimeoutTime" BU_SG_REL_ ESC_MQBW SG_ 509 Getriebe_51_CRC 1000;
BA_REL_ "GenSigTimeoutTime" BU_SG_REL_ ESC_MQBW SG_ 509 Getriebe_51_BZ 1000;
BA_REL_ "GenSigTimeoutTime" BU_SG_REL_ ESC_MQBW SG_ 509 GE_OBD_Status 1000;
BA_REL_ "GenSigTimeoutTime" BU_SG_REL_ ESC_MQBW SG_ 509 GE_Freilauf_Status 1000;
BA_REL_ "GenSigTimeoutTime" BU_SG_REL_ ESC_MQBW SG_ 509 GE_Parken_beibehalten_HMS 1000;
BA_REL_ "GenSigTimeoutTime" BU_SG_REL_ ESC_MQBW SG_ 509 GE_Anforderung_HMS 1000;
BA_REL_ "GenSigTimeoutTime" BU_SG_REL_ ESC_MQBW SG_ 626 HVLM_Anforderung_HMS 1000;
BA_REL_ "GenSigTimeoutTime" BU_SG_REL_ ESC_MQBW SG_ 626 HVLM_Parken_beibehalten_HMS 1000;
BA_REL_ "GenSigTimeoutTime" BU_SG_REL_ ESC_MQBW SG_ 2589283966 IMU_StObd_StFail1 5000;
BA_REL_ "GenSigTimeoutTime" BU_SG_REL_ ESC_MQBW SG_ 2589283966 IMU_StObd_StFail2 5000;
BA_REL_ "GenSigTimeoutTime" BU_SG_REL_ ESC_MQBW SG_ 2589283966 IMU_StObd_StFail3 5000;
BA_REL_ "GenSigTimeoutTime" BU_SG_REL_ ESC_MQBW SG_ 2589283966 IMU_StObd_StFail4 5000;
BA_REL_ "GenSigTimeoutTime" BU_SG_REL_ ESC_MQBW SG_ 2589283966 IMU_StObd_StFail5 5000;
BA_REL_ "GenSigTimeoutTime" BU_SG_REL_ ESC_MQBW SG_ 2589283966 IMU_StObd_StFail6 5000;
BA_REL_ "GenSigTimeoutTime" BU_SG_REL_ ESC_MQBW SG_ 2589283966 IMU_StObd_StFail7 5000;
BA_REL_ "GenSigTimeoutTime" BU_SG_REL_ ESC_MQBW SG_ 2589283966 IMU_StObd_StFail8 5000;
BA_REL_ "GenSigTimeoutTime" BU_SG_REL_ ESC_MQBW SG_ 2589283966 IMU_StObd_StFail9 5000;
BA_REL_ "GenSigTimeoutTime" BU_SG_REL_ ESC_MQBW SG_ 2589283966 IMU_StObd_StFail10 5000;
BA_REL_ "GenSigTimeoutTime" BU_SG_REL_ ESC_MQBW SG_ 2589283966 IMU_StObd_StFail11 5000;
BA_REL_ "GenSigTimeoutTime" BU_SG_REL_ ESC_MQBW SG_ 2589283966 IMU_StObd_StChk1 5000;
BA_REL_ "GenSigTimeoutTime" BU_SG_REL_ ESC_MQBW SG_ 2589283966 IMU_StObd_StChk2 5000;
BA_REL_ "GenSigTimeoutTime" BU_SG_REL_ ESC_MQBW SG_ 2589283966 IMU_StObd_StChk3 5000;
BA_REL_ "GenSigTimeoutTime" BU_SG_REL_ ESC_MQBW SG_ 2589283966 IMU_StObd_StChk4 5000;
BA_REL_ "GenSigTimeoutTime" BU_SG_REL_ ESC_MQBW SG_ 2589283966 IMU_StObd_StChk5 5000;
BA_REL_ "GenSigTimeoutTime" BU_SG_REL_ ESC_MQBW SG_ 2589283966 IMU_StObd_StChk6 5000;
BA_REL_ "GenSigTimeoutTime" BU_SG_REL_ ESC_MQBW SG_ 2589283966 IMU_StObd_StChk7 5000;
BA_REL_ "GenSigTimeoutTime" BU_SG_REL_ ESC_MQBW SG_ 2589283966 IMU_StObd_StChk8 5000;
BA_REL_ "GenSigTimeoutTime" BU_SG_REL_ ESC_MQBW SG_ 2589283966 IMU_StObd_StChk9 5000;
BA_REL_ "GenSigTimeoutTime" BU_SG_REL_ ESC_MQBW SG_ 2589283966 IMU_StObd_StChk10 5000;
BA_REL_ "GenSigTimeoutTime" BU_SG_REL_ ESC_MQBW SG_ 2589283966 IMU_StObd_StChk11 5000;
BA_REL_ "GenSigTimeoutTime" BU_SG_REL_ ESC_MQBW SG_ 182 IMU_05_CRC 500;
BA_REL_ "GenSigTimeoutTime" BU_SG_REL_ ESC_MQBW SG_ 182 IMU_05_BZ 500;
BA_REL_ "GenSigTimeoutTime" BU_SG_REL_ ESC_MQBW SG_ 182 IMU_ALat_Qlfr 500;
BA_REL_ "GenSigTimeoutTime" BU_SG_REL_ ESC_MQBW SG_ 182 IMU_ALat 500;
BA_REL_ "GenSigTimeoutTime" BU_SG_REL_ ESC_MQBW SG_ 182 IMU_ALgt 500;
BA_REL_ "GenSigTimeoutTime" BU_SG_REL_ ESC_MQBW SG_ 182 IMU_ALgt_Qlfr 500;
BA_REL_ "GenSigTimeoutTime" BU_SG_REL_ ESC_MQBW SG_ 182 IMU_YawRate_Qlfr 500;
BA_REL_ "GenSigTimeoutTime" BU_SG_REL_ ESC_MQBW SG_ 182 IMU_YawRate 500;
BA_REL_ "GenSigTimeoutTime" BU_SG_REL_ ESC_MQBW SG_ 182 IMU_RollRate 500;
BA_REL_ "GenSigTimeoutTime" BU_SG_REL_ ESC_MQBW SG_ 182 IMU_RollRate_Qlfr 500;
BA_REL_ "GenSigTimeoutTime" BU_SG_REL_ ESC_MQBW SG_ 312 IPA_01_CRC 1000;
BA_REL_ "GenSigTimeoutTime" BU_SG_REL_ ESC_MQBW SG_ 312 IPA_01_BZ 1000;
BA_REL_ "GenSigTimeoutTime" BU_SG_REL_ ESC_MQBW SG_ 312 IPA_Status 1000;
BA_REL_ "GenSigTimeoutTime" BU_SG_REL_ ESC_MQBW SG_ 2527679583 Parken_aktives_System_02 5000;
BA_REL_ "GenSigTimeoutTime" BU_SG_REL_ ESC_MQBW SG_ 2463978753 KST_Sonderzustand_Status 5000;
BA_REL_ "GenSigTimeoutTime" BU_SG_REL_ ESC_MQBW SG_ 2463978753 KST_Sonderzustand_Anforderung 5000;
BA_REL_ "GenSigTimeoutTime" BU_SG_REL_ ESC_MQBW SG_ 960 Klemmen_Status_01_CRC 1000;
BA_REL_ "GenSigTimeoutTime" BU_SG_REL_ ESC_MQBW SG_ 960 Klemmen_Status_01_BZ 1000;
BA_REL_ "GenSigTimeoutTime" BU_SG_REL_ ESC_MQBW SG_ 960 ZAS_Kl_15 1000;
BA_REL_ "GenSigTimeoutTime" BU_SG_REL_ ESC_MQBW SG_ 1505 BCM1_Aussen_Temp_ungef 2000;
BA_REL_ "GenSigTimeoutTime" BU_SG_REL_ ESC_MQBW SG_ 1505 BCM1_OBD_FStatus_ATemp 2000;
BA_REL_ "GenSigTimeoutTime" BU_SG_REL_ Gateway_Max SG_ 2549088275 ESP_Nachlauftyp 5000;
BA_REL_ "GenSigTimeoutTime" BU_SG_REL_ Gateway_Max SG_ 2549088275 KN_ESP_DiagPfad 5000;
BA_REL_ "GenSigTimeoutTime" BU_SG_REL_ Gateway_Max SG_ 2549088275 ESP_KD_Fehler 2500;
BA_REL_ "GenSigTimeoutTime" BU_SG_REL_ Gateway_Max SG_ 2549088277 Airbag_01_Nachlauftyp 5000;
BA_REL_ "GenSigTimeoutTime" BU_SG_REL_ Gateway_Max SG_ 2549088277 KN_Airbag_01_DiagPfad 5000;
BA_REL_ "GenSigTimeoutTime" BU_SG_REL_ Gateway_Max SG_ 2549088277 Airbag_01_KD_Fehler 2500;
BA_REL_ "GenSigTimeoutTime" BU_SG_REL_ Lenkhilfe_REPS SG_ 771 HCA_QFK_AnfStat 5000;
BA_REL_ "GenSigTimeoutTime" BU_SG_REL_ Lenkhilfe_REPS SG_ 771 HCA_QFK_Spuerb 5000;
BA_REL_ "GenSigTimeoutTime" BU_SG_REL_ Lenkhilfe_REPS SG_ 771 HCA_QFK_KruemmSoll 5000;
BA_REL_ "GenSigTimeoutTime" BU_SG_REL_ Lenkhilfe_REPS SG_ 771 HCA_QFK_KruemmSoll_VZ 5000;
BA_REL_ "GenSigTimeoutTime" BU_SG_REL_ Lenkhilfe_REPS SG_ 771 HCA_QFK_Signal1 5000;
BA_REL_ "GenSigTimeoutTime" BU_SG_REL_ Lenkhilfe_REPS SG_ 771 HCA_QFK_Art1 5000;
BA_REL_ "GenSigTimeoutTime" BU_SG_REL_ Lenkhilfe_REPS SG_ 771 HCA_QFK_Art2 5000;
BA_REL_ "GenSigTimeoutTime" BU_SG_REL_ Lenkhilfe_REPS SG_ 771 HCA_QFK_Signal2 5000;
BA_REL_ "GenSigTimeoutTime" BU_SG_REL_ Lenkhilfe_REPS SG_ 771 HCA_03_Sendestatus 5000;
BA_REL_ "GenSigTimeoutTime" BU_SG_REL_ Lenkhilfe_REPS SG_ 771 HCA_QFK_KrSoll_VZ 5000;
BA_REL_ "GenSigTimeoutTime" BU_SG_REL_ Lenkhilfe_REPS SG_ 771 HCA_QFK_KrSoll 5000;
BA_REL_ "GenSigTimeoutTime" BU_SG_REL_ Lenkhilfe_REPS SG_ 960 ZAS_Kl_15 1000;
VAL_ 2463978866 LDW_02_alt 0 "aktuell" 1 "veraltet" ;
VAL_ 2463978866 TA_01_alt 0 "aktuell" 1 "veraltet" ;
VAL_ 2463978866 RDK_11_alt 0 "aktuell" 1 "veraltet" ;
VAL_ 2463978866 PLA_04_alt 0 "aktuell" 1 "veraltet" ;
VAL_ 2463978866 TPA_02_alt 0 "aktuell" 1 "veraltet" ;
VAL_ 2463978866 ARA_Status_01_alt 0 "aktuell" 1 "veraltet" ;
VAL_ 2463978866 WBA_05_alt 0 "aktuell" 1 "veraltet" ;
VAL_ 2463978866 KLR_01_alt 0 "aktuell" 1 "veraltet" ;
VAL_ 2463978866 Kamera_Status_alt 0 "aktuell" 1 "veraltet" ;
VAL_ 2463978866 RDK_02_alt 0 "aktuell" 1 "veraltet" ;
VAL_ 2463978866 PLA_06_alt 0 "aktuell" 1 "veraltet" ;
VAL_ 2463978866 LDW_Texte 0 "keine_Anzeige" 1 "Laneassist_zur_Zeit_n_verfuegbar" 2 "Laneassist_Systemfehler" 3 "Laneassist_zur_Zeit_keine_SSicht" 4 "Laneassist_Fahreruebernahme" 5 "Laneassist_n_verfuegbar_FoD" 6 "Emergency_Alert_Fahreruebernahme" 7 "Laneassist_FahreruebernahmeLeise" 8 "Laneassist_FahreruebernahmeStumm" 9 "EA_Fahrstreifenwechsel" 10 "Laneassist_Deaktiviert" 11 "Laneassist_Fahreruebernahme_hoch" 12 "Laneassist_mittig_fahren" 13 "Laneassist_adaptiv_aktiv" 14 "Laneassist_adaptiv_deaktiv" 15 "Systgr_Fzgfueh_sofort_uebernehm" ;
VAL_ 2463978866 LDW_Lernmodus_seitenabhaengig 0 "links_aus__rechts_aus" 1 "HCCA_links_an__rechts_an" 2 "HCCA_links_an__rechts_Warnung" 3 "HCCA_links_Warnung__rechts_an" 4 "links_gestrichelt_rechts_Warnung" 5 "links_outlined__rechts_outlined" 6 "links_outlined__rechts_an" 7 "links_outlined__rechts_Warnung" 8 "links_Warnung_rechts_gestrichel" 9 "links_an__rechts_outlined" 10 "links_an__rechts_an" 11 "links_an__rechts_Warnung" 12 "links_und_rechts_gestrichelt" 13 "links_Warnung__rechts_outlined" 14 "links_Warnung__rechts_an" 15 "links_Warnung__rechts_Warnung" ;
VAL_ 2463978866 LDW_Status_LED_gelb 0 "LDW-Status gelb aus" 1 "LDW-Status gelb aktiv" ;
VAL_ 2463978866 LDW_Status_LED_gruen 0 "LDW-Status gruen aus" 1 "LDW-Status gruen aktiv" ;
VAL_ 2463978866 TA_Status 0 "Keine_Anzeige" 1 "Passiv" 2 "Aktiv" 3 "Warnung" ;
VAL_ 2463978866 WBA_Status_AWU 0 "deactivated" 1 "init" 2 "inactive" 3 "requested" 4 "active" 5 "suppressed" 6 "aborted_general" 7 "restricted" 8 "aborted_by_driver" 9 "not_available" 15 "Fehler" ;
VAL_ 2463978866 PLAIPA_PaCo_FunctionState 0 "Resume_Possible" 1 "Park_In_SearchMode" 2 "Park_In_SlotFound" 3 "Park_Out_SlotFound" 4 "Park_In_Intervention" 5 "Park_Out_Intervention" 6 "Standby" 7 "Completed" 8 "Cancelled" 9 "ParkIn_NoPass_FrontLeft" 10 "ParkIn_NoPass_FrontRight" 11 "ParkIn_NoPass_BackLeft" 12 "ParkIn_NoPass_BackRight" 13 "Not_Activatable" 14 "Remote_Activation" 15 "Remote_HandingOver" 16 "Remote_In_Intervention" 17 "Remote_Out_Intervention" ;
VAL_ 2463978866 PLAIPA_PaCo_MainState 0 "Init" 1 "InOperation_NoError" 7 "Fehler" ;
VAL_ 2463978866 KLR_Touchauswertung 0 "Keine_Beruehrung" 1 "Leicht_beruehrt_innen" 2 "Leicht_beruehrt_links" 3 "Leicht_beruehrt_rechts" 4 "Leicht_beruehrt_links_rechts" 5 "Leicht_umgriffen_links" 6 "Leicht_umgriffen_rechts" 7 "Leicht_umgriffen_links_rechts" 8 "Stark_umgriffen_links" 9 "Stark_umgriffen_rechts" 10 "Stark_umgriffen_links_rechts" 11 "res" 12 "res" 13 "Kalibrierung" 14 "Init" 15 "Fehler_Touchauswertung" ;
VAL_ 2463978866 TPA_Status 0 "Deaktiv" 1 "Init" 2 "Passiv" 3 "Aktiv_Parkvorganginitiierung_AP" 4 "Aktiv_Aufnahme_Lokalisierung" 5 "Aktiv_Parkvorganginitiierung" 6 "Aktiv_Einparkvorgang" 7 "Aktiv_Ausparkvorgang" 8 "Aktiv_Zielposition_EP_erreicht" 9 "Aktiv_Zielposition_AP_erreicht" 10 "Vorruhe" 15 "Error" ;
VAL_ 2463978866 ARA_Status 0 "ARA_Status_inaktiv" 1 "ARA_Status_init" 2 "Fehler" 3 "ARA_Status_Start" 4 "ARA_Status_aktiv" 6 "ARA_Status_Regelung_aktiv" 8 "ARA_Status_betriebsbereit" 9 "ARA_Status_Klemmtraeger_erkannt" 10 "ARA_Status_Abbruch" 11 "ARA_Status_nicht_betriebsbereit" ;
VAL_ 2463978866 TA_Texte_02 0 "Keine_Anzeige" 1 "TA_zur_Zeit_nicht_aktivierbar" 2 "Zurzeit_nur_Spurfuehrung_verfueg" 3 "Fahreruebernahme_stumm" 4 "Fahreruebernahme_leise" 5 "Systemgrenzenwarnung" 6 "Fehler_TA_Low_keine_Sensorsicht" 7 "Fehler_TA_High_keine_Sensorsicht" 8 "Reserved_08" 9 "Reserved_09" 10 "Reserved_10" 11 "Reserved_11" 12 "Reserved_12" 13 "Reserved_13" 14 "Reserved_14" 15 "Reserved_15" ;
VAL_ 2463978866 TA_Texte 0 "Keine_Anzeige" 1 "Nicht_verfuegbar" 2 "Modus_TA_m_ass_Spurwechsel_gewae" 3 "Modus_ACC_ausgewaehlt" 4 "Modus_TravelAssist_ausgewaehlt" 5 "Spurwechsel_nicht_verfuegbar" 6 "Spurwechsel_abgebrochen" 7 "Spurw_abgebr_Lenkung_uebernehmen" ;
VAL_ 2463978866 TA_Handsoff_LED 0 "keine_Anzeige" 1 "weiss" 2 "rot" 3 "reserviert" ;
VAL_ 2463978866 TA_Fehler 0 "kein_Fehler" 1 "Fehler_TA_Low" 2 "Fehler_TA_Low_keine_Sensorsicht" 3 "Fehler_TA_High" 4 "Fehler_TA_High_keine_Sensorsicht" ;
VAL_ 2463978866 TA_aktiv_HMI 0 "nicht_aktiv" 1 "TA_Low_aktiv" 2 "TA_High_aktiv" ;
VAL_ 2463978866 TA_Spurwechsel 0 "Kein_Spurwechsel" 1 "Spurwechsel_links" 2 "Spurwechsel_rechts" 3 "Spurwechselfreigabe_links" 4 "Spurwechselfreigabe_rechts" 5 "TA_Modus_StandBy" 6 "Spurwechselfreigabe_li_und_re" ;
VAL_ 2463978866 VZE_Status_EDR 0 "Commanded_Off" 1 "On_but_Not_ControllingOrWarning" 2 "Actively_Warning" 3 "Actively_Controlling" 4 "Driver_Override" 5 "Faulted" ;
VAL_ 2463978866 TPMS_WarnLmpStP 0 "TPMS_Warning_lamp_P_inactive" 1 "TPMS_Warning_lamp_P_active" ;
VAL_ 2463978866 RDK_FMVSS138_Lampe 0 "RDK_WaLa_inaktiv" 1 "RDK_WaLa_aktiv" ;
VAL_ 2463978866 LDW_Status_Anzeige 0 "Init_keine_Anzeige" 1 "Lenkeingriff" 2 "Deaktiviert" 3 "Passiv" 4 "Aktiv" 5 "Passiv_automatisch" 6 "nicht_definiert" 7 "nicht_definiert" ;
VAL_ 2463978866 TPMS_WarnLmpStMil 0 "TPMS_fault_indicator_inactive" 1 "TPMS_fault_indicator_active" ;
VAL_ 2463978866 RDK_FMVSS138_MIL 0 "keine_Stoerungsanzeige" 1 "Stoerungsanzeige" ;
VAL_ 2463978866 RA_Status 0 "Nicht_freigeschaltet" 1 "Init" 2 "Nicht_Verfuegbar" 3 "Abbruch" 4 "Verfuegbar" 5 "Aufzeichnend" 6 "Aktivierend" 7 "Fahreruebernahme" 8 "Beendet" 9 "In_Regelung" 15 "Error" ;
VAL_ 173 GE_Fahrstufe 0 "Zwischenstellung" 1 "Init" 5 "Position_P" 6 "Position_R" 7 "Position_N" 8 "Position_D" 9 "Position_S" 10 "Effizienz" 13 "Tipp_in_S" 14 "Tipp_in_D" 15 "Fehler" ;
VAL_ 173 GE_Ursache_Fahrstufe_N 0 "Fahrstufe_N_mit_Fahrerwunsch" 1 "Fahrstufe_N_ohne_Fahrerwunsch" ;
VAL_ 270 GE_MMom_Soll_02 1022 "keine_Anforderung_Init" 1023 "Fehler" ;
VAL_ 270 GE_MMom_Vorhalt_02 1022 "Init" 1023 "Fehler" ;
VAL_ 270 GE_Uefkt 1023 "Fehler" ;
VAL_ 270 GE2_Fahrstufe 0 "Zwischenstellung" 1 "Init" 5 "Position_P" 6 "Position_R" 7 "Position_N" 8 "Position_D" 9 "Position_S" 10 "Effizienz" 13 "Tipp_in_S" 14 "Tipp_in_D" 15 "Fehler" ;
VAL_ 270 GE2_Ursache_Fahrstufe_N 0 "Fahrstufe_N_mit_Fahrerwunsch" 1 "Fahrstufe_N_ohne_Fahrerwunsch" ;
VAL_ 270 GE_Schaltablauf 0 "keine_Schaltung" 1 "Momentenueberschneidung" 2 "Befuellphase" 3 "Drehzahlueberfuehrung" ;
VAL_ 270 GE_Uefkt_unplausibel 0 "Uefkt_plausibel" 1 "Uefkt_unplausibel" ;
VAL_ 270 GE_MMom_Status_02 0 "kein_Eingriff" 1 "abs_reduzierender_Eingriff_auf_Gesamt_Antrieb_nur_schneller_Pfad" 2 "abs_erhoehender_Eingriff_auf_Gesamt_Antrieb" 3 "relativer_Eingriff_auf_Gesamt_Antrieb" 4 "relativer_Eingriff_auf_E_Maschine" 5 "abs_red_Eingr_auf_Gesamt_Antrieb_nur_Luftpfad" 6 "abs_red_Eingr_auf_Gesamt_Antrieb_Luft-_und_schnellen_Pfad" 7 "abs_Eingriff_auf_Gesamtantrieb_erhoehend_und_reduzierend" ;
VAL_ 270 GE_Status_Kraftschluss 0 "offen_kein_Kraftschluss" 1 "offen_mit_Kraftschluss" 2 "schlupfend_geregelt" 3 "abgesichert_offen_kein_Kraftschl" 4 "geschlossen_mit_Mikroschlupf" 5 "geschlossen_mit_Ueberanpressung" 6 "sonstige_Fehler" 7 "fehlerhaft_geschlossen" ;
VAL_ 270 GE_MMom_Status 0 "keine Anforderung" 1 "reduzierender Getriebeeingriff" 2 "erhöhender Getriebeeingriff" 3 "Änderung mit Sprung" ;
VAL_ 270 GE_Freig_MMom_Vorhalt 0 "nicht_freigegeben" 1 "freigegeben" ;
VAL_ 270 GE_Verbot_Ausblendung 0 "kein_Verbot" 1 "Verbot" ;
VAL_ 270 GE_Zielgang 0 "Gang P/N (ausgekuppelt)" 1 "Gang 1" 2 "Gang 2" 3 "Gang 3" 4 "Gang 4" 5 "Gang 5" 6 "Gang 6" 7 "Gang 7" 8 "Gang R" 11 "Gang 8" 12 "Gang 9" 13 "Gang10" 14 "Istgang nicht definiert" 15 "Fehler" ;
VAL_ 270 GE_Fahrstufenwunsch 0 "Zwischenstellung" 1 "Init" 5 "Position_P" 6 "Position_R" 7 "Position_N" 8 "Position_D" 9 "Position_S" 10 "Effizienz" 13 "Tipp_in_S" 14 "Tipp_in_D" 15 "Fehler" ;
VAL_ 270 GE_Drehzahlmesser_Daempfung 0 "normale Dämpfung" 1 "dynamische Dämpfung" ;
VAL_ 270 GE_Schubabschalt_Unt 0 "inaktiv" 1 "aktiv" ;
VAL_ 270 GE_Freigabe_Synchro 0 "inaktiv" 1 "aktiv" ;
VAL_ 270 GE_Synchro_Wunschdrehz 0 "Init_kein_Eingriff" 511 "Fehler" ;
VAL_ 270 GE_Synchro_Zeit 255 "Fehler" ;
VAL_ 270 GE_Mom_Begr_Gradient 255 "Init" ;
VAL_ 270 GE_Anheb_Solldrehz_Leerlauf 255 "Fehler" ;
VAL_ 270 GE_Aufnahmemoment 1022 "Init_bzw_Wert_nicht_ermittelbar" 1023 "Fehler" ;
VAL_ 270 GE_Synchro_Status_02 0 "kein_Eingriff" 1 "Eingr_Gesamtantrieb_Param1" 2 "Eingr_Gesamtantrieb_Param2" 3 "Eingr_Gesamtantrieb_Param3" 4 "Eingr_Gesamtantrieb_Param4" 5 "Eingr_auf_E-Maschine" 6 "Drehzahlbegrenzung" 7 "Eingr_Gesamtantrieb_Param5" 8 "Eingr_Gesamtantrieb_Param6" 9 "Eingr_Gesamtantrieb_Param7" 10 "Eingr_Gesamtantrieb_Param8" 11 "Vorgest_Einspritzausblendung" ;
VAL_ 270 GE_StartStopp_Info 0 "Motorlauf_nicht_notwendig_(Stoppfreigabe)" 1 "Motoranlauf_nicht_zwingend_notwendig_(Stoppverbot,keine_Startanforderung)" 2 "Motoranlauf_zwingend_notwendig_(Startanforderung)" 3 "Systemfehler" ;
VAL_ 270 GE_Langfr_Schutzmom_02 510 "Init" 511 "Fehler" ;
VAL_ 270 GE_Entkopplung_Status 0 "keine_Entkopplung" 1 "Entkopplungsvorgang_gestartet" 2 "Entkopplungszustand_erreicht" 3 "Entkopplung_nicht_moeglich" ;
VAL_ 270 GE_Verlustmoment 255 "Fehler" ;
VAL_ 270 GE_Anf_Zylabsch 0 "Umschaltung_erlaubt" 1 "Umschaltung_verboten" 3 "VMB_Empfehlung" ;
VAL_ 270 GE_Grenzkriechmoment 62 "Init" 63 "Fehler" ;
VAL_ 270 GE_Eingangsdrehz 16382 "Init" 16383 "Fehler" ;
VAL_ 270 GE_Notlauf 0 "kein Notlauf / Init" 1 "Getriebe im Notlauf" ;
VAL_ 270 GE_Freig_Langfr_Schutzmom 0 "nicht_freigegeben" 1 "freigegeben" ;
VAL_ 270 GE_HYB_Fehlerstatus 0 "kein_Fehler" 1 "kein_Hydraulikdruck" 2 "Anforderung_N_gleich_0" 3 "beide_Fehler" ;
VAL_ 270 GE_HYB_DZ_Eingriff 0 "kein_Drehzahleingriff" 1 "Slip_Start" 2 "Low_Speed_Modus" ;
VAL_ 270 GE_HYB_Freigabe_K0 0 "Freigabe_K0_oeffnen" 1 "Freigabe_K0_schliessen" ;
VAL_ 270 GE_HYB_MaxMomK0 0 "keine_Reduktion" 1 "Reduktionsstufe_1" 2 "Reduktionsstufe_2" 3 "Reduktionsstufe_3" ;
VAL_ 270 GE_HYB_Freig_VM_EM_Stop 0 "VM_EM_darf_nicht_stoppen" 1 "VM_EM_darf_stoppen" ;
VAL_ 270 GE_HYB_Wiederstart 0 "kein_Wiederstart_aktiv" 1 "Wiederstart_aktiv" ;
VAL_ 270 GE_HYB_Filt_MomAufbau 0 "keine_Beeinflussung_der_Filterung_durch_Getriebe" 1 "multiplikative_Konstante_fuer_MSG" 2 "multiplikative_Konstante_fuer_MSG" 3 "multiplikative_Konstante_fuer_MSG" 4 "multiplikative_Konstante_fuer_MSG" 5 "multiplikative_Konstante_fuer_MSG" 6 "multiplikative_Konstante_fuer_MSG" 7 "multiplikative_Konstante_fuer_MSG" ;
VAL_ 270 GE_HYB_nK0 255 "Fehler" ;
VAL_ 270 GE_HYB_IstStatus_K0 0 "auf" 1 "Uebergang" 2 "zu" 3 "Fehler" ;
VAL_ 270 GE_HYB_VM_Soll_Moment 254 "kein_Eingriff" 255 "Fehler" ;
VAL_ 270 GE_HYB_Sportfaktor 0 "nicht_sportlich" ;
VAL_ 270 GE_HYB_Freigabe_LL_Reg 0 "keine_DZ_reg_erlaubt" 1 "LL_Reg_freigegeben" ;
VAL_ 270 GE_HYB_VM_akt_halten 0 "keine_Empfehlung" 1 "VM_aktiv_halten_starten" ;
VAL_ 270 GE_HYB_StartAnf 0 "keine_Startanforderung" 1 "Startanforderung" ;
VAL_ 270 GE_HYB_VM_Startkontr 0 "VM_StartAnf_nicht_freigegeben" 1 "VM_StartAnf_freigegeben" ;
VAL_ 270 GE_Radmoment 65534 "Init" 65535 "Fehler" ;
VAL_ 270 GE_Abtriebsdrehzahl 65534 "Init" 65535 "Fehler" ;
VAL_ 270 GE_Eingangswellengradient 65534 "Init" 65535 "Fehler" ;
VAL_ 509 GE_OBD_AbsperrVent 0 "kein Fehler / Init / nicht verbaut" 1 "KS- (Kurzschluss nach minus)" 2 "KS+ (Kurzschluss nach plus)" 3 "OC (Leitungsunterbrechung)" 4 "OOR+ (Signal zu gross)" 5 "OOR- (Signal zu klein)" 6 "RC+ (Signal unplausibel zu gross)" 7 "RC- (Signal unplausibel zu klein)" 8 "KS+/OC (Kurzschluss nach plus/Unterbrechung)" 9 "KS-/OC  (Kurzschluss nach minus/Unterbrechung)" 10 "KS-/KS+  (Kurzschluss nach minus/plus)" 11 "KS-/KS+/OC (Kurzschluss nach minus/plus/Unterbrechung)" 12 "Position_unbekannt" 13 "Failsafe_Position" 14 "Referenzfahrt_aktiv" 15 "frei" ;
VAL_ 509 GE_amax_moeglich 511 "nicht_definiert" ;
VAL_ 509 GE_Charisma_FahrPr 0 "keine_Funktion" 1 "Programm_1" 2 "Programm_2" 3 "Programm_3" 4 "Programm_4" 5 "Programm_5" 6 "Programm_6" 7 "Programm_7" 8 "Programm_8" 9 "Programm_9" 10 "Programm_10" 11 "Programm_11" 12 "Programm_12" 13 "Programm_13" 14 "Programm_14" 15 "Programm_15" ;
VAL_ 509 GE_Charisma_Status 0 "Init" 1 "verfuegbar" 2 "nicht_verfuegbar" 3 "asynchron_durch_Fahrerwunsch" ;
VAL_ 509 GE_Freigabe_Verfallsinfo_WFS 0 "Aus" 1 "Ein" ;
VAL_ 509 Freilauf_Charisma_FahrPr 0 "keine_Funktion" 1 "Programm_1" 2 "Programm_2" 3 "Programm_3" 4 "Programm_4" 5 "Programm_5" 6 "Programm_6" 7 "Programm_7" 8 "Programm_8" 9 "Programm_9" 10 "Programm_10" 11 "Programm_11" 12 "Programm_12" 13 "Programm_13" 14 "Programm_14" 15 "Programm_15" ;
VAL_ 509 Freilauf_Charisma_Status 0 "Init" 1 "verfuegbar" 2 "nicht_verfuegbar" 3 "asynchron_durch_Fahrerwunsch" ;
VAL_ 509 GE_Freigabe_Info_WFS 0 "ungueltig" 1 "gueltig" ;
VAL_ 509 GE_Sperr_Info_WFS 0 "nicht_gesperrt" 1 "gesperrt" ;
VAL_ 509 GE_Zustand_Kuppltemp 0 "Init" 1 "Kupplungstemp_normal" 2 "Kupplungstemp_hoch" 3 "Kupplungsschutz_aktivieren" ;
VAL_ 509 GE_Codierung_MSG 0 "Codierung iO / Init" 1 "Codierung niO" ;
VAL_ 509 GE_LaunchControl 0 "inaktiv" 1 "aktiv" ;
VAL_ 509 GE_Heizwunsch 0 "maximaler_Waermebedarf" 1 "kein_Waermebedarf" 2 "Kuehlbedarf" 3 "Notfall_(maximaler_Kuehlbedarf)" ;
VAL_ 509 GE_OBD_Status 0 "MIL aus" 1 "MIL ein" ;
VAL_ 509 GE_LFR_Adaption 0 "fuer_Adaption_geeignet" 1 "fuer_Adaption_nicht_geeignet" ;
VAL_ 509 GE_Sumpftemperatur 255 "Fehler" ;
VAL_ 509 GE_Schleuderoeltemperatur 254 "Init" 255 "Fehler" ;
VAL_ 509 GE_Weckleitung_aktiv 0 "inaktiv" 1 "aktiv" ;
VAL_ 509 GE_Fahrprogramm 0 "Init" 1 "nicht_belegt" 2 "Normal" 3 "Sport" 4 "Offroad" 5 "Efficiency" 6 "Sport_Plus" 7 "Sport_Response" 10 "Snow" 11 "Gravel" 12 "Mud_Ruts" 13 "Sand_Dune" ;
VAL_ 509 GE_TippZustand 0 "Init_Kein_Tipp" 1 "Tipp_permanent" 2 "Tipp_temporaer" ;
VAL_ 509 GE_Freilauf_Status 0 "Freilauf_inaktiv_aber_moeglich" 1 "Freilauf_aktiv" 2 "Freilauf_nicht_moegl_1Verhinderer" 3 "Freilauf_nicht_moegl_gr_1Verhinderer" 7 "Fehler" ;
VAL_ 509 GE_Grundeinstellung 0 "inaktiv" 1 "aktiv" ;
VAL_ 509 GE_Anschleppstart_Freigabe 0 "keine_Freigabe" 1 "Freigabe" ;
VAL_ 509 GE_Strombedarf_erh 0 "keine_Anforderung" 1 "erhoehte_Anforderung" ;
VAL_ 509 GE_Parken_WFS_Status 0 "Limitierung_Inaktiv" 1 "Limitierung_Aktiv" 2 "Abbruch" ;
VAL_ 509 FSA_Fehlerstatus_Parksperre 0 "Init" 1 "Parksperre_iO" 2 "Parksperre_eingeschraenkt" 3 "Parksperre_defekt" ;
VAL_ 509 GE_SpannungsAnf 0 "keine_Anforderung" 1 "Anforderung_Stufe1" 2 "Anforderung_Stufe2" 3 "Anforderung_Stufe3" ;
VAL_ 509 GE_QBit_Sumpftemperatur 0 "gueltiger_Wert" 1 "Ersatz_Init_oder_Fehlerwert" ;
VAL_ 509 GE_Grundeinstell_Drehrichtung_EM 0 "keine_Vorgabe" 1 "rueckwaerts" ;
VAL_ 509 GE_Veto_Rollfaehigkeit 0 "kein_Veto__Rollfaehigkeit_moegl" 1 "Veto__Rollfaehigkeit_nicht_moegl" ;
VAL_ 509 GE_Parken_beibehalten_HMS 0 "Parken_nicht_beibehalten" 1 "Parken_beibehalten" 2 "Init" 3 "Fehler" ;
VAL_ 509 GE_Anforderung_HMS 0 "keine_Anforderung" 1 "halten" 2 "parken" 3 "halten_Standby" 4 "anfahren" 5 "Loesen_ueber_Rampe" ;
VAL_ 509 GE_Betaetigung_Hold 0 "kein_Hold" 1 "Hold_aktivieren" ;
VAL_ 891 GNSS_UTC_Zeit 0 "Init" ;
VAL_ 891 GNSS_Empfaenger_Status 0 "Backup_Mode" 1 "Live" ;
VAL_ 891 GNSS_GPS_in_Nutzung 0 "unbenutzt" 1 "benutzt" ;
VAL_ 891 GNSS_GLONASS_in_Nutzung 0 "unbenutzt" 1 "benutzt" ;
VAL_ 891 GNSS_Empfangbare_Satelliten 0 "Init" 31 "31_oder_mehr" ;
VAL_ 891 GNSS_Sichtbare_Satelliten 0 "Init" 31 "31_oder_mehr" ;
VAL_ 891 GNSS_Genutzte_Satelliten 0 "Init" 31 "31_oder_mehr" ;
VAL_ 771 HCA_QFK_AnfStat 1 "Init" 2 "Bereit" 4 "Eingriff" ;
VAL_ 771 HCA_QFK_KruemmSoll_VZ 0 "positiv" 1 "negativ" ;
VAL_ 771 HCA_03_Sendestatus 0 "langsamer_Zyklus" 1 "schneller_Zyklus" ;
VAL_ 771 HCA_QFK_KrSoll_VZ 0 "positiv" 1 "negativ" ;
VAL_ 771 HCA_QFK_KrSoll 65535 "Init" ;
VAL_ 626 HVLM_Aktive_Ladeart 0 "Kein_Laden_aktiv" 1 "AC_Laden_aktiv" 2 "DC_Laden_aktiv" 3 "AWC" 4 "Reserve" 5 "Reserve" 6 "Reserve" 7 "Fehler" ;
VAL_ 626 HVLM_Pulsierstufe 0 "keine_Anforderung" 1 "Stufe_0" 2 "Stufe_1" 3 "Stufe_2" 4 "Stufe_3" 5 "Stufe_4" 6 "Stufe_5" 7 "Stufe_6" ;
VAL_ 626 HVLM_Intensitaet_Lk2 126 "Init" 127 "Fehler" ;
VAL_ 626 HVLM_Anforderung_HMS 0 "keine_Anforderung" 1 "halten" 2 "parken" 3 "halten_Standby" 4 "anfahren" 5 "Loesen_ueber_Rampe" ;
VAL_ 626 HVLM_Parken_beibehalten_HMS 0 "Parken_nicht_beibehalten" 1 "Parken_beibehalten" 2 "Init" 3 "Fehler" ;
VAL_ 626 HVLM_WakeUpZaehlerResetAnf 0 "keine_Anforderung" 1 "Reset_Zaehler" ;
VAL_ 626 HVLM_AWC_VerbautStatus 0 "Init" 1 "nicht_verbaut" 2 "verbaut" 3 "Fehler" ;
VAL_ 626 HVLM_Steckerstatus_A 0 "Init" 1 "kein_Stecker_erkannt" 2 "Stecker_steckt_nicht_verriegelt" 3 "Stecker_steckt_und_verriegelt" 7 "Fehler" ;
VAL_ 626 HVLM_Steckerstatus_B 0 "Init" 1 "kein_Stecker_erkannt" 2 "Stecker_steckt_nicht_verriegelt" 3 "Stecker_steckt_und_verriegelt" 7 "Fehler" ;
VAL_ 626 HVLM_Start_Pulserkennung 0 "keine_Anforderung" 1 "Pulserkennung_starten" ;
VAL_ 626 HVLM_ZustandLadeablauf 0 "Init" 1 "Stby_Ladevorbed_erfuellt" 2 "Stby_Ladevorbed_nicht_erfuellt" 3 "Fehler" 4 "Laden_starten" 5 "Laden_beenden" 6 "HVBatterie_Laden" 7 "HVBatterie_Entladen" 8 "Erhaltungsladen" ;
VAL_ 626 HVLM_DC_Aufstartmodus 0 "keine_Anforderung" 1 "Angleich_Fahrzeug" 2 "Angleich_LS_1" 3 "Angleich_LS_2" ;
VAL_ 626 HVLM_Ladeszenario 0 "Aus" 1 "Timerladen_abgeschlossen" 2 "Sofortladen_abgeschlossen" 3 "Optimiertes_Laden_abgeschlossen" 4 "Timerladen_aktiv" 5 "Sofortladen_aktiv" 6 "Optimiertes_Laden_aktiv" 7 "Timerladen_warten" 8 "Optimiertes_Laden_warten" 9 "Keine_Netzspannung" 10 "Fehler_Verriegelung" 11 "Fehler_Ladesytem" 12 "Init_Ladekommunikation" 15 "Notladen" 16 "Ladeunterbrechung_Kunde" 17 "Stecker_abziehbar" 18 "Kompatibilitaets_Umschaltung_aktiv" 30 "Init" 31 "Fehler" ;
VAL_ 626 HVLM_Ladevorgang_Anf 0 "Laden_nicht_angefordert" 1 "AC_Laden_Angefordert" 2 "DC_Laden_Angefordert" 3 "AC_und_DC_Angefordert" 4 "Induktiv_Laden_Angef" 5 "AC_und_Induktiv_Angef" 6 "DC_und_Induktiv_Angef" 7 "AC_DC_und_Induktiv_Angef" ;
VAL_ 626 HVLM_Intensitaet_Lk1 126 "Init" 127 "Fehler" ;
VAL_ 626 HVLM_Laden_ISO_Messung_Anf 0 "Anforderung" 1 "keine_Anforderung" ;
VAL_ 2589283966 IMU_StObd_StFail1 0 "Test_passed" 1 "Test_failed" ;
VAL_ 2589283966 IMU_StObd_StFail2 0 "Test_passed" 1 "Test_failed" ;
VAL_ 2589283966 IMU_StObd_StFail3 0 "Test_passed" 1 "Test_failed" ;
VAL_ 2589283966 IMU_StObd_StFail4 0 "Test_passed" 1 "Test_failed" ;
VAL_ 2589283966 IMU_StObd_StFail5 0 "Test_passed" 1 "Test_failed" ;
VAL_ 2589283966 IMU_StObd_StFail6 0 "Test_passed" 1 "Test_failed" ;
VAL_ 2589283966 IMU_StObd_StFail7 0 "Test_passed" 1 "Test_failed" ;
VAL_ 2589283966 IMU_StObd_StFail8 0 "Test_passed" 1 "Test_failed" ;
VAL_ 2589283966 IMU_StObd_StFail9 0 "Test_passed" 1 "Test_failed" ;
VAL_ 2589283966 IMU_StObd_StFail10 0 "Test_passed" 1 "Test_failed" ;
VAL_ 2589283966 IMU_StObd_StFail11 0 "Test_passed" 1 "Test_failed" ;
VAL_ 2589283966 IMU_StObd_StChk1 0 "Test_Completed" 1 "Test_Not_Completed" ;
VAL_ 2589283966 IMU_StObd_StChk2 0 "Test_Completed" 1 "Test_Not_Completed" ;
VAL_ 2589283966 IMU_StObd_StChk3 0 "Test_Completed" 1 "Test_Not_Completed" ;
VAL_ 2589283966 IMU_StObd_StChk4 0 "Test_Completed" 1 "Test_Not_Completed" ;
VAL_ 2589283966 IMU_StObd_StChk5 0 "Test_Completed" 1 "Test_Not_Completed" ;
VAL_ 2589283966 IMU_StObd_StChk6 0 "Test_Completed" 1 "Test_Not_Completed" ;
VAL_ 2589283966 IMU_StObd_StChk7 0 "Test_Completed" 1 "Test_Not_Completed" ;
VAL_ 2589283966 IMU_StObd_StChk8 0 "Test_Completed" 1 "Test_Not_Completed" ;
VAL_ 2589283966 IMU_StObd_StChk9 0 "Test_Completed" 1 "Test_Not_Completed" ;
VAL_ 2589283966 IMU_StObd_StChk10 0 "Test_Completed" 1 "Test_Not_Completed" ;
VAL_ 2589283966 IMU_StObd_StChk11 0 "Test_Completed" 1 "Test_Not_Completed" ;
VAL_ 182 IMU_ALat_Qlfr 0 "valid" 2 "crosschangeprotection_active" 3 "temporary_error" 4 "Sensor_module_error" 5 "Sensor_not_installed" 6 "Sensor_not_calibrated" 8 "power_supply_error" 14 "Init" 15 "Fehler" ;
VAL_ 182 IMU_ALat 0 "Sensor_not_installed" 65534 "Init" 65535 "Fehler" ;
VAL_ 182 IMU_ALgt 0 "Sensor_not_installed" 65534 "Init" 65535 "Fehler" ;
VAL_ 182 IMU_ALgt_Qlfr 0 "valid" 2 "crosschangeprotection_active" 3 "temporary_error" 4 "Sensor_module_error" 5 "Sensor_not_installed" 6 "Sensor_not_calibrated" 8 "power_supply_error" 14 "Init" 15 "Fehler" ;
VAL_ 182 IMU_PitchRate_Qlfr 0 "valid" 2 "crosschangeprotection_active" 3 "temporary_error" 4 "Sensor_module_error" 5 "Sensor_not_installed" 6 "Sensor_not_calibrated" 8 "power_supply_error" 14 "Init" 15 "Fehler" ;
VAL_ 182 IMU_PitchRate 0 "Sensor_not_installed" 65534 "Init" 65535 "Fehler" ;
VAL_ 182 IMU_AVert 0 "Sensor_not_installed" 65534 "Init" 65535 "Fehler" ;
VAL_ 182 IMU_AVert_Qlfr 0 "valid" 2 "crosschangeprotection_active" 3 "temporary_error" 4 "Sensor_module_error" 5 "Sensor_not_installed" 6 "Sensor_not_calibrated" 8 "power_supply_error" 14 "Init" 15 "Fehler" ;
VAL_ 182 IMU_YawRate_Qlfr 0 "valid" 2 "crosschangeprotection_active" 3 "temporary_error" 4 "Sensor_module_error" 5 "Sensor_not_installed" 6 "Sensor_not_calibrated" 8 "power_supply_error" 14 "Init" 15 "Fehler" ;
VAL_ 182 IMU_YawRate 0 "Sensor_not_installed" 65534 "Init" 65535 "Fehler" ;
VAL_ 182 IMU_RollRate 0 "Sensor_not_installed" 65534 "Init" 65535 "Fehler" ;
VAL_ 182 IMU_RollRate_Qlfr 0 "valid" 2 "crosschangeprotection_active" 3 "temporary_error" 4 "Sensor_module_error" 5 "Sensor_not_installed" 6 "Sensor_not_calibrated" 8 "power_supply_error" 14 "Init" 15 "Fehler" ;
VAL_ 182 IMU_MeasurementTimeLow 1023 "Init" ;
VAL_ 182 IMU_MeasurementTimeHigh 0 "Init" ;
VAL_ 312 IPA_Fahrstufenwunsch 0 "Init" 1 "Fahrstufe_beibehalten" 2 "Position_R" 3 "Position_D" 4 "Position_N" ;
VAL_ 312 IPA_Status 0 "Init" 4 "IPA_Anzeige_Aktiv" 5 "IPA_Fahreruebernahme" 6 "IPA_Aktiv" 7 "IPA_Standby" 8 "IPA_Funktionsbereit" 9 "IPA_PP_Aktivierung" 10 "IPA_Abbruch" 11 "IPA_Aktivierend" 15 "IPA_PP_Start" ;
VAL_ 2527679583 IPA_PL_Anzeige_links 0 "keine_PL_erkannt" 1 "links_Quer" 2 "links_Laengs" 3 "reserviert" ;
VAL_ 2527679583 IPA_PL_Anzeige_rechts 0 "keine_PL_erkannt" 1 "rechts_Quer" 2 "rechts_Laengs" 3 "reserviert" ;
VAL_ 2527679583 Parken_Seitenspiegel_Anf 0 "Keine_Anforderung" 1 "Seitenspiegel_anklappen" 2 "Seitenspiegel_abklappen" ;
VAL_ 2527679583 Parken_ZV_Schliessen 0 "Keine_Anforderung" 1 "ZV_verriegeln" 2 "ZV_safen" ;
VAL_ 2527679583 Parken_aktives_System_02 0 "Init" 1 "Keine_Aktivitaet" 2 "RPA" 3 "IPA" 4 "MA" 5 "TP" 6 "rTP" 7 "AAA" 8 "rAAA" 9 "ARA_1" 10 "PLA" 11 "RBF" 12 "PHP" 13 "RA" ;
VAL_ 2527679583 Parken_ZR_Sondermodus_Anf 0 "Init" 1 "Keine_Anforderung" 2 "Anforderung_Sondermodus" ;
VAL_ 2527679583 Parken_Schluesselsuche_Anf 0 "keine_Anforderung" 1 "Anforderung_Schluesselsuche" ;
VAL_ 2527679583 Parken_FFB_LED_Anf 0 "keine_Anforderung" 1 "Abbruch_Fehler" 2 "Bereit_OK" 3 "Beendet" ;
VAL_ 2527679583 Parken_Wegfahrsperren_Anf 0 "keine_Anforderung" 1 "Anforderung_Fahreruebernahme" 2 "Anforderung_Fahreruebergabe" ;
VAL_ 2527679583 Parken_Aktivierungslicht_Anf 0 "keine_Anforderung" 1 "Aktivierungslicht" ;
VAL_ 2527679583 Parken_Fahrtrichtungslicht_Anf 0 "keine_Anforderung" 1 "Vorwaerts" 2 "Rueckwaerts" ;
VAL_ 2527679583 Parken_Lichtnachlauf_Anf 0 "keine_Anforderung" 1 "Anforderung_Lichtnachlauf" ;
VAL_ 2527679583 IPA_Akustik_PL_gefunden 0 "keinen_Ton_ausgeben" 1 "Ton_ausgeben" ;
VAL_ 2527679583 Parken_Blinker_li_Anf 0 "keine_Anforderung" 1 "Blinker_links_aktivieren" ;
VAL_ 2527679583 Parken_Blinker_re_Anf 0 "keine_Anforderung" 1 "Blinker_rechts_aktivieren" ;
VAL_ 2527679583 Parken_Fahrerhinweise_Anf 0 "keine_Anforderung" 1 "Fahrerhinweise_anzeigen" ;
VAL_ 2527679583 Parken_Bestaetigungsblinken_Anf 0 "keine_Anforderung" 1 "Erfolgsblinken_Einparken" 2 "Abbruchsblinken" 3 "Erfolgsblinken_Ausparken" ;
VAL_ 2527679583 Parken_Fahrbereitschaftlicht_Anf 0 "keine_Anforderung" 1 "Fahrbereitschaftslicht" ;
VAL_ 2527679583 Parken_Lichtsteuerung_Anf 0 "keine_Anforderung" 1 "Automatik_Lichtmodus_aktivieren" ;
VAL_ 2527679583 IPA_Anf_Meldungen 0 "keine Meldung" 1 "beendet" 2 "Fahrinf_Bremse_FT_betaetigen" 3 "Suche_fortsetzen_ESC_Eingriff" 4 "n_a_temp_ESC_deaktiviert" 5 "n_a_temp_Anhaengerbetrieb" 6 "Suche_Zeitlimit_ueberschritten" 7 "Undefined" 8 "Fahrinf_PaLueSu_aufschalten" 9 "RPARemoteWunschAbgebrochen" 10 "IPAGeschwindigkeitReduzieren" 11 "IPARPAAktivierung2" 12 "AP_nicht_moeglich" 13 "RPAGarageStart" 14 "n_a_temp_Tuer_Heckklappe_offen" 15 "Stby_Tuer_Heckklappe_schliessen" 16 "PP_aktiv_nur_aussen_bedienbar" 17 "RPAUebergabe2" 18 "n_a_Offroad_Modus" 19 "PP_Schluessel_oder_App_bedienen" 20 "RPAUebergabe1" 21 "PP_Schluessel_bedienen" 22 "IPAAbbruchSuchfahrt" 23 "Systemstoerung_Service" 24 "n_a_temp_Sensorsicht" 25 "IPAAbbruchSuchfahrtLadestecke" 26 "IPAPausierenWeiterfahrt" 27 "n_a_temp_FAS_aktiv" 28 "PP_BT_unterbrochen" 29 "Hindernis_in_Fahrtrichtung" 30 "IPAAusparkenBlinker" 31 "RPAUebernahme" 32 "Suche_Rangierflaeche_zu_klein" 33 "n_a_temp_Drive_Select" 34 "IPAAktivierung1" 35 "Fahrinf_Fahrtrichtungswechsel" 36 "RPARemoteWunsch" 37 "GP_Fzgposition_vor_Garage" 38 "GP_RT_Garage_oeffnen" 39 "GP_Kein_Zuparken" 40 "Suche_Fahrinfo_beachten" 41 "GP_Fzgposition_freie_Parkflaeche" 42 "GP_n_a_temp_Laser" 43 "Geschwindigkeitsueberschreitung" 44 "Fahrinf_Weiter_vorfahren" 45 "RPAAktivierung1" 46 "Fahrinf_Anhalten" 47 "GP_AP_nicht_moeglich_Fahrweg" 48 "PP_Gang_Schluesselauthentifizier" 49 "Fahrhinweis_FT_betaetigen" 50 "PP_aktiv_Hinweis_FUEN" 128 "Disclaimer_LP_rechts" 129 "Disclaimer_LP_links" 130 "Disclaimer_RQ_rechts" 131 "Disclaimer_RQ_links" 132 "Disclaimer_VQ_rechts" 133 "Disclaimer_VQ_links" 134 "Disclaimer_AP_rechts" 135 "Disclaimer_AP_links" 136 "IPARPAAktivierung3" 137 "IPAAbbruchLenkeingriff" 138 "IPAAbbruchAnhaenger" 139 "IPARPAAktivierung4" 140 "IPAAbbruchZeitlimit" 141 "IPAFahrzeugAusgeparkt" 142 "IPAFahrzeugEingeparkt" 143 "IPAPausieren" 144 "IPAAbbruchESC" 145 "Stby_Verkehr_erkannt" 146 "MAAbbruchLenkeingriff" 147 "IPAAbbruchSchaltung" 148 "IPAAbbruchParklueckeKlein" 149 "IPABordsteinheber2" 150 "IPAAbbruchSensorsicht" 151 "Beendet_Stoerung_Fzgverbindung" 152 "Beendet_selbst_bremsen" 153 "IPAAbbruchFahrdynamischerEing" 154 "IPAAbbruchFalscheBewegungsric" 155 "IPAAbbruchDiETaSchliesskreuz" 156 "IPAPausierenHindernis" 157 "FUEN_moeglich" 158 "IPABordsteinheber4" 159 "IPAAbbruchOffroadModus" 160 "IPABordsteinheber5" 161 "PP_Fehler_Schluesselautorisier" 162 "IPABordsteinheber6" 163 "IPABordsteinheber7" 164 "Stby_FT_oder_RT_betaetigen" 165 "Stby_Hindernis_Richtungswechsel" 166 "Stby_erhoehter_Fahrwiderstand" 167 "Abbruch_EPB_aktiviert" 168 "Abbruch_MO_nicht_bereit" 169 "IPAAbbruchPDC" 170 "Abbruch_Gurtschloss_gesteckt" 171 "IPAAbbruchGeschwindigkeitHoch" 172 "IPAPausierenTueren" 173 "IPAAbbruchNotstopp" 174 "IPAAbbruchFahrerabwesenheit" 175 "IPAAbbruchSystempartner" 176 "PosOK_Lenkrad_loslassen_Bremse" 177 "PosOK_Lenkrad_loslassen_FT" 178 "Wiederaufnahme_FT_betaetigen" 179 "IPABordsteinheber9" 180 "IPAAbbruchKlemme15Aus" 181 "IPABordsteinheber8" 192 "TPA_aborted_deviated_from_trajec" 193 "TPA_aborted_limited_visibility" 194 "TPA_aborted_localization_failure" 195 "TPA_aborted_System_error" 196 "TPA_aborted_TPA_canceled" 197 "TPA_unavlbl_localization_failure" 198 "TPA_unavlbl_limited_visibility" 199 "TPA_unavlbl_System_error" 200 "TPA_temp_unavailable" 201 "rTPA_nicht_verfuegbar_TPA_bis_ZP" 202 "TPA_PP_belegt_TPA_Altern" 203 "TPA_PP_belegt_IPA_0_Altern" 204 "TPA_PP_belegt_IPA_1_Altern" 205 "TPA_PP_belegt_IPA_mehr_Altern" 206 "TPA_ausgerichtetes_Parken_aktiv" 207 "TPA_Ausparken_eingeschraenkt" ;
VAL_ 2527679684 Kamera_ASM_Ereignis 0 "No_Event" 255 "ASM_Trigger" ;
VAL_ 2527679684 Kamera_ASM_Zeitstempel_02 255 "Init" ;
VAL_ 960 RSt_Fahrerhinweise 0 "Init" 1 "Fahreruebernahme_Hinweis_ZAT_Automat_ohne_Gong" 2 "Fahreruebernahme_Hinweis_ZAT_Automat_mit_Gong" 3 "Fahreruebernahme_Hinweis_ZAT_Handschalter_ohne_Gong" 4 "Fahreruebernahme_Hinweis_ZAT_Handschalter_mit_Gong" 5 "Fahreruebernahme_Hinweis_ZAS_Automat_ohne_Gong" 6 "Fahreruebernahme_Hinweis_ZAS_Automat_mit_Gong" 7 "Fahreruebernahme_Hinweis_ZAS_Handschalter_ohne_Gong" 8 "Fahreruebernahme_Hinweis_ZAS_Handschalter_mit_Gong" 9 "RemoteStart_aktiv_ohne_Gong" 10 "RemoteStart_aktiv_mit_Gong" 11 "void" 12 "void" 13 "void" 14 "void" 15 "void" ;
VAL_ 960 ZAS_Kl_S 0 "aus" 1 "S_Kontakt_ein" ;
VAL_ 960 ZAS_Kl_15 0 "aus" 1 "ein" ;
VAL_ 960 ZAS_Kl_X 0 "aus" 1 "ein" ;
VAL_ 960 ZAS_Kl_50_Startanforderung 0 "aus" 1 "KL50_ein_Startwunsch_Fahrer" ;
VAL_ 960 BCM_Remotestart_Betrieb 0 "kein_RS_Betrieb" 1 "RS_Betrieb" ;
VAL_ 960 ZAS_Kl_Infotainment 0 "inaktiv" 1 "aktiv" ;
VAL_ 960 BCM_Remotestart_KL15_Anf 0 "inaktiv" 1 "aktiv" ;
VAL_ 960 BCM_Remotestart_MO_Start 0 "nicht_angefordert" 1 "angefordert" ;
VAL_ 960 KST_Warn_P1_ZST_def 0 "nicht_defekt" 1 "defekt" ;
VAL_ 960 KST_Warn_P2_ZST_def 0 "nicht_defekt" 1 "defekt" ;
VAL_ 960 KST_Fahrerhinweis_1 0 "inaktiv" 1 "aktiv" ;
VAL_ 960 KST_Fahrerhinweis_2 0 "inaktiv" 1 "aktiv" ;
VAL_ 960 BCM_Ausparken_Betrieb 0 "kein_Betrieb" 1 "Ausparkvorgang_aktiv" ;
VAL_ 960 KST_Fahrerhinweis_4 0 "inaktiv" 1 "aktiv" ;
VAL_ 960 KST_Fahrerhinweis_5 0 "inaktiv" 1 "aktiv" ;
VAL_ 960 KST_Fahrerhinweis_6 0 "inaktiv" 1 "aktiv" ;
VAL_ 2463978753 KST_WFS_Fahrfreigabe_Anforderung 0 "Keine" 1 "Uneingeschraenkt" 2 "Eingeschraenkt" ;
VAL_ 2463978753 KST_Sonderzustand_Status 0 "Init" 1 "Uebergang_neue_Anforderung" 2 "Aktiv" 3 "Fehler" ;
VAL_ 2463978753 KST_Sonderzustand_Anforderung 0 "Init" 1 "RemoteStart" 2 "RemoteParkAssist" 3 "IntelligentParkAssist" 4 "TrainiertesParken" 5 "OnlineRemoteUpdate" 6 "Einfrierschutz" 7 "Klemme15ViaDiagnose" 8 "RueckwandklappenSicherungPDC" 9 "ParkHausPilot" 10 "AnhaengerAnkuppelAssistent" 11 "MotorWeiterlaufSchaltung" 31 "Fehler" ;
VAL_ 2463978753 KST_ComfortReadyStatus 0 "aus" 1 "ComfortReadyStatus_ein" ;
VAL_ 2463978753 KST_Freigabe_Zustand 0 "Init" 1 "Kl50_freigegeben" 2 "Kl50_gesperrt" ;
VAL_ 1505 BCM1_Aussen_Temp_ungef 253 "nicht_verbaut" 254 "Initwert" 255 "Fehler" ;
VAL_ 1505 BCM_Heizungsabsperrventil_Status 0 "HAV_offen" 1 "HAV_geschlossen" 2 "Init_oder_nicht_verbaut" 3 "Fehler" ;
VAL_ 1505 BCM_Heizungspumpe_Status 0 "Pumpe_aus" 1 "Pumpe_aktiv_und_Stauts_iO" 2 "Init_oder_nicht_verbaut" 3 "Fehler" ;
VAL_ 1505 BCM_Kompressorkupplung_Status 0 "Kupplung_offen" 1 "Kupplung_geschlossen" 2 "Init_oder_nicht_verbaut" 3 "Fehler" ;
VAL_ 1505 BCM1_PTC_stufig_Status 0 "Aus" 1 "Stufe_1_aktiv" 2 "Stufe_2_aktiv" 3 "Stufe_3_aktiv" 6 "Init_oder_nicht_verbaut" 7 "Fehler" ;
VAL_ 1505 BCM1_FStatus_Aussentemp_ungef 0 "iO" 1 "niO" ;
VAL_ 1505 BCM1_Kompressorstrom_ist 254 "Init, bzw. nicht verfuegbar" 255 "Fehler" ;
VAL_ 1505 BCM1_OBD_FStatus_ATemp 0 "kein Fehler / Init / nicht verbaut" 1 "KS- (Kurzschluss nach minus)" 2 "KS+ (Kurzschluss nach plus)" 3 "OC (Leitungsunterbrechung)" 4 "OOR+ (Signal zu gross)" 5 "OOR- (Signal zu klein)" 6 "RC+ (Signal unplausibel zu gross)" 7 "RC- (Signal unplausibel zu klein)" 8 "KS+/OC (Kurzschluss nach plus/Unterbrechung)" 9 "KS-/OC  (Kurzschluss nach minus/Unterbrechung)" 10 "KS-/KS+  (Kurzschluss nach minus/plus)" 11 "KS-/KS+/OC (Kurzschluss nach minus/plus/Unterbrechung)" 12 "frei" 13 "frei" 14 "frei" 15 "frei" ;
VAL_ 2549088275 ESP_KompSchutz 0 "inaktiv" 1 "aktiv" ;
VAL_ 2549088275 ABS_Abschaltstufe 0 "keine_Einschraenkung" 1 "Funktionseinschraenkung" ;
VAL_ 2549088275 ABS_Transport_Mode 0 "keine_Einschraenkung" 1 "Funktionseinschraenkung" ;
VAL_ 2549088275 ESP_Nachlauftyp 0 "Komm_bei_KL15_EIN" 1 "Komm_nach_KL15_AUS" 2 "Komm_bei_KL15_AUS" ;
VAL_ 2549088275 KN_ESP_ECUKnockOutTimer 63 "ECUKnockOut_deaktiviert" ;
VAL_ 2549088275 KN_ESP_BusKnockOut 0 "Funktion_nicht_ausgeloest" 1 "Veto_aktiv" 2 "Funktion_ausgeloest" 3 "Funktion_deaktiviert" ;
VAL_ 2549088275 KN_ESP_BusKnockOutTimer 255 "BusKnockOut_deaktiviert" ;
VAL_ 2549088275 NM_ESP_Wakeup 0 "Peripherie_Wakeup__Ursache_nicht_bekannt" 1 "Bus_Wakeup" 2 "KL15_HW" 3 "KL30_Reset" 4 "Schalter_EPB" 5 "EPB_Nachspannen" 128 "Bewarnung" ;
VAL_ 2549088275 KN_ESP_ECUKnockOut 0 "Funktion_nicht_ausgeloest" 1 "Veto_war_aktiv" 2 "Funktion_ausgeloest" 3 "Funktion_deaktiviert" ;
VAL_ 2549088275 KN_ESP_DiagPfad 0 "aktiv" 1 "inaktiv" ;
VAL_ 2549088275 ESP_KD_Fehler 0 "kein_KD_Fehler" 1 "KD_Fehler" ;
VAL_ 2549088277 Airbag_01_KompSchutz 0 "inaktiv" 1 "aktiv" ;
VAL_ 2549088277 Airbag_01_Abschaltstufe 0 "keine_Einschraenkung" 1 "Funktionseinschraenkung" ;
VAL_ 2549088277 Airbag_01_Transport_Mode 0 "keine_Einschraenkung" 1 "Funktionseinschraenkung" ;
VAL_ 2549088277 Airbag_01_Nachlauftyp 0 "Komm_bei_KL15_EIN" 1 "Komm_nach_KL15_AUS" 2 "Komm_bei_KL15_AUS" ;
VAL_ 2549088277 KN_Airbag_01_ECUKnockOutTimer 63 "ECUKnockOut_deaktiviert" ;
VAL_ 2549088277 KN_Airbag_01_BusKnockOut 0 "Funktion_nicht_ausgeloest" 1 "Veto_aktiv" 2 "Funktion_ausgeloest" 3 "Funktion_deaktiviert" ;
VAL_ 2549088277 KN_Airbag_01_BusKnockOutTimer 255 "BusKnockOut_deaktiviert" ;
VAL_ 2549088277 NM_Airbag_01_Wakeup 0 "Peripherie_Wakeup_Ursache_nicht_bekannt" 1 "Bus_Wakeup" 2 "KL15_HW" 3 "Sitzbelegungserkennung_Fahrer" 4 "Gurtschlosserkennung_Fahrer" ;
VAL_ 2549088277 KN_Airbag_01_ECUKnockOut 0 "Funktion_nicht_ausgeloest" 1 "Veto_war_aktiv" 2 "Funktion_ausgeloest" 3 "Funktion_deaktiviert" ;
VAL_ 2549088277 KN_Airbag_01_DiagPfad 0 "aktiv" 1 "inaktiv" ;
VAL_ 2549088277 Airbag_01_KD_Fehler 0 "Kein_KD_Fehler" 1 "KD_Fehler" ;
